VERSION ""

NS_ :

BS_:

BU_: Sound_A Ladegeraet_PAG_PF Motor_EDC17_Pirol PSM_Ant_Derivate GW_Routing_Derivate GW_Applikation_Derivate BMS_Hybrid Getriebe_Derivate LEH_Hybrid Motor_MED17_Hybrid Sound_I Tool Airbag Waehlhebel
VAL_TABLE_ KBI_ASD_Ein_Aus 1 "An" 0 "Aus" ;
VAL_TABLE_ MO_Hybridfahrzeug 3 "PlugIn_Hybrid" 2 "Full_Hybrid" 1 "Mild_Hybrid" 0 "kein_Hybridfahrzeug" ;
VAL_TABLE_ KBI_Automem_inaktiv 1 "Automem nicht aktiv" 0 "Automem aktiv" ;
VAL_TABLE_ QBit 1 "Ersatz-, Init- oder Fehlerwert" 0 "gültiger Wert" ;
VAL_TABLE_ STH_Zusatzheizung 1 "Zuheizer ein" 0 "Zuheizer aus" ;
VAL_TABLE_ xT_Tuer_geoeffnet 1 "Tuer geoeffnet" 0 "Tuer nicht geoeffnet" ;
VAL_TABLE_ KL_Zuheizer_Freigabe 1 "Zuheizerfreigabe" 0 "keine Freigabe Zuheizer" ;
VAL_TABLE_ Fehler_7Bit 127 "Fehler" ;
VAL_TABLE_ AAG_Anhaenger_abgesteckt 1 "Anhaenger wurde bei Kl. 15 aus abgesteckt" ;
VAL_TABLE_ SI_QRS_Mode 0 "QRS_Messmodus_nicht_aktiv" 1 "QRS_Messmodus_aktiv" ;
VAL_TABLE_ KY_WFS_Safe 1 "WFS nicht deaktiviert" ;
VAL_TABLE_ KYL_Warn_kein_Schluessel 0 "kein Schlüssel erkannt" ;
VAL_TABLE_ KY_Keyless_Verbau 1 "Keyless verbaut" 0 "kein Keyless verbaut" ;
VAL_TABLE_ KY_Valet_Parking 1 "Valet Schlüssel erkannt" 0 "kein Valet Schlüssel erkannt" ;
VAL_TABLE_ BCM1_MH_WIV_Schalter 1 "MH offen" 0 "MH geschlossen" ;
VAL_TABLE_ GE_MMom_Status 3 "Änderung mit Sprung" 2 "erhöhender Getriebeeingriff" 1 "reduzierender Getriebeeingriff" 0 "keine Anforderung" ;
VAL_TABLE_ GE_MMom_Soll 1023 "Fehler" 1022 "kein Eingriff" ;
VAL_TABLE_ GE_Status_Kupplung 3 "Fehler" 2 "Kupplung geschlossen" 1 "Kupplung geregelt" 0 "Kupplung geöffnet" ;
VAL_TABLE_ GE_Schaltvorgang 1 "Schaltung aktiv" 0 "keine Schaltung" ;
VAL_TABLE_ WH_Warnung 1 "Waehlhebelfehler_Fahrstufenwechsel_moeglich_(gelbes_Getriebesymbol)" 0 "keine_Anzeige" ;
VAL_TABLE_ WBA_Lampe_Shift_Lock 1 "SL_Lampe_ein" 0 "SL_Lampe_aus" ;
VAL_TABLE_ WBA_Senderkennung 1 "Motor" 0 "Getriebe" ;
VAL_TABLE_ WBA_Getriebevariante 15 "9 Gang Automat Tiptronic" 14 "8 Gang Automat Tiptronic" 13 "7 Gang Automat Tiptronic" 12 "6 Gang Automat Tiptronic" 11 "5 Gang Automat Tiptronic" 10 "tbd." 9 "tbd." 8 "2x3 shift_by_wire" 7 "tbd." 6 "Automat PRNDS" 5 "tbd." 4 "Vorhalt für ASG (Selespeed)" 3 "tbd." 2 "tbd." 1 "Automat PRND" ;
VAL_TABLE_ WBA_eing_Gang 10 "9.Gang" 9 "8.Gang" 8 "7.Gang" 7 "6.Gang" 6 "5.Gang" 5 "4.Gang" 4 "3.Gang" 3 "2.Gang" 2 "1.Gang" 1 "Init" 0 "kein Gang eingelegt / kein Gang empfohlen" ;
VAL_TABLE_ WBA_Blinken 1 "WBA_Blinken" 0 "kein_WBA_Blinken" ;
VAL_TABLE_ WBA_GE_Warnung 7 "Kupplung ueberhitzt, Fahrzeug Stopp (+ rotes Getriebefehlersymbol)" 6 "Kupplung ueberhitzt, Fahrzeug Stopp (+ gelbes Getriebefehlersymbol)" 5 "Wegrollgefahr! P nicht möglich" 4 "Getriebefehler, Weiterfahrt nur in D moeglich, P bei Motor aus" 3 "nur DL-Getriebe: Weiterfahrt nur eingeschränkt möglich. Kein R-Gang" 2 "Weiterfahrt nur eingeschränkt möglich (+ gelbes Getriebefehlersymbol)" 1 "Weiterfahrt möglich (+ gelbes Getriebefehlersymbol)" 0 "keine Anzeige" ;
VAL_TABLE_ WBA_GE_Texte 4 "Achtung_Zeitueberschreitung_P_wird_eingelegt" 3 "Wegrollgefahr_bitte_P_einlegen" 2 "zum_Einlegen_von_R,N,D_Fussbremse_betaetigen_und_Motor_starten" 1 "zum_Einlegen_einer_Fahrstufe_Fussbremse_betaetigen__ShiftLock_Information" 0 "keine Anzeige" ;
VAL_TABLE_ Veraltet_Bit 1 "veraltet" 0 "aktuell" ;
VAL_TABLE_ KBI_Variante_USA 1 "USA-Variante" 0 "keine USA-Variante" ;
VAL_TABLE_ BCM2_Bremsl_durch_ECD 1 "Bremslicht_durch_ECD_aktiv" 0 "Bremslicht_ist_aus" ;
VAL_TABLE_ KL_Thermomanagement 3 "volle Freigabe TMM (kein Heizbedarf)" 2 "mittlere Freigabe TMM" 1 "kleine Freigabe TMM" 0 "keine Freigabe TMM (max. Heizbedarf)" ;
VAL_TABLE_ KL_Atemp_ungef 255 "Fehler" 0 "Initwert" ;
VAL_TABLE_ ACC_Abstandsindex 1023 "Sonderanzeige_Fahrbahn_mit_gruenem_roten_Bereich" 1022 "Sonderanzeige_graue_Fahrbahn" 0 "Sonderanzeige_graue_Fahrbahn" ;
VAL_TABLE_ DGN_Verlernzaehler 255 "ungültiger Zählerstand oder kein gültiger Fahrzyklus" ;
VAL_TABLE_ NMH_GE_N_Haltephase 1 "N_Haltephase_aktiv" 0 "keine_N_Haltephase" ;
VAL_TABLE_ WBA_Schaltschema_Aktiv 1 "Schaltschema_anzeigen" 0 "keine_Anzeige" ;
VAL_TABLE_ MO_HYB_IstStatusK0 3 "Fehler" 2 "zu" 1 "Uebergang" 0 "auf" ;
VAL_TABLE_ NMH_MO_NM_aktiv_HV_Abschaltung 1 "Abschaltung_aktiv" 0 "kein_Nachlauf" ;
VAL_TABLE_ MO_Text_Motorstart 11 "(Belegt bei VW/Audi)" 10 "(Belegt bei VW/Audi)" 9 "(Belegt bei VW/Audi)" 8 "(Vorhalt für Start/Stopp) " 7 "(Vorhalt für Start/Stopp) " 6 "(Vorhalt für Start/Stopp) " 5 "Start/Stopp temporär nicht verfügbar" 4 "Nicht belegt (Vorhalt AUDI)" 15 "Bremse treten" 14 "Waehlhebel in PN Position" 13 "Kupplung betaetigt" 12 "Motor startet" 3 "System fordert Wiederstart" 2 "StartStopp sicherheitsbedingt deaktiviert" 1 "Motor im Stoppbetrieb" 0 "keine Anzeige" ;
VAL_TABLE_ MO_StartStopp_Codiert 1 "StartStopp vorhanden/verbaut" 0 "StartStopp nicht vorhanden/verbaut" ;
VAL_TABLE_ KBI_WV_Entr_Kof 15 "80 Sek." 14 "75 Sek." 13 "70 Sek." 12 "65 Sek." 11 "60 Sek." 10 "55 Sek." 9 "50 Sek." 8 "45 Sek." 7 "40 Sek." 6 "35 Sek." 5 "30 Sek." 4 "25 Sek." 3 "20 Sek." 2 "15 Sek." 1 "10 Sek." 0 "Türen werden nicht entriegelt" ;
VAL_TABLE_ Basiscodierung 1 "Basiscodierung invertiert" 0 "Basiscodierung" ;
VAL_TABLE_ Fehler_Init_13Bit 8191 "Fehlerwert" 8190 "Initwert" ;
VAL_TABLE_ KBI_angez_Geschw 1023 "Fehlerwert" ;
VAL_TABLE_ ESP_SpannungsAnf 1 "Anforderung Spannungswert 1" 0 "keine Anforderung" ;
VAL_TABLE_ LS_Codierung 7 "nicht verwendet" 6 "nicht verwendet" 5 "ACC Hebel, Tiptronic am Lenkrad" 4 "ACC Hebel, keine Tiptronic am Lenkrad" 3 "GRA Hebel, Tiptronic am Lenkrad" 2 "GRA Hebel, keine Tiptronic am Lenkrad" 1 "kein Hebel, Tiptronic am Lenkrad" 0 "kein Hebel, keine Tiptronic am Lenkrad" ;
VAL_TABLE_ LS_Fehler 1 "Fehler Bedienteil" 0 "in Ordnung" ;
VAL_TABLE_ Tippschalter_betaetigt 1 "Tippschalter betaetigt" 0 "Tippschalter nicht betaetigt" ;
VAL_TABLE_ LS_Abbrechen 1 "Tippschalter betätigt" 0 "Tippschalter nicht betätigt" ;
VAL_TABLE_ LS_Hauptschalter 1 "Ein" 0 "Gerastet Aus" ;
VAL_TABLE_ AAG_Bremsl_durch_ECD 1 "Bremslicht durch ECD aktiv" 0 "Bremslicht ist aus" ;
VAL_TABLE_ HU_Fotosensor 511 "Fehler" 510 "Init" 0 "Sensor unbeleuchtet" ;
VAL_TABLE_ PDCC_Last_RKP 255 "Fehlerwert" 0 "Init" ;
VAL_TABLE_ KY_WFS_LZ 3 "LZ 3" 2 "LZ 2" 1 "LZ 1" 0 "nicht def." ;
VAL_TABLE_ Freigabe_angefordert 1 "Freigabe wird angefordert" 0 "Freigabe nicht angefordert" ;
VAL_TABLE_ entriegelt_nicht_entriegelt 1 "entriegelt" 0 "nicht entriegelt" ;
VAL_TABLE_ verriegelt_nicht_verriegelt 1 "verriegelt" 0 "nicht verriegelt" ;
VAL_TABLE_ KY_FFB_Frequenz 3 "868 MHz" 2 "315 MHz" 1 "433 MHz" ;
VAL_TABLE_ KY_ID_Geb_steckt 1 "Schlüssel steckt im Zündschloss" 0 "kein Schlüssel im Zündschloss" ;
VAL_TABLE_ FFB_Taste_betaetigt 1 "Taste am Funkschlüssel betätigt" 0 "Taste nicht betätigt" ;
VAL_TABLE_ authorisiert_nicht_authorisiert 1 "authorisiert" 0 "nicht authorisiert" ;
VAL_TABLE_ OK_Defekt 1 "defekt" 0 "OK" ;
VAL_TABLE_ KL_4_Zonen 1 "4_Zonen_Klimaanlage" 0 "2_Zonen_Klimaanlage" ;
VAL_TABLE_ AB_RGS_Anst 8 "deaktiviert" 7 "aktiv_Niveau_4" 6 "aktiv_Niveau_3" 5 "aktiv_Niveau_2" 4 "aktiv_Niveau_1" ;
VAL_TABLE_ AB_Texte_AKS 2 "AKS_Systemfehler" 1 "AKS_ausgeloest" 0 "keine_AKS_Ausloesung" ;
VAL_TABLE_ SI_NWDF_gueltig 1 "NWDF_wird_unterstuetzt" 0 "NWDF_wird_nicht_unterstuetzt" ;
VAL_TABLE_ SI_NWDF 1 "Ueberwachung_freigeben" 0 "Ueberwachung_nicht_freigeben" ;
VAL_TABLE_ MO_Ext_E_Fahrt_aktiv 1 "Rueckmeldung_E_Taster_ein" 0 "Rueckmeldung_E_Taster_aus" ;
VAL_TABLE_ KL_Geblaese_Status 15 "Fehler" 14 "Init" 10 "Geblaese Stufe 100%" 9 "Geblaese Stufe 90%" 8 "Geblaese Stufe 80%" 7 "Geblaese Stufe 70%" 6 "Geblaese Stufe 60%" 5 "Geblaese Stufe 50%" 4 "Geblaese Stufe 40%" 3 "Geblaese Stufe 30%" 2 "Geblaese Stufe 20%" 1 "Geblaese Stufe 10%" 0 "Geblaese aus" ;
VAL_TABLE_ KBI_Kilometerstand 1048575 "Fehlerwert" 1048574 "Initwert" ;
VAL_TABLE_ Warnmeldung 1 "Warnmeldung" 0 "keine Warnmeldung" ;
VAL_TABLE_ EPB_Anfahrwunsch_erkannt 1 "Anfahrwunsch erkannt" 0 "kein Anfahrwunsch erkannt" ;
VAL_TABLE_ BEM_n_LLA 3 "Stufe 3" 2 "Stufe 2" 1 "Stufe 1" 0 "keine Erhöhung" ;
VAL_TABLE_ ACC_Anhalten 1 "Anhalten gewünscht" 0 "kein Anhalten gewünscht" ;
VAL_TABLE_ ACC_Beeinflussung_ESP 1 "ESP Zwangszuschaltung" 0 "keine ESP Zwangszuschaltung" ;
VAL_TABLE_ ACC_Betaetigung_EPB 1 "EPB Aktuator schliessen" 0 "keine EPB Anforderung" ;
VAL_TABLE_ ACC_Status_ACC 7 "irreversibler_Fehler_im_ACC_System" 6 "reversibler_Fehler_im_ACC_System" 5 "nicht_definiert" 4 "ACC_OVERRIDE" 3 "ACC_AKTIV_regelt" 2 "ACC_STANDBY" 1 "ACC_INIT" 0 "ACC_OFF_Hauptschalter_aus" ;
VAL_TABLE_ ACC_Loeseanforderung 1 "Löseanforderung" 0 "keine Löseanforderung" ;
VAL_TABLE_ ACC_limitierte_Anfahrdyn 1 "Limitierung Anfahrdynamik angefordert" 0 "keine Limitierung" ;
VAL_TABLE_ ACC_Getriebestellung_P 1 "Anforderung P Stellung" 0 "P Stellung nicht angefordert" ;
VAL_TABLE_ ACC_Freigabe_Verzanf 1 "Verzögerungsanforderung freigegeben" 0 "Verzögerungsanforderung nicht freigegeben" ;
VAL_TABLE_ ACC_Freigabe_Momentenanf 1 "Momentenanforderung freigegeben" 0 "Momentenanforderung nicht freigegeben" ;
VAL_TABLE_ SI_T_Mode 1 "Transportmode aktiv" 0 "Transportmode nicht aktiv" ;
VAL_TABLE_ Betaetigt 1 "betätigt" 0 "nicht betätigt" ;
VAL_TABLE_ KBI_MFA_v_Einheit_02 1 "mph" 0 "kmh" ;
VAL_TABLE_ KBI_Einheit_Druck 3 "tbd" 2 "Druckangabe in kPa" 1 "Druckangabe in psi" 0 "Druckangabe in bar" ;
VAL_TABLE_ KL_MSG_valid 1 "Message valid" 0 "Message not valid" ;
VAL_TABLE_ MO_StartStopp_Motorstopp 1 "Motor_Stop_aktiv" 0 "Motor_Stop_inaktiv" ;
VAL_TABLE_ MO_StartStopp_Wiederstart 1 "Wiederstart_aktiv" 0 "Wiederstart_inaktiv" ;
VAL_TABLE_ KBI_Aussen_Temp_gef 255 "Fehler" 254 "Init" 253 "nicht verbaut" ;
VAL_TABLE_ MO_Kraftstoffart 4 "Wasserstoff" 3 "Erdgas" 2 "CNG" 1 "Benzin" 0 "Diesel" ;
VAL_TABLE_ AB_Sitzpos_Sens 3 "Sitz vorne" 2 "Sitz nicht vorne" 1 "Fehler" 0 "nicht verfügbar" ;
VAL_TABLE_ AB_Gurtschloss 3 "gesteckt" 2 "nicht_gesteckt" 1 "nicht_verfügbar (Fehler oder Init)" 0 "nicht_verbaut" ;
VAL_TABLE_ FAS_Wunschgeschw 1023 "nicht definiert" 1022 "keine Anzeige" ;
VAL_TABLE_ FAS_Texte_Primaeranz 66 "ESP PASSIV !" 65 "Bremse haelt !" 64 "Bremse ueberhitzt !" 63 "LIM FEHLER" 62 "LIM PASSIV" 61 "LIM AKTIV " 60 "LIM AUS" 59 "Kupplung betaetigt" 58 "Bremse betaetigen !" 57 "ACC haelt an !" 56 "ACC Fehler" 55 "ACC reinigen" 54 "ACC startet" 53 "ACC aus" 52 "SET / 'GRA Symbol' xxx km/h / mph" 51 "SET / 'GRA Symbol'___xxx km/h / mph" 50 "Stehendes Objekt voraus" 49 "Steigung zu gross" 48 "Uebernehmen !" 47 "braking guard aus" 46 "braking guard aus " 45 "braking guard Bremsruck" 44 "HDC aktiv" 43 "Tempolimit Ende XXX km/h / mph" 42 "Ortsende XXX km/h / mph" 41 "Ortsanfang XXX km/h / mph" 40 "Abbiegeassistent" 39 "Tempolimit aus" 38 "Kurvenassistent aus" 37 "Drehzahl !" 36 "Schalthebelposition !" 35 "Fahrer Gurtschloss offen !" 34 "Tuer offen !" 33 "Ungueltiger Anfahrbefehl" 32 "Im Stand nicht moeglich" 31 "Fahrzeug verloren" 30 "Anfahren bestaetigen" 29 "Lenkradwinkel" 28 "XXX km/h / mph (Schriftart 2)" 27 "--- km/h / mph" 26 "!" 25 "Symbol 'Eieruhr'" 24 "ACC Abschaltung" 23 "Kurve XXX km/h / mph" 22 "Tempolimit XXX km/h / mph" 21 "VDA ACC-Symbol YYY km/h / mph" 20 "Waehlhebelposition !" 19 "Geschwindigkeitsgrenze" 18 "Parkbremse !" 17 "Herunterschalten" 16 "ESP Eingriff" 15 "Hochschalten" 14 "o  o  o" 13 "ACC nicht verfuegbar" 12 "ACC Sensor Sicht !" 11 "keine Abstandsregelung" 10 "ACC bereit" 9 "Auto_ _ _ _Auto Gong (durchgestrichen)" 8 "Auto_ _ _Auto_ Gong (durchgestrichen)" 7 "Auto_ _Auto_ _ Gong (durchgestrichen)" 6 "Auto_Auto_ _ _ Gong (durchgestrichen)" 5 "Auto_ _ _ _Auto" 4 "Auto_ _ _Auto_" 3 "Auto_ _Auto_ _" 2 "Auto_Auto_ _ _" 1 "ACC nicht verfuegbar !" 0 "keine Anzeige " ;
VAL_TABLE_ FAS_Status_Prim_Anz 3 "Farbe 3 (typisch 'gelb')" 2 "Farbe 2 (typisch 'rot')" 1 "Farbe 1 (typisch 'grün')" 0 "Symbol nicht beleuchtet" ;
VAL_TABLE_ FAS_Status_Anzeige 7 "ACC/GRA irreversibel aus" 6 "ACC reversibel aus (nicht bei GRA)" 5 "frei" 4 "ACC/GRA im Hintergrund (übertreten)" 3 "ACCGRA aktiv" 2 "ACC/GRA passiv" 1 "ACC in Init (nicht bei GRA)" 0 "ACC/GRA Hauptschalter aus" ;
VAL_TABLE_ KD_Fehler 1 "mind. ein KD-Fehler vorhanden" 0 "kein KD-Fehler" ;
VAL_TABLE_ AB_Crashdaten 1 "Crashdaten gespeichert" 0 "keine Daten gespeichert" ;
VAL_TABLE_ GE_poshebel_VAG 15 "Fehler" 14 "Tippfunktion" 13 "frei" 12 "frei" 11 "frei" 10 "frei" 9 "Position S" 8 "Position D" 7 "Position N" 6 "Position R" 5 "Position P" 4 "frei" 3 "frei" 2 "frei" 1 "Init" 0 "Zwischenstellung" ;
VAL_TABLE_ KL_St_Heizkreis 1 "Wasserventil geschlossen" 0 "Wasserventil geoeffnet" ;
VAL_TABLE_ FSAktivBit 1 "Fehler speichern" 0 "keine Fehler speichern" ;
VAL_TABLE_ KL_St_Atemp 3 "Unterbrechung" 4 "Sensorsignal unplausibel" 2 "Kurzschluss gegen Spg > 5V" 1 "Kurzschluss nach Masse" 0 "Kein Fehler" ;
VAL_TABLE_ MO_Handshake_STH 1 "EKP-Ansteuerung durch STH-Anforderung" 0 "keine EKP-Ansteuerung durch STH-Anforderung" ;
VAL_TABLE_ MO_StSt_Status 3 "Mindestens ein weiches oder hartes Veto liegt vor" 2 "Alle Vetos besagen,dass langfristig kein Motorlauf notwendig ist" 1 "Reversible Abschaltung aufgrund sicherheitsrelevanter Funktionen oder über einen Taster" 0 "Fehlerstatus erkannt oder Sicherheitsabschaltung aktiv" ;
VAL_TABLE_ StSt_Info 3 "Systemfehler" 2 "Motoranlauf zwingend notwendig (Startanforderung)" 1 "Motoranlauf nicht zwingend notwendig (Stoppverbot, keine Startanforderung, evtl. Komforteinbussen)" 0 "Motorlauf langfristig nicht notwendig (Stoppfreigabe)" ;
VAL_TABLE_ GW_STH_Anf 3 "STH Timer aktiv" 2 "Standheizung AUS" 1 "Standheizung EIN" 0 "keine EIN/AUS-Anf/kein Timer akt" ;
VAL_TABLE_ KBI_Einheit_Verbrauch 1 "mpg USA" 2 "Liter/100km" 0 "mpg UK" 3 "km/Liter" ;
VAL_TABLE_ KBI_Einheit_Volumen 3 "reserviert" 0 "Liter" 1 "Gallonen_UK" 2 "Gallonen_USA" ;
VAL_TABLE_ St_PAO_Leuchte 3 "ungültig" 2 "defekt" 1 "ein" 0 "aus" ;
VAL_TABLE_ verfuegbar 1 "verfuegbar" 0 "nicht verfuegbar" ;
VAL_TABLE_ EPB_Freig_Verzoeg_Anf 0 "Verzögerungsanforderung nicht freigegeben" 1 "Verzögerungsanforderung freigegeben" ;
VAL_TABLE_ EPB_Fehlerstatus 2 "EPB temporär nicht verfügbar - Spannen nicht möglich da Fzg. in Fahrt" 1 "EPB temporär nicht verfügbar - AVH darf nicht aktiv werden, sondern muss bei AVH-Anforderung warnen" 3 "Fehler in EPB - AVH darf von ESP nicht ausgeführt werden" 0 "kein Fehler in EPB - AVH darf von ESP ausgeführt werden" ;
VAL_TABLE_ AB_W_AWS_S 1 "Störung AWS (Sitz verspannt)" 0 "keine Störung" ;
VAL_TABLE_ Gurtwarnung 1 "Gurtwarnung auslösen" 0 "keine Warnung" ;
VAL_TABLE_ AB_PAO_Info 7 "AB BF akt.d.AWS,Schalt. a. AUTO" 6 "AB BF deakt.d.AWS,Schalt.a. AUTO" 5 "AB BF deakt.d.Schalt,AWS o.Einf." 4 "AB BF akt.d. AWS,kein Schalt.v." 3 "AB BF deakt.d.AWS,kein Schalt.v." 2 "AB BF akt.d.Schalt,kein AWS verb" 1 "AB BF deakt.d.Schalt,kein AWS v." 0 "Default / Initialwert" ;
VAL_TABLE_ AB_AWS_Zustand 7 "Fehler" 6 "Störung (Sitz verspannt)" 5 "schwerer Erwachsener" 4 "mittelschwerer Erwachsener" 3 "leichter Erwachener" 2 "Kind" 1 "Sitz leer" 0 "Default / Initialwert" ;
VAL_TABLE_ Klimastyles 3 "nicht definiert" 2 "strong" 1 "medium" 0 "soft" ;
VAL_TABLE_ Ein_Aus 1 "ein" 0 "aus" ;
VAL_TABLE_ KBI_Tankwarnung 1 "Tankwarnung aktiv" 0 "Tankwarnung nicht aktiv" ;
VAL_TABLE_ STH_Ansteuerung 3 "Heizleistung reduziert" 2 "Ein mit Motorvorwaermung" 1 "Ein" 0 "Aus" ;
VAL_TABLE_ Fzg_Antrieb 15 "Reserve" 14 "Reserve" 13 "Reserve" 12 "Reserve" 11 "Reserve" 10 "Reserve" 9 "Reserve" 8 "Reserve" 7 "Reserve" 6 "Reserve" 5 "Reserve" 4 "Reserve" 3 "Reserve" 2 "Reserve" 1 "Vierradantrieb" 0 "Zweiradantrieb" ;
VAL_TABLE_ SI_CAN_ 1 "Busruhe" 0 "keine Busruhe" ;
VAL_TABLE_ Diag_Rx_PCItype 3 "FlowControl (FC)" 2 "ConsecutiveFrame (CF)" 1 "FirstFrame (FF)" 0 "SingleFrame (SF)" ;
VAL_TABLE_ S_Brems 3 "betätigt" 2 "unplausibel" 1 "Reserve" 0 "nicht betätigt" ;
VAL_TABLE_ GE_poshebel 15 "Fehler" 14 "Manuellprog." 13 "kurzz. Manuellprog." 12 "frei" 11 "frei" 10 "frei" 9 "frei" 8 "Pos_P" 7 "Pos_R" 6 "Pos_N" 5 "Pos_D" 4 "Blinken_Pos_P" 3 "Blinken_Pos_R" 2 "Blinken_Pos_N" 1 "Blinken_Pos_D" 0 "Zwischenst." ;
VAL_TABLE_ magnet_pos 3 "nicht definiert" 2 "aktive Magnetstellung" 1 "Zwischenstellung" 0 "passive Magnetstellung" ;
VAL_TABLE_ KBI_Einheit_Sprache 255 "Fehler" 13 "Russisch" 12 "Portugiesisch" 11 "Türkisch" 10 "Schwedisch" 9 "Dänisch" 8 "Holländisch" 7 "Chinesisch (Simplified Chinese)" 6 "Japanisch (Katakana)" 5 "Italienisch" 4 "Spanisch" 3 "Französisch" 2 "US-Englisch" 1 "Englisch" 0 "Deutsch" ;
VAL_TABLE_ Sollverbau 1 "SG verbaut" 0 "SG nicht verbaut" ;
VAL_TABLE_ Schaltbeinfl 1 "Schaltverbot" 0 "keine_Beeinflussung" ;
VAL_TABLE_ Leuchten 1 "Leuchte an" 0 "Leuchte aus" ;
VAL_TABLE_ Lenker 1 "Rechtslenker" 0 "Linkslenker" ;
VAL_TABLE_ Karosserie_Typ 15 "Reserve" 14 "Reserve" 13 "Reserve" 12 "Reserve" 11 "Reserve" 10 "Reserve" 9 "Reserve" 8 "Reserve" 7 "Reserve" 6 "Reserve" 5 "Reserve" 4 "Reserve" 3 "Reserve" 2 "Targa" 1 "Cabrio" 0 "Coupe" ;
VAL_TABLE_ Baureihe 15 "Reserve" 14 "Reserve" 13 "Reserve" 12 "Reserve" 11 "Reserve" 10 "Reserve" 9 "Reserve" 8 "Reserve" 7 "Reserve" 6 "Reserve" 5 "Reserve" 4 "Reserve" 3 "Boxster" 2 "Carrera" 1 "Cayenne" 0 "Panamera" ;
VAL_TABLE_ Fehler_8Bit 255 "Fehler" ;
VAL_TABLE_ Fehler_1Bit 1 "Fehler" 0 "kein Fehler" ;
VAL_TABLE_ An_Aus 1 "an" 0 "aus" ;
VAL_TABLE_ Aktiv 1 "Aktiv" 0 "Inaktiv" ;
VAL_TABLE_ Taster 1 "Taster betätigt" 0 "Taster nicht betätigt" ;
VAL_TABLE_ B_Notbrems 1 "Notbremsung aktiv" 0 "Notbremsung nicht aktiv" ;

BO_ 3221225472 VECTOR__INDEPENDENT_SIG_MSG: 0 Vector__XXX
 SG_ KBI_Trip_E_Std : 0|15@1+ (1,0) [0|9999] "Unit_Hours" Vector__XXX
 SG_ KBI_Trip_E_Min : 0|6@1+ (1,0) [0|59] "Unit_Minut" Vector__XXX
 SG_ KBI_Service_km : 0|10@1+ (100,0) [0|102100] "" Vector__XXX
 SG_ KBI_Service_Zeit : 0|11@1+ (1,0) [0|2045] "" Vector__XXX
 SG_ KBI_Service_Typ : 0|2@1+ (1,0) [0|3] "" Vector__XXX
 SG_ DEV_BMS_Resp_07_Data : 0|64@1+ (1,0) [0|1.84467440737096E+019] "" Vector__XXX
 SG_ DEV_BMS_Resp_06_Data : 0|64@1+ (1,0) [0|1.84467440737096E+019] "" Vector__XXX
 SG_ DEV_BMS_Resp_05_Data : 0|64@1+ (1,0) [0|1.84467440737096E+019] "" Vector__XXX
 SG_ Mo_HVEM_HV_Abschaltanf : 0|1@1+ (1,0) [0|1] "" Vector__XXX
 SG_ MO_HVEM_HV_Maxleistung : 0|8@1+ (0.05,0) [0|12.5] "Unit_KiloWatt" Vector__XXX
 SG_ HVEM_Istleistung_Nebenverbrauch : 0|8@1+ (0.05,0) [0|12.5] "Unit_KiloWatt" Vector__XXX
 SG_ BMS_TauKuehlmittel__Temp_ : 0|8@1+ (1,0) [0|0] "" Vector__XXX
 SG_ SVB_IVB_FS_Fond : 0|1@1+ (1,0) [0|1] "" Vector__XXX
 SG_ SVB_IVB_FS : 0|1@1+ (1,0) [0|1] "" Vector__XXX
 SG_ SVB_IVB_BFS_Fond : 0|1@1+ (1,0) [0|1] "" Vector__XXX
 SG_ SVB_IVB_BFS : 0|1@1+ (1,0) [0|1] "" Vector__XXX
 SG_ SVB_KameraLow_FLA : 0|1@1+ (1,0) [0|1] "" Vector__XXX
 SG_ AWV_Halten : 0|1@1+ (1,0) [0|1] "" Vector__XXX
 SG_ ISO_Getriebe_01_Req_Data : 0|64@1+ (1,0) [0|1] "" Vector__XXX
 SG_ NMH_GW_VNSM_VC5 : 0|1@1+ (1,0) [0|1] "" Vector__XXX
 SG_ NMH_GW_VNSM_Wfpf : 0|1@1+ (1,0) [0|1] "" Vector__XXX

BO_ 1728 NMH_Gateway: 7 GW_Applikation_Derivate
 SG_ NMH_GW_Start_1 : 0|1@1+ (1,0) [0|1] ""  Ladegeraet_PAG_PF,Getriebe_Derivate,Motor_MED17_Hybrid,Motor_EDC17_Pirol,LEH_Hybrid,BMS_Hybrid
 SG_ NMH_GW_Start_2 : 1|1@1+ (1,0) [0|1] "" Vector__XXX
 SG_ NMH_GW_Normal_Mode_1 : 2|1@1+ (1,0) [0|1] "" Vector__XXX
 SG_ NMH_GW_Normal_Mode_2 : 3|1@1+ (1,0) [0|1] "" Vector__XXX
 SG_ NMH_GW_Car_WakeUp : 6|1@1+ (1,0) [0|1] "" Vector__XXX
 SG_ NMH_GW_Per_WakeUp : 8|5@1+ (1,0) [0|31] "" Vector__XXX
 SG_ NMH_GW_Fkt_WakeUp : 13|3@1+ (1,0) [0|7] "" Vector__XXX
 SG_ NMH_GW_NM_aktiv_Klemme_15 : 16|1@1+ (1,0) [0|1] "" Vector__XXX
 SG_ NMH_GW_NM_aktiv_Diagnose : 17|1@1+ (1,0) [0|1] "" Vector__XXX
 SG_ NMH_GW_NM_aktiv_Start : 18|1@1+ (1,0) [0|1] "" Vector__XXX
 SG_ NMH_GW_NM_aktiv_BDM : 19|1@1+ (1,0) [0|1] "" Vector__XXX
 SG_ NMH_GW_NM_aktiv_Warnblinken : 20|1@1+ (1,0) [0|1] "" Vector__XXX
 SG_ NMH_GW_NM_aktiv_ESP : 21|1@1+ (1,0) [0|1] "" Vector__XXX
 SG_ NMH_GW_NM_aktiv_EMP : 22|1@1+ (1,0) [0|1] "" Vector__XXX
 SG_ NMH_GW_Abschaltstufe_3 : 24|1@1+ (1,0) [0|1] "" Vector__XXX
 SG_ NMH_GW_SG_Fehlerdauer : 25|1@1+ (1,0) [0|1] "" Vector__XXX
 SG_ NMH_GW_STH_Wakeup : 26|1@1+ (1,0) [0|1] "" Vector__XXX
 SG_ NMH_GW_NL_Diagnose : 27|1@1+ (1,0) [0|1] "" Vector__XXX
 SG_ NM_GW_Signalfehler : 32|1@1+ (1,0) [0|1] "" Vector__XXX
 SG_ NMH_GW_TimeOut_Fehler : 33|1@1+ (1,0) [0|1] "" Vector__XXX
 SG_ NMH_GW_CAN_Diag_deaktiv : 34|1@1+ (1,0) [0|1] "" Vector__XXX
 SG_ NMH_GW_KompSchutz : 35|1@1+ (1,0) [0|1] "" Vector__XXX
 SG_ NMH_GW_Mute_Mode : 36|1@1+ (1,0) [0|1] "" Vector__XXX
 SG_ NMH_GW_Transport_Mode : 37|1@1+ (1,0) [0|1] "" Vector__XXX
 SG_ NMH_GW_Abschaltstufe_aktiv : 38|1@1+ (1,0) [0|1] "" Vector__XXX
 SG_ NMH_GW_Eindraht_Fehler : 39|1@1+ (1,0) [0|1] "" Vector__XXX
 SG_ NMH_GW_ACAN : 40|1@1+ (1,0) [0|1] "" Vector__XXX
 SG_ NMH_GW_KombiCAN : 41|1@1+ (1,0) [0|1] "" Vector__XXX
 SG_ NMH_GW_KomfortCAN : 42|1@1+ (1,0) [0|1] "" Vector__XXX
 SG_ NMH_GW_Infotainment : 43|1@1+ (1,0) [0|1] "" Vector__XXX
 SG_ NMH_GW_Fahrwerk : 44|1@1+ (1,0) [0|1] "" Vector__XXX
 SG_ NMH_GW_WakeUp_CAN_Bus : 45|3@1+ (1,0) [0|7] "" Vector__XXX

BO_ 1327 ESP_27: 8 PSM_Ant_Derivate
 SG_ OBD_Fehler_Laengsbeschleunigung : 14|4@1+ (1,0) [0|15] ""  Motor_MED17_Hybrid
 SG_ OBD_Fehler_Vordrucksensor : 12|2@1+ (1,0) [0|3] ""  Motor_MED17_Hybrid

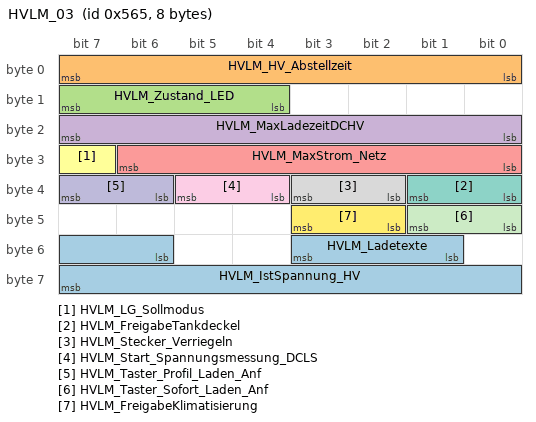
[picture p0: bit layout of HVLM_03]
BO_ 1381 HVLM_03: 8 Ladegeraet_PAG_PF
 SG_ HVLM_IstSpannung_HV : 54|10@1+ (1,0) [0|1021] "Unit_Volt"  GW_Applikation_Derivate,GW_Routing_Derivate
 SG_ HVLM_HV_Abstellzeit : 0|8@1+ (4,0) [0|1012] "Unit_Minut"  GW_Routing_Derivate
 SG_ HVLM_Zustand_LED : 12|4@1+ (1,0) [0|15] ""  GW_Routing_Derivate
 SG_ HVLM_MaxLadezeitDCHV : 16|8@1+ (10,0) [0|2530] "Unit_Minut"  GW_Routing_Derivate
 SG_ HVLM_MaxStrom_Netz : 24|7@1+ (0.5,0) [0|62.5] "Unit_Amper"  GW_Routing_Derivate
 SG_ HVLM_LG_Sollmodus : 31|1@1+ (1,0) [0|1] ""  GW_Routing_Derivate
 SG_ HVLM_FreigabeTankdeckel : 32|2@1+ (1,0) [0|3] ""  GW_Routing_Derivate
 SG_ HVLM_Stecker_Verriegeln : 34|2@1+ (1,0) [0|3] ""  GW_Routing_Derivate
 SG_ HVLM_Start_Spannungsmessung_DCLS : 36|2@1+ (1,0) [0|3] ""  GW_Routing_Derivate
 SG_ HVLM_Taster_Profil_Laden_Anf : 38|2@1+ (1,0) [0|3] ""  GW_Routing_Derivate
 SG_ HVLM_Taster_Sofort_Laden_Anf : 40|2@1+ (1,0) [0|3] ""  GW_Routing_Derivate
 SG_ HVLM_FreigabeKlimatisierung : 42|2@1+ (1,0) [0|3] ""  GW_Routing_Derivate
 SG_ HVLM_Ladetexte : 49|3@1+ (1,0) [0|7] ""  GW_Routing_Derivate

BO_ 1534 Kombi_18_PAG: 8 GW_Routing_Derivate
 SG_ KBI_Set_Timer_MUX M : 0|3@1+ (1,0) [0|7] ""  Ladegeraet_PAG_PF
 SG_ KBI_Set_Timer_1_Jahr m1 : 3|7@1+ (1,2000) [2000|2125] "Unit_Year"  Ladegeraet_PAG_PF
 SG_ KBI_Set_Timer_2_Jahr m2 : 3|7@1+ (1,2000) [2000|2125] "Unit_Year"  Ladegeraet_PAG_PF
 SG_ KBI_Set_Timer_3_Jahr m3 : 3|7@1+ (1,2000) [2000|2125] "Unit_Year"  Ladegeraet_PAG_PF
 SG_ KBI_Set_Timer_4_Jahr m4 : 3|7@1+ (1,2000) [2000|2125] "Unit_Year"  Ladegeraet_PAG_PF
 SG_ KBI_Set_Timer_1_Minute m1 : 10|6@1+ (1,0) [0|59] "Unit_Minut"  Ladegeraet_PAG_PF
 SG_ KBI_Set_Timer_2_Minute m2 : 10|6@1+ (1,0) [0|59] "Unit_Minut"  Ladegeraet_PAG_PF
 SG_ KBI_Set_Timer_3_Minute m3 : 10|6@1+ (1,0) [0|59] "Unit_Minut"  Ladegeraet_PAG_PF
 SG_ KBI_Set_Timer_4_Minute m4 : 10|6@1+ (1,0) [0|59] "Unit_Minut"  Ladegeraet_PAG_PF
 SG_ KBI_Set_Timer_1_Monat m1 : 16|4@1+ (1,0) [1|12] "Unit_Month"  Ladegeraet_PAG_PF
 SG_ KBI_Set_Timer_2_Monat m2 : 16|4@1+ (1,0) [1|12] "Unit_Month"  Ladegeraet_PAG_PF
 SG_ KBI_Set_Timer_3_Monat m3 : 16|4@1+ (1,0) [1|12] "Unit_Month"  Ladegeraet_PAG_PF
 SG_ KBI_Set_Timer_4_Monat m4 : 16|4@1+ (1,0) [1|12] "Unit_Month"  Ladegeraet_PAG_PF
 SG_ KBI_Set_Timer_1_Stunde m1 : 20|5@1+ (1,0) [0|23] "Unit_Hours"  Ladegeraet_PAG_PF
 SG_ KBI_Set_Timer_2_Stunde m2 : 20|5@1+ (1,0) [0|23] "Unit_Hours"  Ladegeraet_PAG_PF
 SG_ KBI_Set_Timer_3_Stunde m3 : 20|5@1+ (1,0) [0|23] "Unit_Hours"  Ladegeraet_PAG_PF
 SG_ KBI_Set_Timer_4_Stunde m4 : 20|5@1+ (1,0) [0|23] "Unit_Hours"  Ladegeraet_PAG_PF
 SG_ KBI_Set_Timer_1_Tag m1 : 25|5@1+ (1,0) [1|31] "Unit_Day"  Ladegeraet_PAG_PF
 SG_ KBI_Set_Timer_2_Tag m2 : 25|5@1+ (1,0) [1|31] "Unit_Day"  Ladegeraet_PAG_PF
 SG_ KBI_Set_Timer_3_Tag m3 : 25|5@1+ (1,0) [1|31] "Unit_Day"  Ladegeraet_PAG_PF
 SG_ KBI_Set_Timer_4_Tag m4 : 25|5@1+ (1,0) [1|31] "Unit_Day"  Ladegeraet_PAG_PF
 SG_ KBI_Set_Timer_1_Laden m1 : 30|1@1+ (1,0) [0|1] ""  Ladegeraet_PAG_PF
 SG_ KBI_Set_Timer_2_Laden m2 : 30|1@1+ (1,0) [0|1] ""  Ladegeraet_PAG_PF
 SG_ KBI_Set_Timer_3_Laden m3 : 30|1@1+ (1,0) [0|1] ""  Ladegeraet_PAG_PF
 SG_ KBI_Set_Timer_4_Laden m4 : 30|1@1+ (1,0) [0|1] ""  Ladegeraet_PAG_PF
 SG_ KBI_Set_Timer_1_Vorklima m1 : 31|1@1+ (1,0) [0|1] ""  Ladegeraet_PAG_PF
 SG_ KBI_Set_Timer_2_Vorklima m2 : 31|1@1+ (1,0) [0|1] ""  Ladegeraet_PAG_PF
 SG_ KBI_Set_Timer_3_Vorklima m3 : 31|1@1+ (1,0) [0|1] ""  Ladegeraet_PAG_PF
 SG_ KBI_Set_Timer_4_Vorklima m4 : 31|1@1+ (1,0) [0|1] ""  Ladegeraet_PAG_PF
 SG_ KBI_Set_Timer_1_Zyklus_Mo m1 : 32|1@1+ (1,0) [0|1] ""  Ladegeraet_PAG_PF
 SG_ KBI_Set_Timer_2_Zyklus_Mo m2 : 32|1@1+ (1,0) [0|1] ""  Ladegeraet_PAG_PF
 SG_ KBI_Set_Timer_3_Zyklus_Mo m3 : 32|1@1+ (1,0) [0|1] ""  Ladegeraet_PAG_PF
 SG_ KBI_Set_Timer_4_Zyklus_Mo m4 : 32|1@1+ (1,0) [0|1] ""  Ladegeraet_PAG_PF
 SG_ KBI_Set_Timer_1_Zyklus_Di m1 : 33|1@1+ (1,0) [0|1] ""  Ladegeraet_PAG_PF
 SG_ KBI_Set_Timer_2_Zyklus_Di m2 : 33|1@1+ (1,0) [0|1] ""  Ladegeraet_PAG_PF
 SG_ KBI_Set_Timer_3_Zyklus_Di m3 : 33|1@1+ (1,0) [0|1] ""  Ladegeraet_PAG_PF
 SG_ KBI_Set_Timer_4_Zyklus_Di m4 : 33|1@1+ (1,0) [0|1] ""  Ladegeraet_PAG_PF
 SG_ KBI_Set_Timer_1_Zyklus_Mi m1 : 34|1@1+ (1,0) [0|1] ""  Ladegeraet_PAG_PF
 SG_ KBI_Set_Timer_2_Zyklus_Mi m2 : 34|1@1+ (1,0) [0|1] ""  Ladegeraet_PAG_PF
 SG_ KBI_Set_Timer_3_Zyklus_Mi m3 : 34|1@1+ (1,0) [0|1] ""  Ladegeraet_PAG_PF
 SG_ KBI_Set_Timer_4_Zyklus_Mi m4 : 34|1@1+ (1,0) [0|1] ""  Ladegeraet_PAG_PF
 SG_ KBI_Set_Timer_1_Zyklus_Do m1 : 35|1@1+ (1,0) [0|1] ""  Ladegeraet_PAG_PF
 SG_ KBI_Set_Timer_2_Zyklus_Do m2 : 35|1@1+ (1,0) [0|1] ""  Ladegeraet_PAG_PF
 SG_ KBI_Set_Timer_3_Zyklus_Do m3 : 35|1@1+ (1,0) [0|1] ""  Ladegeraet_PAG_PF
 SG_ KBI_Set_Timer_4_Zyklus_Do m4 : 35|1@1+ (1,0) [0|1] ""  Ladegeraet_PAG_PF
 SG_ KBI_Set_Timer_1_Zyklus_Fr m1 : 36|1@1+ (1,0) [0|1] ""  Ladegeraet_PAG_PF
 SG_ KBI_Set_Timer_2_Zyklus_Fr m2 : 36|1@1+ (1,0) [0|1] ""  Ladegeraet_PAG_PF
 SG_ KBI_Set_Timer_3_Zyklus_Fr m3 : 36|1@1+ (1,0) [0|1] ""  Ladegeraet_PAG_PF
 SG_ KBI_Set_Timer_4_Zyklus_Fr m4 : 36|1@1+ (1,0) [0|1] ""  Ladegeraet_PAG_PF
 SG_ KBI_Set_Timer_1_Zyklus_Sa m1 : 37|1@1+ (1,0) [0|1] ""  Ladegeraet_PAG_PF
 SG_ KBI_Set_Timer_2_Zyklus_Sa m2 : 37|1@1+ (1,0) [0|1] ""  Ladegeraet_PAG_PF
 SG_ KBI_Set_Timer_3_Zyklus_Sa m3 : 37|1@1+ (1,0) [0|1] ""  Ladegeraet_PAG_PF
 SG_ KBI_Set_Timer_4_Zyklus_Sa m4 : 37|1@1+ (1,0) [0|1] ""  Ladegeraet_PAG_PF
 SG_ KBI_Set_Timer_1_Zyklus_So m1 : 38|1@1+ (1,0) [0|1] ""  Ladegeraet_PAG_PF
 SG_ KBI_Set_Timer_2_Zyklus_So m2 : 38|1@1+ (1,0) [0|1] ""  Ladegeraet_PAG_PF
 SG_ KBI_Set_Timer_3_Zyklus_So m3 : 38|1@1+ (1,0) [0|1] ""  Ladegeraet_PAG_PF
 SG_ KBI_Set_Timer_4_Zyklus_So m4 : 38|1@1+ (1,0) [0|1] ""  Ladegeraet_PAG_PF
 SG_ KBI_Set_Timer_1_Zyklus_WH m1 : 39|1@1+ (1,0) [0|1] ""  Ladegeraet_PAG_PF
 SG_ KBI_Set_Timer_2_Zyklus_WH m2 : 39|1@1+ (1,0) [0|1] ""  Ladegeraet_PAG_PF
 SG_ KBI_Set_Timer_3_Zyklus_WH m3 : 39|1@1+ (1,0) [0|1] ""  Ladegeraet_PAG_PF
 SG_ KBI_Set_Timer_4_Zyklus_WH m4 : 39|1@1+ (1,0) [0|1] ""  Ladegeraet_PAG_PF
 SG_ KBI_MOD_Privatsphaere : 60|2@1+ (1,0) [0|3] "" Vector__XXX
 SG_ KBI_STH_Status : 62|2@1+ (1,0) [0|3] ""  Ladegeraet_PAG_PF

BO_ 1631 Motor_16: 8 Motor_MED17_Hybrid
 SG_ MO_Energieinhalt_BMS : 36|12@1+ (25,0) [0|102325] "Unit_Watt"  BMS_Hybrid

BO_ 1398 MOD_01_PAG: 8 GW_Routing_Derivate
 SG_ MOD_Privatsphaere : 63|1@1+ (1,0) [0|1] "" Vector__XXX
 SG_ MOD_Set_Timer_5_Jahr m5 : 3|7@1+ (1,2000) [2000|2125] "Unit_Year" Vector__XXX
 SG_ MOD_Set_Timer_6_Jahr m6 : 3|7@1+ (1,2000) [2000|2125] "Unit_Year" Vector__XXX
 SG_ MOD_Set_Timer_5_Minute m5 : 10|6@1+ (1,0) [0|59] "Unit_Minut" Vector__XXX
 SG_ MOD_Set_Timer_6_Minute m6 : 10|6@1+ (1,0) [0|59] "Unit_Minut" Vector__XXX
 SG_ MOD_Set_Timer_5_Monat m5 : 16|4@1+ (1,0) [1|12] "Unit_Month" Vector__XXX
 SG_ MOD_Set_Timer_6_Monat m6 : 16|4@1+ (1,0) [1|12] "Unit_Month" Vector__XXX
 SG_ MOD_Set_Timer_5_Stunde m5 : 20|5@1+ (1,0) [0|23] "Unit_Hours" Vector__XXX
 SG_ MOD_Set_Timer_6_Stunde m6 : 20|5@1+ (1,0) [0|23] "Unit_Hours" Vector__XXX
 SG_ MOD_Set_Timer_5_Tag m5 : 25|5@1+ (1,0) [1|31] "Unit_Day" Vector__XXX
 SG_ MOD_Set_Timer_6_Tag m6 : 25|5@1+ (1,0) [1|31] "Unit_Day" Vector__XXX
 SG_ MOD_Set_Timer_5_Vorklima m5 : 31|1@1+ (1,0) [0|1] "" Vector__XXX
 SG_ MOD_Set_Timer_6_Vorklima m6 : 31|1@1+ (1,0) [0|1] "" Vector__XXX
 SG_ MOD_Set_Timerladen : 57|1@1+ (1,0) [0|1] ""  Ladegeraet_PAG_PF
 SG_ MOD_Set_Sofortladen : 59|1@1+ (1,0) [0|1] ""  Ladegeraet_PAG_PF
 SG_ MOD_Set_Timer_4_Jahr m4 : 3|7@1+ (1,2000) [2000|2125] "Unit_Year"  Ladegeraet_PAG_PF
 SG_ MOD_Set_Timer_4_Minute m4 : 10|6@1+ (1,0) [0|59] "Unit_Minut"  Ladegeraet_PAG_PF
 SG_ MOD_Set_Timer_4_Monat m4 : 16|4@1+ (1,0) [1|12] "Unit_Month"  Ladegeraet_PAG_PF
 SG_ MOD_Set_Timer_4_Stunde m4 : 20|5@1+ (1,0) [0|23] "Unit_Hours"  Ladegeraet_PAG_PF
 SG_ MOD_Set_Timer_4_Tag m4 : 25|5@1+ (1,0) [1|31] "Unit_Day"  Ladegeraet_PAG_PF
 SG_ MOD_Set_Timer_4_Laden m4 : 30|1@1+ (1,0) [0|1] ""  Ladegeraet_PAG_PF
 SG_ MOD_Set_Timer_4_Vorklima m4 : 31|1@1+ (1,0) [0|1] ""  Ladegeraet_PAG_PF
 SG_ MOD_Set_Timer_4_Zyklus_Mo m4 : 32|1@1+ (1,0) [0|1] ""  Ladegeraet_PAG_PF
 SG_ MOD_Set_Timer_4_Zyklus_Di m4 : 33|1@1+ (1,0) [0|1] ""  Ladegeraet_PAG_PF
 SG_ MOD_Set_Timer_4_Zyklus_Mi m4 : 34|1@1+ (1,0) [0|1] ""  Ladegeraet_PAG_PF
 SG_ MOD_Set_Timer_4_Zyklus_Do m4 : 35|1@1+ (1,0) [0|1] ""  Ladegeraet_PAG_PF
 SG_ MOD_Set_Timer_4_Zyklus_Fr m4 : 36|1@1+ (1,0) [0|1] ""  Ladegeraet_PAG_PF
 SG_ MOD_Set_Timer_4_Zyklus_Sa m4 : 37|1@1+ (1,0) [0|1] ""  Ladegeraet_PAG_PF
 SG_ MOD_Set_Timer_4_Zyklus_So m4 : 38|1@1+ (1,0) [0|1] ""  Ladegeraet_PAG_PF
 SG_ MOD_Set_Timer_4_Zyklus_WH m4 : 39|1@1+ (1,0) [0|1] ""  Ladegeraet_PAG_PF
 SG_ MOD_Set_Timer_1_Jahr m1 : 3|7@1+ (1,2000) [2000|2125] "Unit_Year"  Ladegeraet_PAG_PF
 SG_ MOD_Set_Timer_2_Jahr m2 : 3|7@1+ (1,2000) [2000|2125] "Unit_Year"  Ladegeraet_PAG_PF
 SG_ MOD_Set_Timer_3_Jahr m3 : 3|7@1+ (1,2000) [2000|2125] "Unit_Year"  Ladegeraet_PAG_PF
 SG_ MOD_Set_Timer_1_Minute m1 : 10|6@1+ (1,0) [0|59] "Unit_Minut"  Ladegeraet_PAG_PF
 SG_ MOD_Set_Timer_2_Minute m2 : 10|6@1+ (1,0) [0|59] "Unit_Minut"  Ladegeraet_PAG_PF
 SG_ MOD_Set_Timer_3_Minute m3 : 10|6@1+ (1,0) [0|59] "Unit_Minut"  Ladegeraet_PAG_PF
 SG_ MOD_Set_Timer_1_Monat m1 : 16|4@1+ (1,0) [1|12] "Unit_Month"  Ladegeraet_PAG_PF
 SG_ MOD_Set_Timer_2_Monat m2 : 16|4@1+ (1,0) [1|12] "Unit_Month"  Ladegeraet_PAG_PF
 SG_ MOD_Set_Timer_3_Monat m3 : 16|4@1+ (1,0) [1|12] "Unit_Month"  Ladegeraet_PAG_PF
 SG_ MOD_Set_Timer_1_Stunde m1 : 20|5@1+ (1,0) [0|23] "Unit_Hours"  Ladegeraet_PAG_PF
 SG_ MOD_Set_Timer_2_Stunde m2 : 20|5@1+ (1,0) [0|23] "Unit_Hours"  Ladegeraet_PAG_PF
 SG_ MOD_Set_Timer_3_Stunde m3 : 20|5@1+ (1,0) [0|23] "Unit_Hours"  Ladegeraet_PAG_PF
 SG_ MOD_Set_Timer_1_Tag m1 : 25|5@1+ (1,0) [1|31] "Unit_Day"  Ladegeraet_PAG_PF
 SG_ MOD_Set_Timer_2_Tag m2 : 25|5@1+ (1,0) [1|31] "Unit_Day"  Ladegeraet_PAG_PF
 SG_ MOD_Set_Timer_3_Tag m3 : 25|5@1+ (1,0) [1|31] "Unit_Day"  Ladegeraet_PAG_PF
 SG_ MOD_Set_Timer_1_Laden m1 : 30|1@1+ (1,0) [0|1] ""  Ladegeraet_PAG_PF
 SG_ MOD_Set_Timer_2_Laden m2 : 30|1@1+ (1,0) [0|1] ""  Ladegeraet_PAG_PF
 SG_ MOD_Set_Timer_3_Laden m3 : 30|1@1+ (1,0) [0|1] ""  Ladegeraet_PAG_PF
 SG_ MOD_Set_Timer_1_Vorklima m1 : 31|1@1+ (1,0) [0|1] ""  Ladegeraet_PAG_PF
 SG_ MOD_Set_Timer_2_Vorklima m2 : 31|1@1+ (1,0) [0|1] ""  Ladegeraet_PAG_PF
 SG_ MOD_Set_Timer_3_Vorklima m3 : 31|1@1+ (1,0) [0|1] ""  Ladegeraet_PAG_PF
 SG_ MOD_Set_Timer_1_Zyklus_Mo m1 : 32|1@1+ (1,0) [0|1] ""  Ladegeraet_PAG_PF
 SG_ MOD_Set_Timer_2_Zyklus_Mo m2 : 32|1@1+ (1,0) [0|1] ""  Ladegeraet_PAG_PF
 SG_ MOD_Set_Timer_3_Zyklus_Mo m3 : 32|1@1+ (1,0) [0|1] ""  Ladegeraet_PAG_PF
 SG_ MOD_Set_Timer_1_Zyklus_Di m1 : 33|1@1+ (1,0) [0|1] ""  Ladegeraet_PAG_PF
 SG_ MOD_Set_Timer_2_Zyklus_Di m2 : 33|1@1+ (1,0) [0|1] ""  Ladegeraet_PAG_PF
 SG_ MOD_Set_Timer_3_Zyklus_Di m3 : 33|1@1+ (1,0) [0|1] ""  Ladegeraet_PAG_PF
 SG_ MOD_Set_Timer_1_Zyklus_Mi m1 : 34|1@1+ (1,0) [0|1] ""  Ladegeraet_PAG_PF
 SG_ MOD_Set_Timer_2_Zyklus_Mi m2 : 34|1@1+ (1,0) [0|1] ""  Ladegeraet_PAG_PF
 SG_ MOD_Set_Timer_3_Zyklus_Mi m3 : 34|1@1+ (1,0) [0|1] ""  Ladegeraet_PAG_PF
 SG_ MOD_Set_Timer_1_Zyklus_Do m1 : 35|1@1+ (1,0) [0|1] ""  Ladegeraet_PAG_PF
 SG_ MOD_Set_Timer_2_Zyklus_Do m2 : 35|1@1+ (1,0) [0|1] ""  Ladegeraet_PAG_PF
 SG_ MOD_Set_Timer_3_Zyklus_Do m3 : 35|1@1+ (1,0) [0|1] ""  Ladegeraet_PAG_PF
 SG_ MOD_Set_Timer_1_Zyklus_Fr m1 : 36|1@1+ (1,0) [0|1] ""  Ladegeraet_PAG_PF
 SG_ MOD_Set_Timer_2_Zyklus_Fr m2 : 36|1@1+ (1,0) [0|1] ""  Ladegeraet_PAG_PF
 SG_ MOD_Set_Timer_3_Zyklus_Fr m3 : 36|1@1+ (1,0) [0|1] ""  Ladegeraet_PAG_PF
 SG_ MOD_Set_Timer_1_Zyklus_Sa m1 : 37|1@1+ (1,0) [0|1] ""  Ladegeraet_PAG_PF
 SG_ MOD_Set_Timer_2_Zyklus_Sa m2 : 37|1@1+ (1,0) [0|1] ""  Ladegeraet_PAG_PF
 SG_ MOD_Set_Timer_3_Zyklus_Sa m3 : 37|1@1+ (1,0) [0|1] ""  Ladegeraet_PAG_PF
 SG_ MOD_Set_Timer_1_Zyklus_So m1 : 38|1@1+ (1,0) [0|1] ""  Ladegeraet_PAG_PF
 SG_ MOD_Set_Timer_2_Zyklus_So m2 : 38|1@1+ (1,0) [0|1] ""  Ladegeraet_PAG_PF
 SG_ MOD_Set_Timer_3_Zyklus_So m3 : 38|1@1+ (1,0) [0|1] ""  Ladegeraet_PAG_PF
 SG_ MOD_Set_Timer_1_Zyklus_WH m1 : 39|1@1+ (1,0) [0|1] ""  Ladegeraet_PAG_PF
 SG_ MOD_Set_Timer_2_Zyklus_WH m2 : 39|1@1+ (1,0) [0|1] ""  Ladegeraet_PAG_PF
 SG_ MOD_Set_Timer_MUX M : 0|3@1+ (1,0) [0|7] ""  Ladegeraet_PAG_PF
 SG_ MOD_Set_Timer_3_Zyklus_WH m3 : 39|1@1+ (1,0) [0|1] ""  Ladegeraet_PAG_PF
 SG_ MOD_Set_Nachtstrom_X_Std_Anf : 40|6@1+ (0.5,0) [0|23.5] "Unit_Hours"  Ladegeraet_PAG_PF
 SG_ MOD_Set_Nachtstrom_Prof : 46|2@1+ (1,0) [0|3] ""  Ladegeraet_PAG_PF
 SG_ MOD_Set_Nachtstrom_X_Std_End : 48|6@1+ (0.5,0) [0|23.5] "Unit_Hours"  Ladegeraet_PAG_PF
 SG_ MOD_Set_Nachtstrom_Akt_Prof : 54|2@1+ (1,0) [0|3] ""  Ladegeraet_PAG_PF
 SG_ MOD_Set_Abbruch_Klima : 56|1@1+ (1,0) [0|1] ""  Ladegeraet_PAG_PF
 SG_ MOD_Set_Sofortstart_Klima : 58|1@1+ (1,0) [0|1] ""  Ladegeraet_PAG_PF
 SG_ MOD_Anf_Spiegel_anklappen : 60|1@1+ (1,0) [0|1] "" Vector__XXX
 SG_ MOD_Anf_ZV : 61|2@1+ (1,0) [0|3] "" Vector__XXX

BO_ 1397 HVLM_07_PAG: 8 Ladegeraet_PAG_PF
 SG_ HVLM_Status_naechster_Ladetimer m7 : 34|2@1+ (1,0) [0|3] ""  GW_Routing_Derivate
 SG_ HVLM_Status_naechster_Klimatimer m7 : 32|2@1+ (1,0) [0|3] ""  GW_Routing_Derivate
 SG_ HVLM_Status_Timer_7_Laden m7 : 30|1@1+ (1,0) [0|1] ""  GW_Routing_Derivate
 SG_ HVLM_Ladetexte : 59|3@1+ (1,0) [0|7] ""  GW_Routing_Derivate
 SG_ HVLM_Status_Timer_4_Jahr m4 : 3|7@1+ (1,2000) [2000|2125] "Unit_Year"  GW_Routing_Derivate
 SG_ HVLM_Status_Timer_4_Minute m4 : 10|6@1+ (1,0) [0|59] "Unit_Minut"  GW_Routing_Derivate
 SG_ HVLM_Status_Timer_4_Monat m4 : 16|4@1+ (1,0) [1|12] "Unit_Month"  GW_Routing_Derivate
 SG_ HVLM_Status_Timer_4_Stunde m4 : 20|5@1+ (1,0) [0|23] "Unit_Hours"  GW_Routing_Derivate
 SG_ HVLM_Status_Timer_4_Tag m4 : 25|5@1+ (1,0) [1|31] "Unit_Day"  GW_Routing_Derivate
 SG_ HVLM_Status_Timer_4_Laden m4 : 30|1@1+ (1,0) [0|1] ""  GW_Routing_Derivate
 SG_ HVLM_Status_Timer_4_Vorklima m4 : 31|1@1+ (1,0) [0|1] ""  GW_Routing_Derivate
 SG_ HVLM_Status_Timer_4_Zyklus_Mo m4 : 32|1@1+ (1,0) [0|1] ""  GW_Routing_Derivate
 SG_ HVLM_Status_Timer_2_Vorklima m2 : 31|1@1+ (1,0) [0|1] ""  GW_Routing_Derivate
 SG_ HVLM_Status_Timer_3_Vorklima m3 : 31|1@1+ (1,0) [0|1] ""  GW_Routing_Derivate
 SG_ HVLM_Status_Timer_1_Zyklus_Mo m1 : 32|1@1+ (1,0) [0|1] ""  GW_Routing_Derivate
 SG_ HVLM_Status_Timer_2_Zyklus_Mo m2 : 32|1@1+ (1,0) [0|1] ""  GW_Routing_Derivate
 SG_ HVLM_Status_Timer_3_Zyklus_Mo m3 : 32|1@1+ (1,0) [0|1] ""  GW_Routing_Derivate
 SG_ HVLM_Status_Timer_1_Zyklus_Di m1 : 33|1@1+ (1,0) [0|1] ""  GW_Routing_Derivate
 SG_ HVLM_Status_Timer_2_Zyklus_Di m2 : 33|1@1+ (1,0) [0|1] ""  GW_Routing_Derivate
 SG_ HVLM_Status_Timer_3_Zyklus_Di m3 : 33|1@1+ (1,0) [0|1] ""  GW_Routing_Derivate
 SG_ HVLM_Status_Timer_1_Zyklus_Mi m1 : 34|1@1+ (1,0) [0|1] ""  GW_Routing_Derivate
 SG_ HVLM_Status_Timer_2_Zyklus_Mi m2 : 34|1@1+ (1,0) [0|1] ""  GW_Routing_Derivate
 SG_ HVLM_Status_Timer_3_Zyklus_Mi m3 : 34|1@1+ (1,0) [0|1] ""  GW_Routing_Derivate
 SG_ HVLM_Status_Timer_1_Zyklus_Do m1 : 35|1@1+ (1,0) [0|1] ""  GW_Routing_Derivate
 SG_ HVLM_Status_Timer_2_Zyklus_Do m2 : 35|1@1+ (1,0) [0|1] ""  GW_Routing_Derivate
 SG_ HVLM_Status_Timer_3_Zyklus_Do m3 : 35|1@1+ (1,0) [0|1] ""  GW_Routing_Derivate
 SG_ HVLM_Status_Timer_1_Zyklus_Fr m1 : 36|1@1+ (1,0) [0|1] ""  GW_Routing_Derivate
 SG_ HVLM_Status_Timer_2_Zyklus_Fr m2 : 36|1@1+ (1,0) [0|1] ""  GW_Routing_Derivate
 SG_ HVLM_Status_Timer_3_Zyklus_Fr m3 : 36|1@1+ (1,0) [0|1] ""  GW_Routing_Derivate
 SG_ HVLM_Status_Timer_1_Zyklus_Sa m1 : 37|1@1+ (1,0) [0|1] ""  GW_Routing_Derivate
 SG_ HVLM_Status_Timer_2_Zyklus_Sa m2 : 37|1@1+ (1,0) [0|1] ""  GW_Routing_Derivate
 SG_ HVLM_Status_Timer_3_Zyklus_Sa m3 : 37|1@1+ (1,0) [0|1] ""  GW_Routing_Derivate
 SG_ HVLM_Status_Timer_1_Zyklus_So m1 : 38|1@1+ (1,0) [0|1] ""  GW_Routing_Derivate
 SG_ HVLM_Status_Timer_2_Zyklus_So m2 : 38|1@1+ (1,0) [0|1] ""  GW_Routing_Derivate
 SG_ HVLM_Status_Timer_3_Zyklus_So m3 : 38|1@1+ (1,0) [0|1] ""  GW_Routing_Derivate
 SG_ HVLM_Status_Timer_1_Zyklus_WH m1 : 39|1@1+ (1,0) [0|1] ""  GW_Routing_Derivate
 SG_ HVLM_Status_Timer_2_Zyklus_WH m2 : 39|1@1+ (1,0) [0|1] ""  GW_Routing_Derivate
 SG_ HVLM_Status_Timer_MUX M : 0|3@1+ (1,0) [0|7] ""  GW_Routing_Derivate
 SG_ HVLM_Status_Timer_3_Zyklus_WH m3 : 39|1@1+ (1,0) [0|1] ""  GW_Routing_Derivate
 SG_ HVLM_Status_Nachtstrom_X_Std_Anf : 40|6@1+ (0.5,0) [0|23.5] "Unit_Hours"  GW_Routing_Derivate
 SG_ HVLM_Status_Nachtstrom_Prof : 46|2@1+ (1,0) [0|3] ""  GW_Routing_Derivate
 SG_ HVLM_Status_Nachtstrom_X_Std_End : 48|6@1+ (0.5,0) [0|23.5] "Unit_Hours"  GW_Routing_Derivate
 SG_ HVLM_Status_Nachtstrom_Akt_Prof : 54|2@1+ (1,0) [0|3] ""  GW_Routing_Derivate
 SG_ HVLM_Status_Laden : 56|3@1+ (1,0) [0|7] ""  GW_Routing_Derivate
 SG_ HVLM_Status_Timer_4_Zyklus_Di m4 : 33|1@1+ (1,0) [0|1] ""  GW_Routing_Derivate
 SG_ HVLM_Status_Timer_4_Zyklus_Mi m4 : 34|1@1+ (1,0) [0|1] ""  GW_Routing_Derivate
 SG_ HVLM_Status_Timer_4_Zyklus_Do m4 : 35|1@1+ (1,0) [0|1] ""  GW_Routing_Derivate
 SG_ HVLM_Status_Timer_4_Zyklus_Fr m4 : 36|1@1+ (1,0) [0|1] ""  GW_Routing_Derivate
 SG_ HVLM_Status_Timer_1_Jahr m1 : 3|7@1+ (1,2000) [2000|2125] "Unit_Year"  GW_Routing_Derivate
 SG_ HVLM_Status_Timer_2_Jahr m2 : 3|7@1+ (1,2000) [2000|2125] "Unit_Year"  GW_Routing_Derivate
 SG_ HVLM_Status_Timer_3_Jahr m3 : 3|7@1+ (1,2000) [2000|2125] "Unit_Year"  GW_Routing_Derivate
 SG_ HVLM_Status_Timer_7_Jahr m7 : 3|7@1+ (1,2000) [2000|2125] "Unit_Year"  GW_Routing_Derivate
 SG_ HVLM_Status_Timer_1_Minute m1 : 10|6@1+ (1,0) [0|59] "Unit_Minut"  GW_Routing_Derivate
 SG_ HVLM_Status_Timer_2_Minute m2 : 10|6@1+ (1,0) [0|59] "Unit_Minut"  GW_Routing_Derivate
 SG_ HVLM_Status_Timer_3_Minute m3 : 10|6@1+ (1,0) [0|59] "Unit_Minut"  GW_Routing_Derivate
 SG_ HVLM_Status_Timer_7_Minute m7 : 10|6@1+ (1,0) [0|59] "Unit_Minut"  GW_Routing_Derivate
 SG_ HVLM_Status_Timer_1_Monat m1 : 16|4@1+ (1,0) [1|12] "Unit_Month"  GW_Routing_Derivate
 SG_ HVLM_Status_Timer_2_Monat m2 : 16|4@1+ (1,0) [1|12] "Unit_Month"  GW_Routing_Derivate
 SG_ HVLM_Status_Timer_3_Monat m3 : 16|4@1+ (1,0) [1|12] "Unit_Month"  GW_Routing_Derivate
 SG_ HVLM_Status_Timer_7_Monat m7 : 16|4@1+ (1,0) [1|12] "Unit_Month"  GW_Routing_Derivate
 SG_ HVLM_Status_Timer_1_Stunde m1 : 20|5@1+ (1,0) [0|23] "Unit_Hours"  GW_Routing_Derivate
 SG_ HVLM_Status_Timer_2_Stunde m2 : 20|5@1+ (1,0) [0|23] "Unit_Hours"  GW_Routing_Derivate
 SG_ HVLM_Status_Timer_3_Stunde m3 : 20|5@1+ (1,0) [0|23] "Unit_Hours"  GW_Routing_Derivate
 SG_ HVLM_Status_Timer_7_Stunde m7 : 20|5@1+ (1,0) [0|23] "Unit_Hours"  GW_Routing_Derivate
 SG_ HVLM_Status_Timer_1_Tag m1 : 25|5@1+ (1,0) [1|31] "Unit_Day"  GW_Routing_Derivate
 SG_ HVLM_Status_Timer_2_Tag m2 : 25|5@1+ (1,0) [1|31] "Unit_Day"  GW_Routing_Derivate
 SG_ HVLM_Status_Timer_3_Tag m3 : 25|5@1+ (1,0) [1|31] "Unit_Day"  GW_Routing_Derivate
 SG_ HVLM_Status_Timer_7_Tag m7 : 25|5@1+ (1,0) [1|31] "Unit_Day"  GW_Routing_Derivate
 SG_ HVLM_Status_Timer_1_Laden m1 : 30|1@1+ (1,0) [0|1] ""  GW_Routing_Derivate
 SG_ HVLM_Status_Timer_2_Laden m2 : 30|1@1+ (1,0) [0|1] ""  GW_Routing_Derivate
 SG_ HVLM_Status_Timer_3_Laden m3 : 30|1@1+ (1,0) [0|1] ""  GW_Routing_Derivate
 SG_ HVLM_Status_Timer_1_Vorklima m1 : 31|1@1+ (1,0) [0|1] ""  GW_Routing_Derivate
 SG_ HVLM_Status_Timer_4_Zyklus_Sa m4 : 37|1@1+ (1,0) [0|1] ""  GW_Routing_Derivate
 SG_ HVLM_Status_Timer_4_Zyklus_So m4 : 38|1@1+ (1,0) [0|1] ""  GW_Routing_Derivate
 SG_ HVLM_Status_Timer_4_Zyklus_WH m4 : 39|1@1+ (1,0) [0|1] ""  GW_Routing_Derivate

CM_ "Version 7.21 Release (G1 II) Patch SOP";
CM_ BU_ Sound_A "Soundaktuator (Außen)";
CM_ BU_ Ladegeraet_PAG_PF "Ladegerät PAG";
CM_ BU_ Motor_EDC17_Pirol "Motor EDC17 Pirol";
CM_ BU_ PSM_Ant_Derivate "Porsche Stability Management Hybrid";
CM_ BU_ GW_Routing_Derivate "Gateway Routing (Derivate)";
CM_ BU_ GW_Applikation_Derivate "Gateway Applikation (Derivate)";
CM_ BU_ BMS_Hybrid "Batteriemanagementsystem Hybrid  (Einsatz nur im Hybrid)";
CM_ BU_ Getriebe_Derivate "Getriebe Aisin 8-Gang";
CM_ BU_ LEH_Hybrid "Leistungselektronik Hybrid  (Einsatz nur im Hybrid)";
CM_ BU_ Motor_MED17_Hybrid "Motor MED17 Hybrid";
CM_ BU_ Sound_I "Soundaktuator (Innen)";
CM_ BU_ Tool "Tool";
CM_ BU_ Airbag "Airbag Steuergerät";
CM_ BU_ Waehlhebel "Wählhebel";
CM_ BO_ 3221225472 "This is a message for not used signals, created by Vector CANdb++ DBC OLE DB Provider.";
CM_ SG_ 3221225472 KBI_Trip_E_Std "Trip-Daten(seit): Stunden
";
CM_ SG_ 3221225472 KBI_Trip_E_Min "Trip-Daten(seit): Minuten
";
CM_ SG_ 3221225472 KBI_Service_km "Anzeige der verbleibenden km bis zum nächsten Service
";
CM_ SG_ 3221225472 KBI_Service_Zeit "Anzeige der verbleibenden Zeit bis zum nächsten Service
";
CM_ SG_ 3221225472 KBI_Service_Typ "Anzeige, ob nächster Service eine Zwischen-, Hauptwartung oder ein Ölservice ist
";
CM_ SG_ 3221225472 Mo_HVEM_HV_Abschaltanf "Maximale vom MSG freigegebene Leistung für alle HV-Komfortverbraucher.
(ausgenommen DC/DC-Wandler).";
CM_ SG_ 3221225472 MO_HVEM_HV_Maxleistung "Maximale vom MSG freigegebene Leistung für alle HV-Komfortverbraucher.
(ausgenommen DC/DC-Wandler).";
CM_ SG_ 3221225472 HVEM_Istleistung_Nebenverbrauch "Istleistung der HV-Nebenverbraucher";
CM_ SG_ 3221225472 BMS_TauKuehlmittel__Temp_ "Zeitkonstante Tau Kühlmittel zur Bestimmung der Soll-Vorlauftemperatur als Integral über diese Zeit.";
CM_ SG_ 3221225472 SVB_IVB_FS_Fond "Sollverbau Verdeck SG
";
CM_ SG_ 3221225472 SVB_IVB_FS "Sollverbau Verdeck SG
";
CM_ SG_ 3221225472 SVB_IVB_BFS_Fond "Sollverbau Verdeck SG
";
CM_ SG_ 3221225472 SVB_IVB_BFS "Sollverbau Verdeck SG
";
CM_ SG_ 3221225472 SVB_KameraLow_FLA "Sollverbau Kamera Low";
CM_ SG_ 3221225472 AWV_Halten "Anforderung an das ESP, das Fahrzeug nach erfolgter automatischer Bremsung bis in den Stillstand im Stillstand zu halten und eine Fahrer-Überwachung zu aktivieren.";
CM_ SG_ 3221225472 NMH_GW_VNSM_VC5 "NMH Gateway Byte 6 
VC5, Komfort bus activation from diagnostic command";
CM_ SG_ 3221225472 NMH_GW_VNSM_Wfpf "NMH Gateway Byte 6 
VNSM, Weckfortpflanzung VNSM (general)
GW wakes bus due to WFP (e.g. from Komfort, MMI, ...)";
CM_ BO_ 1728 "D4 Kombi-Komfort 200ms";
CM_ SG_ 1728 NMH_GW_Start_1 "Zustand Start (<--Sleep)";
CM_ SG_ 1728 NMH_GW_Start_2 "Zustand Start (<--Prepare to Sleep)";
CM_ SG_ 1728 NMH_GW_Normal_Mode_1 "Zustand Normal Mode (<-- Start)";
CM_ SG_ 1728 NMH_GW_Normal_Mode_2 "Zustand Normal Mode (<-- Ready to Sleep)";
CM_ SG_ 1728 NMH_GW_Car_WakeUp "Car WakeUp (optional), wird vom GW nicht gesendet";
CM_ SG_ 1728 NMH_GW_Per_WakeUp "Weckursache Peripherie
";
CM_ SG_ 1728 NMH_GW_Fkt_WakeUp "Weckursache Funktion (Softwarefunktion hat geweckt)
0 = wenn Peripheriewakeup
1 = BDM BEM
2 = Car Wakeup empfangen: Das Bussegment wurde aufgrund einer CarWakeup Anforderung geweckt. Das GW hat zuvor eine NWM-Botschaft auf einem Bus mit aktiviertem Car";
CM_ SG_ 1728 NMH_GW_NM_aktiv_Klemme_15 "Kl.15 EIN (Nachlaufursache, nicht 'Ready To Sleep')";
CM_ SG_ 1728 NMH_GW_NM_aktiv_Diagnose "Diagnose bei Kl 15 aus (Nachlaufursache, nicht 'Ready To Sleep')";
CM_ SG_ 1728 NMH_GW_NM_aktiv_Start "Mindestaktivzeit Zustand 'Start' (Nachlaufursache, nicht 'Ready To Sleep')";
CM_ SG_ 1728 NMH_GW_NM_aktiv_BDM "BDM-Kommunikation (Nachlaufursache, nicht 'Ready To Sleep')
";
CM_ SG_ 1728 NMH_GW_NM_aktiv_Warnblinken "Warnblinken (NM-Nachlaufursache, nicht 'Ready To Sleep')
";
CM_ SG_ 1728 NMH_GW_NM_aktiv_ESP "ESP aktiv (Wakeup/Sleep-Konzept)
(NM-Nachlaufursache, nicht 'Ready To Sleep')
";
CM_ SG_ 1728 NMH_GW_NM_aktiv_EMP "Nachlauf Energiemanagementplannung";
CM_ SG_ 1728 NMH_GW_Abschaltstufe_3 "Abschaltstufe 3 (BEM) 
(SG-interner Nachlauf vor CAN-Wakeup)
";
CM_ SG_ 1728 NMH_GW_SG_Fehlerdauer "Steuergeraetefehlerdauer (BEM)
(SG-interner Nachlauf vor CAN-Wakeup)
";
CM_ SG_ 1728 NMH_GW_STH_Wakeup "Standheizungswakeup (BEM)
(SG-interner Nachlauf vor CAN-Wakeup)";
CM_ SG_ 1728 NMH_GW_NL_Diagnose "Gateway hat lokalen Nachlauf wegen Kommunikation mit Tester auf DiagCAN";
CM_ SG_ 1728 NM_GW_Signalfehler "Bei der Speicherung eines CAN-Signalfehlers muss dieser mindestens einmal in der NM-Botschaft angezeigt werden.";
CM_ SG_ 1728 NMH_GW_TimeOut_Fehler "Aktiver Timeout Fehlerspeichereintrag";
CM_ SG_ 1728 NMH_GW_CAN_Diag_deaktiv "CAN Bus bezogene Eigendiagnose deaktiviert (Überspannung, Unterspannung, Hochlaufphase, ...) ";
CM_ SG_ 1728 NMH_GW_KompSchutz "Funktionseinschränung aufgrund Komponentenschutz aktiv";
CM_ SG_ 1728 NMH_GW_Mute_Mode "Funktionseinschränung aufgrund Mute Mode aktiv, nur VW";
CM_ SG_ 1728 NMH_GW_Transport_Mode "Funktionseinschränung aufgrund Transport Mode aktiv";
CM_ SG_ 1728 NMH_GW_Abschaltstufe_aktiv "Funktionsabschaltung wegen Abschaltschaltstufe";
CM_ SG_ 1728 NMH_GW_Eindraht_Fehler "Erkennung Eindrahtfehler";
CM_ SG_ 1728 NMH_GW_ACAN "Antriebs-CAN aktiv (Wakeup/Sleep Konzept)
(NM-Nachlaufursache, nicht 'Ready To Sleep')
";
CM_ SG_ 1728 NMH_GW_KombiCAN "Kombi/Fahrwerks-CAN aktiv (Wakeup/Sleep Konzept)
(NM-Nachlaufursache, nicht 'Ready To Sleep')
";
CM_ SG_ 1728 NMH_GW_KomfortCAN "Komfort-CAN aktiv (Wakeup/Sleep Konzept)
(NM-Nachlaufursache, nicht 'Ready To Sleep')

";
CM_ SG_ 1728 NMH_GW_Infotainment "Infotainment aktiv (CAN oder MOST), Wakeup/Sleep-Konzept
(NM-Nachlaufursache, nicht 'Ready To Sleep')
";
CM_ SG_ 1728 NMH_GW_Fahrwerk "Fahrwerks-Bus aktiv (Wakeup/Sleep Konzept)
(NM-Nachlaufursache, nicht 'Ready To Sleep')
";
CM_ SG_ 1728 NMH_GW_WakeUp_CAN_Bus "Weckendes Bussegment (Welcher CAN hat geweckt bzw. CarWakeup angefordert?)

";
CM_ SG_ 1327 OBD_Fehler_Laengsbeschleunigung "Pin pointing für OBD Kommunikation zu Motor SG";
CM_ SG_ 1327 OBD_Fehler_Vordrucksensor "Fehlerstatus Vordrucksensor PSM für OBD";
CM_ SG_ 1381 HVLM_IstSpannung_HV "Ausgangsspannung des Ladegerätes und DC-Spannung der Ladesäule. Messung zwischen den DC HV-Leitungen. ";
CM_ SG_ 1381 HVLM_HV_Abstellzeit "Zeitraum zwischen HV-Deaktiviert und HV-Aktiviert";
CM_ SG_ 1381 HVLM_Zustand_LED "Zustand der Lade-LED im Kombi und Dosenbeleuchtung";
CM_ SG_ 1381 HVLM_MaxLadezeitDCHV "maximale Ladezeit in Minuten für die Ladesäule";
CM_ SG_ 1381 HVLM_MaxStrom_Netz "maximal zulässiger Strom auf Primärseite (AC) des Ladegerätes
Minima aus
Vorgabe z.B. über
- intelligente Kommunikation
- Control Pilot Duty Cycle
- Widerstandskodierung Kabel (Proximity)
- Vorgabe MMI, o.ä.";
CM_ SG_ 1381 HVLM_LG_Sollmodus "Sollmodus AC Ladegerät";
CM_ SG_ 1381 HVLM_FreigabeTankdeckel "Tankdeckelfreigabe";
CM_ SG_ 1381 HVLM_Stecker_Verriegeln "Anforderung Steckerverriegelung";
CM_ SG_ 1381 HVLM_Start_Spannungsmessung_DCLS "Meldung an das BMS, dass an der DC-Ladesäule eine Messspannung aufgeschaltet wird.";
CM_ SG_ 1381 HVLM_Taster_Profil_Laden_Anf "Zustand der Profil-Laden-Taste; LED an der Ladedose";
CM_ SG_ 1381 HVLM_Taster_Sofort_Laden_Anf "Zustand der Sofort-Laden-Taste; LED an der Ladedose";
CM_ SG_ 1381 HVLM_FreigabeKlimatisierung "Klimatisierung freigeben";
CM_ SG_ 1381 HVLM_Ladetexte "Anzeige, ob AC- oder DC-Laden nicht möglich ist";
CM_ SG_ 1534 KBI_Set_Timer_MUX "Multiplexor zur Anzeige des aktuell übertragenden und zu setzenden Timers";
CM_ SG_ 1534 KBI_Set_Timer_1_Jahr "Status Timer 1 gesetztes Datum -> Jahr";
CM_ SG_ 1534 KBI_Set_Timer_2_Jahr "Status Timer 2 gesetztes Datum -> Jahr";
CM_ SG_ 1534 KBI_Set_Timer_3_Jahr "Status Timer 3 gesetztes Datum -> Jahr";
CM_ SG_ 1534 KBI_Set_Timer_4_Jahr "Status Timer 4 gesetztes Datum -> Jahr";
CM_ SG_ 1534 KBI_Set_Timer_1_Minute "Status Timer 1 gesetztes Datum -> Minute";
CM_ SG_ 1534 KBI_Set_Timer_2_Minute "Status Timer 2 gesetztes Datum -> Minute";
CM_ SG_ 1534 KBI_Set_Timer_3_Minute "Status Timer 3 gesetztes Datum -> Minute";
CM_ SG_ 1534 KBI_Set_Timer_4_Minute "Status Timer 4 gesetztes Datum -> Minute";
CM_ SG_ 1534 KBI_Set_Timer_1_Monat "Status Timer 1 gesetztes Datum -> Monat";
CM_ SG_ 1534 KBI_Set_Timer_2_Monat "Status Timer 2 gesetztes Datum -> Monat";
CM_ SG_ 1534 KBI_Set_Timer_3_Monat "Status Timer 3 gesetztes Datum -> Monat";
CM_ SG_ 1534 KBI_Set_Timer_4_Monat "Status Timer 4 gesetztes Datum -> Monat";
CM_ SG_ 1534 KBI_Set_Timer_1_Stunde "Status Timer 1 gesetztes Datum -> Stunde";
CM_ SG_ 1534 KBI_Set_Timer_2_Stunde "Status Timer 2 gesetztes Datum -> Stunde";
CM_ SG_ 1534 KBI_Set_Timer_3_Stunde "Status Timer 3 gesetztes Datum -> Stunde";
CM_ SG_ 1534 KBI_Set_Timer_4_Stunde "Status Timer 4 gesetztes Datum -> Stunde";
CM_ SG_ 1534 KBI_Set_Timer_1_Tag "Status Timer 1 gesetztes Datum -> Tag";
CM_ SG_ 1534 KBI_Set_Timer_2_Tag "Status Timer 2 gesetztes Datum -> Tag";
CM_ SG_ 1534 KBI_Set_Timer_3_Tag "Status Timer 3 gesetztes Datum -> Tag";
CM_ SG_ 1534 KBI_Set_Timer_4_Tag "Status Timer 4 gesetztes Datum -> Tag";
CM_ SG_ 1534 KBI_Set_Timer_1_Laden "Setzen des Ladetimers 1";
CM_ SG_ 1534 KBI_Set_Timer_2_Laden "Setzen des Ladetimers 2";
CM_ SG_ 1534 KBI_Set_Timer_3_Laden "Setzen des Ladetimers 3";
CM_ SG_ 1534 KBI_Set_Timer_4_Laden "Setzen des Ladetimers 4";
CM_ SG_ 1534 KBI_Set_Timer_1_Vorklima "Setzen des Vorklimatisierungs-Timers 1";
CM_ SG_ 1534 KBI_Set_Timer_2_Vorklima "Setzen des Vorklimatisierungs-Timers 2";
CM_ SG_ 1534 KBI_Set_Timer_3_Vorklima "Setzen des Vorklimatisierungs-Timers 3";
CM_ SG_ 1534 KBI_Set_Timer_4_Vorklima "Setzen des Vorklimatisierungs-Timers 4";
CM_ SG_ 1534 KBI_Set_Timer_1_Zyklus_Mo "Timer 1 für Wochentag gesetzt";
CM_ SG_ 1534 KBI_Set_Timer_2_Zyklus_Mo "Timer 2 für Wochentag gesetzt";
CM_ SG_ 1534 KBI_Set_Timer_3_Zyklus_Mo "Timer 3 für Wochentag gesetzt";
CM_ SG_ 1534 KBI_Set_Timer_4_Zyklus_Mo "Timer 4 für Wochentag gesetzt";
CM_ SG_ 1534 KBI_Set_Timer_1_Zyklus_Di "Timer 1 für Wochentag gesetzt";
CM_ SG_ 1534 KBI_Set_Timer_2_Zyklus_Di "Timer 2 für Wochentag gesetzt";
CM_ SG_ 1534 KBI_Set_Timer_3_Zyklus_Di "Timer 3 für Wochentag gesetzt";
CM_ SG_ 1534 KBI_Set_Timer_4_Zyklus_Di "Timer 4 für Wochentag gesetzt";
CM_ SG_ 1534 KBI_Set_Timer_1_Zyklus_Mi "Timer 1 für Wochentag gesetzt";
CM_ SG_ 1534 KBI_Set_Timer_2_Zyklus_Mi "Timer 2 für Wochentag gesetzt";
CM_ SG_ 1534 KBI_Set_Timer_3_Zyklus_Mi "Timer 3 für Wochentag gesetzt";
CM_ SG_ 1534 KBI_Set_Timer_4_Zyklus_Mi "Timer 4 für Wochentag gesetzt";
CM_ SG_ 1534 KBI_Set_Timer_1_Zyklus_Do "Timer 1 für Wochentag gesetzt";
CM_ SG_ 1534 KBI_Set_Timer_2_Zyklus_Do "Timer 2 für Wochentag gesetzt";
CM_ SG_ 1534 KBI_Set_Timer_3_Zyklus_Do "Timer 3 für Wochentag gesetzt";
CM_ SG_ 1534 KBI_Set_Timer_4_Zyklus_Do "Timer 4 für Wochentag gesetzt";
CM_ SG_ 1534 KBI_Set_Timer_1_Zyklus_Fr "Timer 1 für Wochentag gesetzt";
CM_ SG_ 1534 KBI_Set_Timer_2_Zyklus_Fr "Timer 2 für Wochentag gesetzt";
CM_ SG_ 1534 KBI_Set_Timer_3_Zyklus_Fr "Timer 3 für Wochentag gesetzt";
CM_ SG_ 1534 KBI_Set_Timer_4_Zyklus_Fr "Timer 4 für Wochentag gesetzt";
CM_ SG_ 1534 KBI_Set_Timer_1_Zyklus_Sa "Timer 1 für Wochentag gesetzt";
CM_ SG_ 1534 KBI_Set_Timer_2_Zyklus_Sa "Timer 2 für Wochentag gesetzt";
CM_ SG_ 1534 KBI_Set_Timer_3_Zyklus_Sa "Timer 3 für Wochentag gesetzt";
CM_ SG_ 1534 KBI_Set_Timer_4_Zyklus_Sa "Timer 4 für Wochentag gesetzt";
CM_ SG_ 1534 KBI_Set_Timer_1_Zyklus_So "Timer 1 für Wochentag gesetzt";
CM_ SG_ 1534 KBI_Set_Timer_2_Zyklus_So "Timer 2 für Wochentag gesetzt";
CM_ SG_ 1534 KBI_Set_Timer_3_Zyklus_So "Timer 3 für Wochentag gesetzt";
CM_ SG_ 1534 KBI_Set_Timer_4_Zyklus_So "Timer 4 für Wochentag gesetzt";
CM_ SG_ 1534 KBI_Set_Timer_1_Zyklus_WH "Timer 1 ist zur einmaligen Auslösung gestezt oder wiederholt sich";
CM_ SG_ 1534 KBI_Set_Timer_2_Zyklus_WH "Timer 2 ist zur einmaligen Auslösung gestezt oder wiederholt sich";
CM_ SG_ 1534 KBI_Set_Timer_3_Zyklus_WH "Timer 3 ist zur einmaligen Auslösung gestezt oder wiederholt sich";
CM_ SG_ 1534 KBI_Set_Timer_4_Zyklus_WH "Timer 4 ist zur einmaligen Auslösung gestezt oder wiederholt sich";
CM_ SG_ 1534 KBI_MOD_Privatsphaere "Ein- und Ausschalten der MOD-Funktion (NICHT VTS) über Kombiinstrument.";
CM_ SG_ 1534 KBI_STH_Status "Standheizungs- Status
";
CM_ SG_ 1631 MO_Energieinhalt_BMS "Restenergieinhalt der Traktionsbatterie, beeinflusst durch Fahrstrategie und weiteren Faktoren der Antriebssteuerung.";
CM_ SG_ 1398 MOD_Privatsphaere "Status der MOD-Privatsphaere-Einstellungen im KBI.";
CM_ SG_ 1398 MOD_Set_Timer_5_Jahr "Standheizungstimer #2 (Timer 5) zur zeitversetzten Steuerung der STH auf Anforderung durch MOD.";
CM_ SG_ 1398 MOD_Set_Timer_6_Jahr "Standheizungstimer #3 - Jahr (Timer 6) zur zeitversetzten Steuerung der STH auf Anforderung durch MOD.";
CM_ SG_ 1398 MOD_Set_Timer_5_Minute "Standheizungstimer #2 - Minute (Timer 5) zur zeitversetzten Steuerung der STH auf Anforderung durch MOD.";
CM_ SG_ 1398 MOD_Set_Timer_6_Minute "Standheizungstimer #3 - Minute (Timer 6) zur zeitversetzten Steuerung der STH auf Anforderung durch MOD.";
CM_ SG_ 1398 MOD_Set_Timer_5_Monat "Standheizungstimer #2 - Monat (Timer 5) zur zeitversetzten Steuerung der STH auf Anforderung durch MOD.";
CM_ SG_ 1398 MOD_Set_Timer_6_Monat "Standheizungstimer #3 - Monat";
CM_ SG_ 1398 MOD_Set_Timer_5_Stunde "Standheizungstimer #2 - Stunde (Timer 5) zur zeitversetzten Steuerung der STH auf Anforderung durch MOD.";
CM_ SG_ 1398 MOD_Set_Timer_6_Stunde "Standheizungstimer #3 - Stunde (Timer 6) zur zeitversetzten Steuerung der STH auf Anforderung durch MOD.";
CM_ SG_ 1398 MOD_Set_Timer_5_Tag "Standheizungstimer #2 - Monat";
CM_ SG_ 1398 MOD_Set_Timer_6_Tag "Standheizungstimer #3 - Tag (Timer 6) zur zeitversetzten Steuerung der STH auf Anforderung durch MOD.";
CM_ SG_ 1398 MOD_Set_Timer_5_Vorklima "Status des Standheizungstimers #2 (Timer 5).";
CM_ SG_ 1398 MOD_Set_Timer_6_Vorklima "Status des Standheizungstimers #3 (Timer 6).";
CM_ SG_ 1398 MOD_Set_Timerladen "Timerladen starten / unterbrechen auf Anforderung durch MOD.";
CM_ SG_ 1398 MOD_Set_Sofortladen "Sofortladen starten / unterbrechen auf Anforderung durch MOD.";
CM_ SG_ 1398 MOD_Set_Timer_4_Jahr "Status Timer 4 gesetztes Datum -> Jahr";
CM_ SG_ 1398 MOD_Set_Timer_4_Minute "Status Timer 4 gesetztes Datum -> Minute";
CM_ SG_ 1398 MOD_Set_Timer_4_Monat "Status Timer 4 gesetztes Datum -> Monat";
CM_ SG_ 1398 MOD_Set_Timer_4_Stunde "Status Timer 4 gesetztes Datum -> Stunde";
CM_ SG_ 1398 MOD_Set_Timer_4_Tag "Status Timer 4 gesetztes Datum -> Tag";
CM_ SG_ 1398 MOD_Set_Timer_4_Laden "Status des Ladetimers 4";
CM_ SG_ 1398 MOD_Set_Timer_4_Vorklima "Status des Vorklimatisierungs-Timers 4";
CM_ SG_ 1398 MOD_Set_Timer_4_Zyklus_Mo "Timer 4 für Wochentag gesetzt";
CM_ SG_ 1398 MOD_Set_Timer_4_Zyklus_Di "Timer 4 für Wochentag gesetzt";
CM_ SG_ 1398 MOD_Set_Timer_4_Zyklus_Mi "Timer 4 für Wochentag gesetzt";
CM_ SG_ 1398 MOD_Set_Timer_4_Zyklus_Do "Timer 4 für Wochentag gesetzt";
CM_ SG_ 1398 MOD_Set_Timer_4_Zyklus_Fr "Timer 4 für Wochentag gesetzt";
CM_ SG_ 1398 MOD_Set_Timer_4_Zyklus_Sa "Timer 4 für Wochentag gesetzt";
CM_ SG_ 1398 MOD_Set_Timer_4_Zyklus_So "Timer 4 für Wochentag gesetzt";
CM_ SG_ 1398 MOD_Set_Timer_4_Zyklus_WH "Timer 4 ist zur einmaligen Auslösung gestezt oder wiederholt sich";
CM_ SG_ 1398 MOD_Set_Timer_1_Jahr "Status Timer 1 gesetztes Datum -> Jahr";
CM_ SG_ 1398 MOD_Set_Timer_2_Jahr "Status Timer 2 gesetztes Datum -> Jahr";
CM_ SG_ 1398 MOD_Set_Timer_3_Jahr "Status Timer 3 gesetztes Datum -> Jahr";
CM_ SG_ 1398 MOD_Set_Timer_1_Minute "Status Timer 1 gesetztes Datum -> Minute";
CM_ SG_ 1398 MOD_Set_Timer_2_Minute "Status Timer 2 gesetztes Datum -> Minute";
CM_ SG_ 1398 MOD_Set_Timer_3_Minute "Status Timer 3 gesetztes Datum -> Minute";
CM_ SG_ 1398 MOD_Set_Timer_1_Monat "Status Timer 1 gesetztes Datum -> Monat";
CM_ SG_ 1398 MOD_Set_Timer_2_Monat "Status Timer 2 gesetztes Datum -> Monat";
CM_ SG_ 1398 MOD_Set_Timer_3_Monat "Status Timer 3 gesetztes Datum -> Monat";
CM_ SG_ 1398 MOD_Set_Timer_1_Stunde "Status Timer 1 gesetztes Datum -> Stunde";
CM_ SG_ 1398 MOD_Set_Timer_2_Stunde "Status Timer 2 gesetztes Datum -> Stunde";
CM_ SG_ 1398 MOD_Set_Timer_3_Stunde "Status Timer 3 gesetztes Datum -> Stunde";
CM_ SG_ 1398 MOD_Set_Timer_1_Tag "Status Timer 1 gesetztes Datum -> Tag";
CM_ SG_ 1398 MOD_Set_Timer_2_Tag "Status Timer 2 gesetztes Datum -> Tag";
CM_ SG_ 1398 MOD_Set_Timer_3_Tag "Status Timer 3 gesetztes Datum -> Tag";
CM_ SG_ 1398 MOD_Set_Timer_1_Laden "Status des Ladetimers 1";
CM_ SG_ 1398 MOD_Set_Timer_2_Laden "Status des Ladetimers 2";
CM_ SG_ 1398 MOD_Set_Timer_3_Laden "Status des Ladetimers 3";
CM_ SG_ 1398 MOD_Set_Timer_1_Vorklima "Status des Vorklimatisierungs-Timers 1";
CM_ SG_ 1398 MOD_Set_Timer_2_Vorklima "Status des Vorklimatisierungs-Timers 2";
CM_ SG_ 1398 MOD_Set_Timer_3_Vorklima "Status des Vorklimatisierungs-Timers 3";
CM_ SG_ 1398 MOD_Set_Timer_1_Zyklus_Mo "Timer 1 für Wochentag gesetzt";
CM_ SG_ 1398 MOD_Set_Timer_2_Zyklus_Mo "Timer 2 für Wochentag gesetzt";
CM_ SG_ 1398 MOD_Set_Timer_3_Zyklus_Mo "Timer 3 für Wochentag gesetzt";
CM_ SG_ 1398 MOD_Set_Timer_1_Zyklus_Di "Timer 1 für Wochentag gesetzt";
CM_ SG_ 1398 MOD_Set_Timer_2_Zyklus_Di "Timer 2 für Wochentag gesetzt";
CM_ SG_ 1398 MOD_Set_Timer_3_Zyklus_Di "Timer 3 für Wochentag gesetzt";
CM_ SG_ 1398 MOD_Set_Timer_1_Zyklus_Mi "Timer 1 für Wochentag gesetzt";
CM_ SG_ 1398 MOD_Set_Timer_2_Zyklus_Mi "Timer 2 für Wochentag gesetzt";
CM_ SG_ 1398 MOD_Set_Timer_3_Zyklus_Mi "Timer 3 für Wochentag gesetzt";
CM_ SG_ 1398 MOD_Set_Timer_1_Zyklus_Do "Timer 1 für Wochentag gesetzt";
CM_ SG_ 1398 MOD_Set_Timer_2_Zyklus_Do "Timer 2 für Wochentag gesetzt";
CM_ SG_ 1398 MOD_Set_Timer_3_Zyklus_Do "Timer 3 für Wochentag gesetzt";
CM_ SG_ 1398 MOD_Set_Timer_1_Zyklus_Fr "Timer 1 für Wochentag gesetzt";
CM_ SG_ 1398 MOD_Set_Timer_2_Zyklus_Fr "Timer 2 für Wochentag gesetzt";
CM_ SG_ 1398 MOD_Set_Timer_3_Zyklus_Fr "Timer 3 für Wochentag gesetzt";
CM_ SG_ 1398 MOD_Set_Timer_1_Zyklus_Sa "Timer 1 für Wochentag gesetzt";
CM_ SG_ 1398 MOD_Set_Timer_2_Zyklus_Sa "Timer 2 für Wochentag gesetzt";
CM_ SG_ 1398 MOD_Set_Timer_3_Zyklus_Sa "Timer 3 für Wochentag gesetzt";
CM_ SG_ 1398 MOD_Set_Timer_1_Zyklus_So "Timer 1 für Wochentag gesetzt";
CM_ SG_ 1398 MOD_Set_Timer_2_Zyklus_So "Timer 2 für Wochentag gesetzt";
CM_ SG_ 1398 MOD_Set_Timer_3_Zyklus_So "Timer 3 für Wochentag gesetzt";
CM_ SG_ 1398 MOD_Set_Timer_1_Zyklus_WH "Timer 1 ist zur einmaligen Auslösung gestezt oder wiederholt sich";
CM_ SG_ 1398 MOD_Set_Timer_2_Zyklus_WH "Timer 2 ist zur einmaligen Auslösung gestezt oder wiederholt sich";
CM_ SG_ 1398 MOD_Set_Timer_MUX "Multiplexor zur Anzeige des aktuell übertragenden und zu setzenden Timers";
CM_ SG_ 1398 MOD_Set_Timer_3_Zyklus_WH "Timer 3 ist zur einmaligen Auslösung gestezt oder wiederholt sich";
CM_ SG_ 1398 MOD_Set_Nachtstrom_X_Std_Anf "Anfangszeit für Setzen der Nachtstromtabelle im Profil X - gibt die volle halbe Stunde an
(Aktuell zu setzendes Profil wird im Signal MOD_Set_Nachtstrom_Profil angezeigt)";
CM_ SG_ 1398 MOD_Set_Nachtstrom_Prof "Zusammenfassung Zeitraum 1¿3 zu einem Profil für Setzen der Nachtstromtabelle";
CM_ SG_ 1398 MOD_Set_Nachtstrom_X_Std_End "Endezeit für Setzen der Nachtstromtabelle im Profil X - gibt die volle halbe Stunde an
(Aktuell zu setzendes Profil wird im Signal MOD_Set_Nachtstrom_Profil angezeigt)";
CM_ SG_ 1398 MOD_Set_Nachtstrom_Akt_Prof "Setzen des eingestellten Nachtstrom-Profils";
CM_ SG_ 1398 MOD_Set_Abbruch_Klima "Sofortiger Abbruch der Vorklimatisierung über Standklimatisierung (PHEV über HVLM) oder Standheizung (konventionell über KBI).";
CM_ SG_ 1398 MOD_Set_Sofortstart_Klima "Sofortige Aktivierung der Vorklimatisierung über Standklimatisierung (PHEV über HVLM) oder Standheizung (konventionell über KBI).";
CM_ SG_ 1398 MOD_Anf_Spiegel_anklappen "Anforderung durch MOD die Außenspiegel anzuklappen";
CM_ SG_ 1398 MOD_Anf_ZV "Anforderung durch MOD ZV verriegeln/ entriegeln";
CM_ BO_ 1397 "nur für PAG - Mobile Online Dienste";
CM_ SG_ 1397 HVLM_Status_naechster_Ladetimer "Übermittlung des nächsten aktiven Ladetimers.";
CM_ SG_ 1397 HVLM_Status_naechster_Klimatimer "Übermittlung des nächsten aktiven Klimatimers.";
CM_ SG_ 1397 HVLM_Status_Timer_7_Laden "Status des Ladetimers 7";
CM_ SG_ 1397 HVLM_Ladetexte "Anzeige, ob AC- oder DC-Laden nicht möglich ist";
CM_ SG_ 1397 HVLM_Status_Timer_4_Jahr "Status Timer 4 gesetztes Datum -> Jahr";
CM_ SG_ 1397 HVLM_Status_Timer_4_Minute "Status Timer 4 gesetztes Datum -> Minute";
CM_ SG_ 1397 HVLM_Status_Timer_4_Monat "Status Timer 4 gesetztes Datum -> Monat";
CM_ SG_ 1397 HVLM_Status_Timer_4_Stunde "Status Timer 4 gesetztes Datum -> Stunde";
CM_ SG_ 1397 HVLM_Status_Timer_4_Tag "Status Timer 4 gesetztes Datum -> Tag";
CM_ SG_ 1397 HVLM_Status_Timer_4_Laden "Status des Ladetimers 4";
CM_ SG_ 1397 HVLM_Status_Timer_4_Vorklima "Status des Vorklimatisierungs-Timers 4";
CM_ SG_ 1397 HVLM_Status_Timer_4_Zyklus_Mo "Timer 4 für Wochentag gesetzt";
CM_ SG_ 1397 HVLM_Status_Timer_2_Vorklima "Status des Vorklimatisierungs-Timers 2";
CM_ SG_ 1397 HVLM_Status_Timer_3_Vorklima "Status des Vorklimatisierungs-Timers 3";
CM_ SG_ 1397 HVLM_Status_Timer_1_Zyklus_Mo "Timer 1 für Wochentag gesetzt";
CM_ SG_ 1397 HVLM_Status_Timer_2_Zyklus_Mo "Timer 2 für Wochentag gesetzt";
CM_ SG_ 1397 HVLM_Status_Timer_3_Zyklus_Mo "Timer 3 für Wochentag gesetzt";
CM_ SG_ 1397 HVLM_Status_Timer_1_Zyklus_Di "Timer 1 für Wochentag gesetzt";
CM_ SG_ 1397 HVLM_Status_Timer_2_Zyklus_Di "Timer 2 für Wochentag gesetzt";
CM_ SG_ 1397 HVLM_Status_Timer_3_Zyklus_Di "Timer 3 für Wochentag gesetzt";
CM_ SG_ 1397 HVLM_Status_Timer_1_Zyklus_Mi "Timer 1 für Wochentag gesetzt";
CM_ SG_ 1397 HVLM_Status_Timer_2_Zyklus_Mi "Timer 2 für Wochentag gesetzt";
CM_ SG_ 1397 HVLM_Status_Timer_3_Zyklus_Mi "Timer 3 für Wochentag gesetzt";
CM_ SG_ 1397 HVLM_Status_Timer_1_Zyklus_Do "Timer 1 für Wochentag gesetzt";
CM_ SG_ 1397 HVLM_Status_Timer_2_Zyklus_Do "Timer 2 für Wochentag gesetzt";
CM_ SG_ 1397 HVLM_Status_Timer_3_Zyklus_Do "Timer 3 für Wochentag gesetzt";
CM_ SG_ 1397 HVLM_Status_Timer_1_Zyklus_Fr "Timer 1 für Wochentag gesetzt";
CM_ SG_ 1397 HVLM_Status_Timer_2_Zyklus_Fr "Timer 2 für Wochentag gesetzt";
CM_ SG_ 1397 HVLM_Status_Timer_3_Zyklus_Fr "Timer 3 für Wochentag gesetzt";
CM_ SG_ 1397 HVLM_Status_Timer_1_Zyklus_Sa "Timer 1 für Wochentag gesetzt";
CM_ SG_ 1397 HVLM_Status_Timer_2_Zyklus_Sa "Timer 2 für Wochentag gesetzt";
CM_ SG_ 1397 HVLM_Status_Timer_3_Zyklus_Sa "Timer 3 für Wochentag gesetzt";
CM_ SG_ 1397 HVLM_Status_Timer_1_Zyklus_So "Timer 1 für Wochentag gesetzt";
CM_ SG_ 1397 HVLM_Status_Timer_2_Zyklus_So "Timer 2 für Wochentag gesetzt";
CM_ SG_ 1397 HVLM_Status_Timer_3_Zyklus_So "Timer 3 für Wochentag gesetzt";
CM_ SG_ 1397 HVLM_Status_Timer_1_Zyklus_WH "Timer 1 ist zur einmaligen Auslösung gestezt oder wiederholt sich";
CM_ SG_ 1397 HVLM_Status_Timer_2_Zyklus_WH "Timer 2 ist zur einmaligen Auslösung gestezt oder wiederholt sich";
CM_ SG_ 1397 HVLM_Status_Timer_MUX "Multiplexor zur Anzeige des aktuell übertragenden Timer-Status (0x1-0x3) und Wecktimer (0x7)";
CM_ SG_ 1397 HVLM_Status_Timer_3_Zyklus_WH "Timer 3 ist zur einmaligen Auslösung gestezt oder wiederholt sich";
CM_ SG_ 1397 HVLM_Status_Nachtstrom_X_Std_Anf "Anfangszeit für Setzen der Nachtstromtabelle im Profil X - gibt die volle halbe Stunde an
(Aktuell zu setzendes Profil wird im Signal HVLM_Status_Nachtstrom_Profil angezeigt)";
CM_ SG_ 1397 HVLM_Status_Nachtstrom_Prof "Zusammenfassung Zeitraum 1..3 zu einem Profil für Setzen der Nachtstromtabelle";
CM_ SG_ 1397 HVLM_Status_Nachtstrom_X_Std_End "Endezeit für Setzen der Nachtstromtabelle im Profil X - gibt die volle halbe Stunde an
(Aktuell zu setzendes Profil wird im Signal HVLM_Status_Nachtstrom_Profil angezeigt)";
CM_ SG_ 1397 HVLM_Status_Nachtstrom_Akt_Prof "Status: aktuell eingestelltes Nachtstrom-Profil";
CM_ SG_ 1397 HVLM_Status_Laden "aktueller Status des Ladevorgangs";
CM_ SG_ 1397 HVLM_Status_Timer_4_Zyklus_Di "Timer 4 für Wochentag gesetzt";
CM_ SG_ 1397 HVLM_Status_Timer_4_Zyklus_Mi "Timer 4 für Wochentag gesetzt";
CM_ SG_ 1397 HVLM_Status_Timer_4_Zyklus_Do "Timer 4 für Wochentag gesetzt";
CM_ SG_ 1397 HVLM_Status_Timer_4_Zyklus_Fr "Timer 4 für Wochentag gesetzt";
CM_ SG_ 1397 HVLM_Status_Timer_1_Jahr "Status Timer 1 gesetztes Datum -> Jahr";
CM_ SG_ 1397 HVLM_Status_Timer_2_Jahr "Status Timer 2 gesetztes Datum -> Jahr";
CM_ SG_ 1397 HVLM_Status_Timer_3_Jahr "Status Timer 3 gesetztes Datum -> Jahr";
CM_ SG_ 1397 HVLM_Status_Timer_7_Jahr "Status Timer 7 gesetztes Datum -> Jahr";
CM_ SG_ 1397 HVLM_Status_Timer_1_Minute "Status Timer 1 gesetztes Datum -> Minute";
CM_ SG_ 1397 HVLM_Status_Timer_2_Minute "Status Timer 2 gesetztes Datum -> Minute";
CM_ SG_ 1397 HVLM_Status_Timer_3_Minute "Status Timer 3 gesetztes Datum -> Minute";
CM_ SG_ 1397 HVLM_Status_Timer_7_Minute "Status Timer 7 gesetztes Datum -> Minute";
CM_ SG_ 1397 HVLM_Status_Timer_1_Monat "Status Timer 1 gesetztes Datum -> Monat";
CM_ SG_ 1397 HVLM_Status_Timer_2_Monat "Status Timer 2 gesetztes Datum -> Monat";
CM_ SG_ 1397 HVLM_Status_Timer_3_Monat "Status Timer 3 gesetztes Datum -> Monat";
CM_ SG_ 1397 HVLM_Status_Timer_7_Monat "Status Timer 7 gesetztes Datum -> Monat";
CM_ SG_ 1397 HVLM_Status_Timer_1_Stunde "Status Timer 1 gesetztes Datum -> Stunde";
CM_ SG_ 1397 HVLM_Status_Timer_2_Stunde "Status Timer 2 gesetztes Datum -> Stunde";
CM_ SG_ 1397 HVLM_Status_Timer_3_Stunde "Status Timer 3 gesetztes Datum -> Stunde";
CM_ SG_ 1397 HVLM_Status_Timer_7_Stunde "Status Timer 7 gesetztes Datum -> Stunde";
CM_ SG_ 1397 HVLM_Status_Timer_1_Tag "Status Timer 1 gesetztes Datum -> Tag";
CM_ SG_ 1397 HVLM_Status_Timer_2_Tag "Status Timer 2 gesetztes Datum -> Tag";
CM_ SG_ 1397 HVLM_Status_Timer_3_Tag "Status Timer 3 gesetztes Datum -> Tag";
CM_ SG_ 1397 HVLM_Status_Timer_7_Tag "Status Timer 1 gesetztes Datum -> Tag";
CM_ SG_ 1397 HVLM_Status_Timer_1_Laden "Status des Ladetimers 1";
CM_ SG_ 1397 HVLM_Status_Timer_2_Laden "Status des Ladetimers 2";
CM_ SG_ 1397 HVLM_Status_Timer_3_Laden "Status des Ladetimers 3";
CM_ SG_ 1397 HVLM_Status_Timer_1_Vorklima "Status des Vorklimatisierungs-Timers 1";
CM_ SG_ 1397 HVLM_Status_Timer_4_Zyklus_Sa "Timer 4 für Wochentag gesetzt";
CM_ SG_ 1397 HVLM_Status_Timer_4_Zyklus_So "Timer 4 für Wochentag gesetzt";
CM_ SG_ 1397 HVLM_Status_Timer_4_Zyklus_WH "Timer 4 ist zur einmaligen Auslösung gestezt oder wiederholt sich";
BA_DEF_  "BusType" STRING ;
BA_DEF_ SG_  "DERIVATE_Pruefung" ENUM  "offen","geprüft";
BA_DEF_ SG_  "HYB_Rx_Baureihe" ENUM  "G1+Derivate","nur G1","nur Derivate";
BA_DEF_ SG_  "HYB_Rx_Verwendung" ENUM  "DERIV_Rout","DERIV_Calc","DERIV_Rout+DERIV_Calc";
BA_DEF_ SG_  "GenSigSwitchedByIgnition" ENUM  "No","Yes";
BA_DEF_ SG_  "GenSigEnvVarType" ENUM  "int","float","undef";
BA_DEF_ SG_  "GenSigAutoGenSnd" ENUM  "No","Yes";
BA_DEF_ SG_  "GenSigAutoGenDsp" ENUM  "No","Yes";
BA_DEF_ SG_  "GenSigActiveRepetitions" INT -2147483648 2147483647;
BA_DEF_ SG_  "GenSigFuncType" ENUM  "NoFunction","MsgCounter","CRC-8","XOR","XOR-2","DatedBit","SW-Kl15","CHK","Constant","Protocol";
BA_DEF_ SG_  "Info_BCM_HutHut_Kommunikation" ENUM  "Nein","Ja";
BA_DEF_ SG_  "NWM-WakeupAllowed" ENUM  "No","Yes";
BA_DEF_ SG_  "GenSigInactiveValue" STRING ;
BA_DEF_ SG_  "GenSigMissingSourceValue" INT 0 2147483647;
BA_DEF_ SG_  "GenSigStartValue" INT 0 0;
BA_DEF_ SG_  "Fehlerwert" HEX 0 2147483647;
BA_DEF_ SG_  "Bemerkung" STRING ;
BA_DEF_ SG_  "GenSigSendType" ENUM  "Cyclic","OnWrite","OnWriteWithRepetition","OnChange","OnChangeWithRepetition","IfActive","IfActiveWithRepetition","NoSigSendType";
BA_DEF_ BO_  "NmMessage" ENUM  "No","Yes";
BA_DEF_ BO_  "GenMsgAutoGenSnd" ENUM  "No","Yes";
BA_DEF_ BO_  "GenMsgAutoGenDsp" ENUM  "No","Yes";
BA_DEF_ BO_  "MsgType" ENUM  "Broadcast","Event","NM ","NMH","TP2.0","ISO-TP ","BAP","EID";
BA_DEF_ BO_  "GenMsgChkConstant" HEX 0 4095;
BA_DEF_ BO_  "sim_GenMsgILSupport" ENUM  "No","Yes";
BA_DEF_ BO_  "NWM-Botschaft" ENUM  "No","Yes";
BA_DEF_ BO_  "VAGTP20_StatConnection" ENUM  "No","Yes";
BA_DEF_ BO_  "VAGTP20_DynSetup" ENUM  "No","Yes";
BA_DEF_ BO_  "VAGTP20_DynConnection" ENUM  "No","Yes";
BA_DEF_ BO_  "VAGTP20_API" HEX 0 255;
BA_DEF_ BO_  "Direkt_1zu1" ENUM  "Nein","Ja";
BA_DEF_ BO_  "GenMsgSendType" ENUM  "Cyclic","NotUsed","NotUsed","NotUsed","NotUsed","NotUsed","NotUsed","IfActive","NoMsgSendType","NotUsed";
BA_DEF_ BO_  "DiagResponse" ENUM  "No","Yes";
BA_DEF_ BO_  "DiagRequest" ENUM  "No","Yes";
BA_DEF_ BO_  "GenMsgDelayTime" INT 0 65535;
BA_DEF_ BO_  "GenMsgStartDelayTime" INT 0 65535;
BA_DEF_ BO_  "GenMsgILSupport" ENUM  "No","Yes";
BA_DEF_ BO_  "NmhMessage" ENUM  "No","Yes";
BA_DEF_ BO_  "GenMsgNrOfRepetition" INT 0 65535;
BA_DEF_ BO_  "GenMsgCycleTimeFast" INT 0 65535;
BA_DEF_ BO_  "DiagState" ENUM  "No","Yes";
BA_DEF_ BO_  "GenMsgCycleTime" INT 0 65535;
BA_DEF_ BU_  "ECUVariantDefault" ENUM  "No","Yes";
BA_DEF_ BU_  "GenNodAutoGenSnd" ENUM  "No","Yes";
BA_DEF_ BU_  "GenNodAutoGenDsp" ENUM  "No","Yes";
BA_DEF_ BU_  "sim_ILUsed" ENUM  "No","Yes";
BA_DEF_ BU_  "NodeLayerModules" STRING ;
BA_DEF_ BU_  "ILUsed" ENUM  "No","Yes";
BA_DEF_ BU_  "NmhNode" ENUM  "No","Yes","vector_leerstring";
BA_DEF_ BU_  "SG_Bauteilverantwortlicher" STRING ;
BA_DEF_  "NmhLongTimer" INT 0 65535;
BA_DEF_  "NmhPrepareBussleepTimer" INT 0 65535;
BA_DEF_  "NmhWaitBusSleepTimer" INT 0 65535;
BA_DEF_  "NmhTimeoutTimer" INT 0 65535;
BA_DEF_  "VersionMonth" INT 0 12;
BA_DEF_  "VersionDay" INT 0 31;
BA_DEF_  "GenNWMSleepTime" INT 0 1000000;
BA_DEF_  "VersionYear" INT 2005 2050;
BA_DEF_  "VersionWeek" INT 0 53;
BA_DEF_  "VersionNumber" INT 0 65535;
BA_DEF_  "Manufacturer" STRING ;
BA_DEF_  "NmhMessageCount" INT 1 256;
BA_DEF_  "NmhBaseAddress" HEX 0 536870911;
BA_DEF_  "NmType" STRING ;
BA_DEF_  "DBName" STRING ;
BA_DEF_  "Baudrate" INT 0 1000000;
BA_DEF_  "SamplePointMin" INT 0 100;
BA_DEF_  "SamplePointMax" INT 0 100;
BA_DEF_  "SyncJumpWidthMin" INT 2 2;
BA_DEF_  "SyncJumpWidthMax" INT 3 3;
BA_DEF_REL_ BU_BO_REL_  "HYB_Tx_Verwendung" ENUM  "Rout","Calc";
BA_DEF_REL_ BU_BO_REL_  "HYB_Tx_Baureihe" ENUM  "G1+Derivate","G1","Derivate","vector_leerstring";
BA_DEF_REL_ BU_SG_REL_  "GenSigTimeoutTime" INT 0 65535;
BA_DEF_DEF_  "BusType" "";
BA_DEF_DEF_REL_ "HYB_Tx_Verwendung" "Rout";
BA_DEF_DEF_REL_ "HYB_Tx_Baureihe" "G1+Derivate";
BA_DEF_DEF_  "DERIVATE_Pruefung" "offen";
BA_DEF_DEF_  "HYB_Rx_Baureihe" "G1+Derivate";
BA_DEF_DEF_  "HYB_Rx_Verwendung" "DERIV_Rout";
BA_DEF_DEF_  "GenSigSwitchedByIgnition" "No";
BA_DEF_DEF_  "GenSigEnvVarType" "undef";
BA_DEF_DEF_  "GenSigAutoGenSnd" "No";
BA_DEF_DEF_  "GenSigAutoGenDsp" "No";
BA_DEF_DEF_  "GenSigActiveRepetitions" 0;
BA_DEF_DEF_  "GenSigFuncType" "NoFunction";
BA_DEF_DEF_  "Info_BCM_HutHut_Kommunikation" "Nein";
BA_DEF_DEF_  "NWM-WakeupAllowed" "Yes";
BA_DEF_DEF_  "GenSigInactiveValue" "0";
BA_DEF_DEF_  "GenSigMissingSourceValue" 0;
BA_DEF_DEF_  "GenSigStartValue" 0;
BA_DEF_DEF_  "Fehlerwert" 0;
BA_DEF_DEF_  "Bemerkung" "";
BA_DEF_DEF_  "GenSigSendType" "Cyclic";
BA_DEF_DEF_  "NmMessage" "No";
BA_DEF_DEF_  "GenMsgAutoGenSnd" "Yes";
BA_DEF_DEF_  "GenMsgAutoGenDsp" "Yes";
BA_DEF_DEF_  "MsgType" "Broadcast";
BA_DEF_DEF_  "GenMsgChkConstant" 0;
BA_DEF_DEF_  "sim_GenMsgILSupport" "No";
BA_DEF_DEF_  "NWM-Botschaft" "No";
BA_DEF_DEF_  "VAGTP20_StatConnection" "No";
BA_DEF_DEF_  "VAGTP20_DynSetup" "No";
BA_DEF_DEF_  "VAGTP20_DynConnection" "No";
BA_DEF_DEF_  "VAGTP20_API" 1;
BA_DEF_DEF_  "Direkt_1zu1" "Nein";
BA_DEF_DEF_  "GenMsgSendType" "Cyclic";
BA_DEF_DEF_  "DiagResponse" "No";
BA_DEF_DEF_  "DiagRequest" "No";
BA_DEF_DEF_  "GenMsgDelayTime" 0;
BA_DEF_DEF_  "GenMsgStartDelayTime" 0;
BA_DEF_DEF_  "GenMsgILSupport" "No";
BA_DEF_DEF_  "NmhMessage" "No";
BA_DEF_DEF_  "GenMsgNrOfRepetition" 0;
BA_DEF_DEF_  "GenMsgCycleTimeFast" 0;
BA_DEF_DEF_  "DiagState" "No";
BA_DEF_DEF_  "GenMsgCycleTime" 0;
BA_DEF_DEF_REL_ "GenSigTimeoutTime" 0;
BA_DEF_DEF_  "ECUVariantDefault" "Yes";
BA_DEF_DEF_  "GenNodAutoGenSnd" "Yes";
BA_DEF_DEF_  "GenNodAutoGenDsp" "Yes";
BA_DEF_DEF_  "sim_ILUsed" "No";
BA_DEF_DEF_  "NodeLayerModules" "CANoeILNLVector.dll";
BA_DEF_DEF_  "ILUsed" "No";
BA_DEF_DEF_  "NmhNode" "No";
BA_DEF_DEF_  "SG_Bauteilverantwortlicher" "";
BA_DEF_DEF_  "NmhLongTimer" 100;
BA_DEF_DEF_  "NmhPrepareBussleepTimer" 500;
BA_DEF_DEF_  "NmhWaitBusSleepTimer" 750;
BA_DEF_DEF_  "NmhTimeoutTimer" 1000;
BA_DEF_DEF_  "VersionMonth" 0;
BA_DEF_DEF_  "VersionDay" 0;
BA_DEF_DEF_  "GenNWMSleepTime" 5000;
BA_DEF_DEF_  "VersionYear" 2005;
BA_DEF_DEF_  "VersionWeek" 0;
BA_DEF_DEF_  "VersionNumber" 0;
BA_DEF_DEF_  "Manufacturer" "PAG";
BA_DEF_DEF_  "NmhMessageCount" 64;
BA_DEF_DEF_  "NmhBaseAddress" 1728;
BA_DEF_DEF_  "NmType" "None";
BA_DEF_DEF_  "DBName" "";
BA_DEF_DEF_  "Baudrate" 500000;
BA_DEF_DEF_  "SamplePointMin" 75;
BA_DEF_DEF_  "SamplePointMax" 85;
BA_DEF_DEF_  "SyncJumpWidthMin" 2;
BA_DEF_DEF_  "SyncJumpWidthMax" 3;
BA_ "NmhLongTimer" 200;
BA_ "VersionMonth" 7;
BA_ "VersionDay" 27;
BA_ "VersionYear" 2012;
BA_ "VersionWeek" 30;
BA_ "VersionNumber" 1201;
BA_ "NmType" "NM-High";
BA_ "BusType" "CAN";
BA_ "DBName" "CAN_Antrieb_Derivate";
BA_ "sim_ILUsed" BU_ Sound_A 1;
BA_ "NodeLayerModules" BU_ Sound_A "";
BA_ "ILUsed" BU_ Sound_A 1;
BA_ "SG_Bauteilverantwortlicher" BU_ Ladegeraet_PAG_PF "Dirk Herke";
BA_ "sim_ILUsed" BU_ Ladegeraet_PAG_PF 1;
BA_ "NodeLayerModules" BU_ Ladegeraet_PAG_PF "CANoeILNLVAG.dll, NMHigh.DLL";
BA_ "ILUsed" BU_ Ladegeraet_PAG_PF 1;
BA_ "NmhNode" BU_ Ladegeraet_PAG_PF 1;
BA_ "SG_Bauteilverantwortlicher" BU_ Motor_EDC17_Pirol "Tobias Berr";
BA_ "sim_ILUsed" BU_ Motor_EDC17_Pirol 1;
BA_ "NodeLayerModules" BU_ Motor_EDC17_Pirol "CANoeILNLVAG.dll, NMHigh.DLL";
BA_ "ILUsed" BU_ Motor_EDC17_Pirol 1;
BA_ "NmhNode" BU_ Motor_EDC17_Pirol 1;
BA_ "SG_Bauteilverantwortlicher" BU_ PSM_Ant_Derivate "Ralf Eichele";
BA_ "sim_ILUsed" BU_ PSM_Ant_Derivate 1;
BA_ "NodeLayerModules" BU_ PSM_Ant_Derivate "CANoeILNLVAG.dll, NMHigh.DLL";
BA_ "ILUsed" BU_ PSM_Ant_Derivate 1;
BA_ "NmhNode" BU_ PSM_Ant_Derivate 1;
BA_ "SG_Bauteilverantwortlicher" BU_ GW_Routing_Derivate "Karl-Peter Spring";
BA_ "sim_ILUsed" BU_ GW_Routing_Derivate 1;
BA_ "NodeLayerModules" BU_ GW_Routing_Derivate "CANoeILNLVAG.dll, NMHigh.DLL";
BA_ "ILUsed" BU_ GW_Routing_Derivate 1;
BA_ "NmhNode" BU_ GW_Routing_Derivate 1;
BA_ "SG_Bauteilverantwortlicher" BU_ GW_Applikation_Derivate "Karl-Peter Spring";
BA_ "sim_ILUsed" BU_ GW_Applikation_Derivate 1;
BA_ "NodeLayerModules" BU_ GW_Applikation_Derivate "CANoeILNLVAG.dll, NMHigh.DLL";
BA_ "ILUsed" BU_ GW_Applikation_Derivate 1;
BA_ "NmhNode" BU_ GW_Applikation_Derivate 1;
BA_ "SG_Bauteilverantwortlicher" BU_ BMS_Hybrid "Thomas Fritz";
BA_ "sim_ILUsed" BU_ BMS_Hybrid 1;
BA_ "NodeLayerModules" BU_ BMS_Hybrid "CANoeILNLVAG.dll, NMHigh.DLL";
BA_ "ILUsed" BU_ BMS_Hybrid 1;
BA_ "NmhNode" BU_ BMS_Hybrid 1;
BA_ "SG_Bauteilverantwortlicher" BU_ Getriebe_Derivate "Hans-Jürgen Renk";
BA_ "sim_ILUsed" BU_ Getriebe_Derivate 1;
BA_ "NodeLayerModules" BU_ Getriebe_Derivate "CANoeILNLVAG.dll, NMHigh.DLL";
BA_ "ILUsed" BU_ Getriebe_Derivate 1;
BA_ "NmhNode" BU_ Getriebe_Derivate 1;
BA_ "SG_Bauteilverantwortlicher" BU_ LEH_Hybrid "Wolfgang Steck";
BA_ "sim_ILUsed" BU_ LEH_Hybrid 1;
BA_ "NodeLayerModules" BU_ LEH_Hybrid "CANoeILNLVAG.dll, NMHigh.DLL";
BA_ "ILUsed" BU_ LEH_Hybrid 1;
BA_ "NmhNode" BU_ LEH_Hybrid 1;
BA_ "SG_Bauteilverantwortlicher" BU_ Motor_MED17_Hybrid "Christian Wiedenbrügge";
BA_ "sim_ILUsed" BU_ Motor_MED17_Hybrid 1;
BA_ "NodeLayerModules" BU_ Motor_MED17_Hybrid "CANoeILNLVAG.dll, NMHigh.DLL";
BA_ "ILUsed" BU_ Motor_MED17_Hybrid 1;
BA_ "NmhNode" BU_ Motor_MED17_Hybrid 1;
BA_ "sim_ILUsed" BU_ Sound_I 1;
BA_ "NodeLayerModules" BU_ Sound_I "";
BA_ "ILUsed" BU_ Sound_I 1;
BA_ "SG_Bauteilverantwortlicher" BU_ Tool "Thomas Krause";
BA_ "NodeLayerModules" BU_ Tool "CANoeILNLVAG.dll";
BA_ "ILUsed" BU_ Tool 1;
BA_ "SG_Bauteilverantwortlicher" BU_ Airbag "John Hasenclever";
BA_ "sim_ILUsed" BU_ Airbag 1;
BA_ "NodeLayerModules" BU_ Airbag "CANoeILNLVAG.dll";
BA_ "ILUsed" BU_ Airbag 1;
BA_ "SG_Bauteilverantwortlicher" BU_ Waehlhebel "Peter Knysch";
BA_ "sim_ILUsed" BU_ Waehlhebel 1;
BA_ "NodeLayerModules" BU_ Waehlhebel "CANoeILNLVAG.dll";
BA_ "ILUsed" BU_ Waehlhebel 1;
BA_ "MsgType" BO_ 1728 3;
BA_ "VAGTP20_API" BO_ 1728 0;
BA_ "GenMsgSendType" BO_ 1728 8;
BA_ "NmhMessage" BO_ 1728 1;
BA_ "GenMsgCycleTime" BO_ 1728 200;
BA_ "VAGTP20_API" BO_ 1327 0;
BA_ "GenMsgILSupport" BO_ 1327 1;
BA_ "GenMsgCycleTime" BO_ 1327 200;
BA_ "VAGTP20_API" BO_ 1381 0;
BA_ "GenMsgDelayTime" BO_ 1381 50;
BA_ "GenMsgILSupport" BO_ 1381 1;
BA_ "GenMsgCycleTime" BO_ 1381 500;
BA_ "VAGTP20_API" BO_ 1534 0;
BA_ "GenMsgILSupport" BO_ 1534 1;
BA_ "GenMsgCycleTime" BO_ 1534 1000;
BA_ "VAGTP20_API" BO_ 1631 0;
BA_ "GenMsgILSupport" BO_ 1631 1;
BA_ "GenMsgCycleTime" BO_ 1631 500;
BA_ "VAGTP20_API" BO_ 1398 0;
BA_ "GenMsgILSupport" BO_ 1398 1;
BA_ "GenMsgCycleTime" BO_ 1398 800;
BA_ "VAGTP20_API" BO_ 1397 0;
BA_ "GenMsgILSupport" BO_ 1397 1;
BA_ "GenMsgCycleTime" BO_ 1397 800;
BA_ "NWM-WakeupAllowed" SG_ 3221225472 KBI_Trip_E_Std 0;
BA_ "Bemerkung" SG_ 3221225472 KBI_Trip_E_Std "Kurzzeitzähler / Fahrdaten seit hh::mm";
BA_ "NWM-WakeupAllowed" SG_ 3221225472 KBI_Trip_E_Min 0;
BA_ "Bemerkung" SG_ 3221225472 KBI_Trip_E_Min "Kurzzeitzähler / Fahrdaten seit hh::mm";
BA_ "NWM-WakeupAllowed" SG_ 3221225472 KBI_Service_km 0;
BA_ "GenSigStartValue" SG_ 3221225472 KBI_Service_km 1022;
BA_ "Fehlerwert" SG_ 3221225472 KBI_Service_km 1023;
BA_ "NWM-WakeupAllowed" SG_ 3221225472 KBI_Service_Zeit 0;
BA_ "GenSigStartValue" SG_ 3221225472 KBI_Service_Zeit 2046;
BA_ "Fehlerwert" SG_ 3221225472 KBI_Service_Zeit 2047;
BA_ "NWM-WakeupAllowed" SG_ 3221225472 KBI_Service_Typ 0;
BA_ "NWM-WakeupAllowed" SG_ 3221225472 DEV_BMS_Resp_07_Data 0;
BA_ "NWM-WakeupAllowed" SG_ 3221225472 DEV_BMS_Resp_06_Data 0;
BA_ "NWM-WakeupAllowed" SG_ 3221225472 DEV_BMS_Resp_05_Data 0;
BA_ "NWM-WakeupAllowed" SG_ 3221225472 Mo_HVEM_HV_Abschaltanf 0;
BA_ "NWM-WakeupAllowed" SG_ 3221225472 MO_HVEM_HV_Maxleistung 0;
BA_ "GenSigStartValue" SG_ 3221225472 MO_HVEM_HV_Maxleistung 254;
BA_ "Fehlerwert" SG_ 3221225472 MO_HVEM_HV_Maxleistung 255;
BA_ "NWM-WakeupAllowed" SG_ 3221225472 HVEM_Istleistung_Nebenverbrauch 0;
BA_ "GenSigStartValue" SG_ 3221225472 HVEM_Istleistung_Nebenverbrauch 254;
BA_ "Fehlerwert" SG_ 3221225472 HVEM_Istleistung_Nebenverbrauch 255;
BA_ "NWM-WakeupAllowed" SG_ 3221225472 BMS_TauKuehlmittel__Temp_ 0;
BA_ "NWM-WakeupAllowed" SG_ 3221225472 SVB_IVB_FS_Fond 0;
BA_ "NWM-WakeupAllowed" SG_ 3221225472 SVB_IVB_FS 0;
BA_ "NWM-WakeupAllowed" SG_ 3221225472 SVB_IVB_BFS_Fond 0;
BA_ "NWM-WakeupAllowed" SG_ 3221225472 SVB_IVB_BFS 0;
BA_ "NWM-WakeupAllowed" SG_ 3221225472 AWV_Halten 0;
BA_ "NWM-WakeupAllowed" SG_ 1728 NMH_GW_Start_1 0;
BA_ "GenSigStartValue" SG_ 1728 NMH_GW_Start_1 1;
BA_ "NWM-WakeupAllowed" SG_ 1728 NMH_GW_Start_2 0;
BA_ "NWM-WakeupAllowed" SG_ 1728 NMH_GW_Normal_Mode_1 0;
BA_ "NWM-WakeupAllowed" SG_ 1728 NMH_GW_Normal_Mode_2 0;
BA_ "NWM-WakeupAllowed" SG_ 1728 NMH_GW_Car_WakeUp 0;
BA_ "NWM-WakeupAllowed" SG_ 1728 NMH_GW_NM_aktiv_Klemme_15 0;
BA_ "NWM-WakeupAllowed" SG_ 1728 NMH_GW_NM_aktiv_Diagnose 0;
BA_ "NWM-WakeupAllowed" SG_ 1728 NMH_GW_NM_aktiv_Start 0;
BA_ "NWM-WakeupAllowed" SG_ 1728 NMH_GW_NM_aktiv_BDM 0;
BA_ "NWM-WakeupAllowed" SG_ 1728 NMH_GW_NM_aktiv_Warnblinken 0;
BA_ "NWM-WakeupAllowed" SG_ 1728 NMH_GW_NM_aktiv_ESP 0;
BA_ "NWM-WakeupAllowed" SG_ 1728 NMH_GW_NM_aktiv_EMP 0;
BA_ "NWM-WakeupAllowed" SG_ 1728 NMH_GW_Abschaltstufe_3 0;
BA_ "NWM-WakeupAllowed" SG_ 1728 NMH_GW_SG_Fehlerdauer 0;
BA_ "NWM-WakeupAllowed" SG_ 1728 NMH_GW_STH_Wakeup 0;
BA_ "NWM-WakeupAllowed" SG_ 1728 NMH_GW_NL_Diagnose 0;
BA_ "NWM-WakeupAllowed" SG_ 1728 NM_GW_Signalfehler 0;
BA_ "NWM-WakeupAllowed" SG_ 1728 NMH_GW_TimeOut_Fehler 0;
BA_ "NWM-WakeupAllowed" SG_ 1728 NMH_GW_CAN_Diag_deaktiv 0;
BA_ "NWM-WakeupAllowed" SG_ 1728 NMH_GW_KompSchutz 0;
BA_ "NWM-WakeupAllowed" SG_ 1728 NMH_GW_Mute_Mode 0;
BA_ "NWM-WakeupAllowed" SG_ 1728 NMH_GW_Transport_Mode 0;
BA_ "NWM-WakeupAllowed" SG_ 1728 NMH_GW_Abschaltstufe_aktiv 0;
BA_ "NWM-WakeupAllowed" SG_ 1728 NMH_GW_Eindraht_Fehler 0;
BA_ "NWM-WakeupAllowed" SG_ 1728 NMH_GW_ACAN 0;
BA_ "NWM-WakeupAllowed" SG_ 1728 NMH_GW_KombiCAN 0;
BA_ "NWM-WakeupAllowed" SG_ 1728 NMH_GW_KomfortCAN 0;
BA_ "NWM-WakeupAllowed" SG_ 1728 NMH_GW_Infotainment 0;
BA_ "NWM-WakeupAllowed" SG_ 1728 NMH_GW_Fahrwerk 0;
BA_ "NWM-WakeupAllowed" SG_ 1728 NMH_GW_WakeUp_CAN_Bus 0;
BA_ "GenSigSwitchedByIgnition" SG_ 1327 OBD_Fehler_Laengsbeschleunigung 1;
BA_ "NWM-WakeupAllowed" SG_ 1327 OBD_Fehler_Laengsbeschleunigung 0;
BA_ "GenSigSwitchedByIgnition" SG_ 1327 OBD_Fehler_Vordrucksensor 1;
BA_ "NWM-WakeupAllowed" SG_ 1327 OBD_Fehler_Vordrucksensor 0;
BA_ "GenSigSendType" SG_ 1381 HVLM_IstSpannung_HV 3;
BA_ "NWM-WakeupAllowed" SG_ 1381 HVLM_IstSpannung_HV 0;
BA_ "GenSigStartValue" SG_ 1381 HVLM_IstSpannung_HV 1022;
BA_ "Fehlerwert" SG_ 1381 HVLM_IstSpannung_HV 1023;
BA_ "NWM-WakeupAllowed" SG_ 1381 HVLM_HV_Abstellzeit 0;
BA_ "GenSigStartValue" SG_ 1381 HVLM_HV_Abstellzeit 254;
BA_ "Fehlerwert" SG_ 1381 HVLM_HV_Abstellzeit 255;
BA_ "GenSigSendType" SG_ 1381 HVLM_Zustand_LED 3;
BA_ "NWM-WakeupAllowed" SG_ 1381 HVLM_Zustand_LED 0;
BA_ "GenSigStartValue" SG_ 1381 HVLM_Zustand_LED 14;
BA_ "Fehlerwert" SG_ 1381 HVLM_Zustand_LED 15;
BA_ "GenSigSendType" SG_ 1381 HVLM_MaxLadezeitDCHV 3;
BA_ "NWM-WakeupAllowed" SG_ 1381 HVLM_MaxLadezeitDCHV 0;
BA_ "GenSigStartValue" SG_ 1381 HVLM_MaxLadezeitDCHV 254;
BA_ "Fehlerwert" SG_ 1381 HVLM_MaxLadezeitDCHV 255;
BA_ "GenSigSendType" SG_ 1381 HVLM_MaxStrom_Netz 3;
BA_ "NWM-WakeupAllowed" SG_ 1381 HVLM_MaxStrom_Netz 0;
BA_ "GenSigStartValue" SG_ 1381 HVLM_MaxStrom_Netz 126;
BA_ "Fehlerwert" SG_ 1381 HVLM_MaxStrom_Netz 127;
BA_ "GenSigSendType" SG_ 1381 HVLM_LG_Sollmodus 3;
BA_ "NWM-WakeupAllowed" SG_ 1381 HVLM_LG_Sollmodus 0;
BA_ "GenSigSendType" SG_ 1381 HVLM_FreigabeTankdeckel 3;
BA_ "NWM-WakeupAllowed" SG_ 1381 HVLM_FreigabeTankdeckel 0;
BA_ "GenSigStartValue" SG_ 1381 HVLM_FreigabeTankdeckel 2;
BA_ "Fehlerwert" SG_ 1381 HVLM_FreigabeTankdeckel 3;
BA_ "GenSigSendType" SG_ 1381 HVLM_Stecker_Verriegeln 3;
BA_ "NWM-WakeupAllowed" SG_ 1381 HVLM_Stecker_Verriegeln 0;
BA_ "GenSigStartValue" SG_ 1381 HVLM_Stecker_Verriegeln 2;
BA_ "GenSigSendType" SG_ 1381 HVLM_Start_Spannungsmessung_DCLS 3;
BA_ "NWM-WakeupAllowed" SG_ 1381 HVLM_Start_Spannungsmessung_DCLS 0;
BA_ "GenSigSendType" SG_ 1381 HVLM_Taster_Profil_Laden_Anf 3;
BA_ "NWM-WakeupAllowed" SG_ 1381 HVLM_Taster_Profil_Laden_Anf 0;
BA_ "GenSigStartValue" SG_ 1381 HVLM_Taster_Profil_Laden_Anf 2;
BA_ "Fehlerwert" SG_ 1381 HVLM_Taster_Profil_Laden_Anf 3;
BA_ "GenSigSendType" SG_ 1381 HVLM_Taster_Sofort_Laden_Anf 3;
BA_ "NWM-WakeupAllowed" SG_ 1381 HVLM_Taster_Sofort_Laden_Anf 0;
BA_ "GenSigStartValue" SG_ 1381 HVLM_Taster_Sofort_Laden_Anf 2;
BA_ "Fehlerwert" SG_ 1381 HVLM_Taster_Sofort_Laden_Anf 3;
BA_ "NWM-WakeupAllowed" SG_ 1381 HVLM_FreigabeKlimatisierung 0;
BA_ "GenSigStartValue" SG_ 1381 HVLM_FreigabeKlimatisierung 2;
BA_ "Fehlerwert" SG_ 1381 HVLM_FreigabeKlimatisierung 3;
BA_ "GenSigSendType" SG_ 1381 HVLM_Ladetexte 3;
BA_ "NWM-WakeupAllowed" SG_ 1381 HVLM_Ladetexte 0;
BA_ "NWM-WakeupAllowed" SG_ 1534 KBI_Set_Timer_MUX 0;
BA_ "GenSigSendType" SG_ 1534 KBI_Set_Timer_1_Jahr 7;
BA_ "NWM-WakeupAllowed" SG_ 1534 KBI_Set_Timer_1_Jahr 0;
BA_ "GenSigStartValue" SG_ 1534 KBI_Set_Timer_1_Jahr 126;
BA_ "GenSigSendType" SG_ 1534 KBI_Set_Timer_2_Jahr 7;
BA_ "NWM-WakeupAllowed" SG_ 1534 KBI_Set_Timer_2_Jahr 0;
BA_ "GenSigStartValue" SG_ 1534 KBI_Set_Timer_2_Jahr 126;
BA_ "GenSigSendType" SG_ 1534 KBI_Set_Timer_3_Jahr 7;
BA_ "NWM-WakeupAllowed" SG_ 1534 KBI_Set_Timer_3_Jahr 0;
BA_ "GenSigStartValue" SG_ 1534 KBI_Set_Timer_3_Jahr 126;
BA_ "GenSigSendType" SG_ 1534 KBI_Set_Timer_4_Jahr 7;
BA_ "NWM-WakeupAllowed" SG_ 1534 KBI_Set_Timer_4_Jahr 0;
BA_ "GenSigStartValue" SG_ 1534 KBI_Set_Timer_4_Jahr 126;
BA_ "GenSigSendType" SG_ 1534 KBI_Set_Timer_1_Minute 7;
BA_ "NWM-WakeupAllowed" SG_ 1534 KBI_Set_Timer_1_Minute 0;
BA_ "GenSigStartValue" SG_ 1534 KBI_Set_Timer_1_Minute 62;
BA_ "Fehlerwert" SG_ 1534 KBI_Set_Timer_1_Minute 63;
BA_ "GenSigSendType" SG_ 1534 KBI_Set_Timer_2_Minute 7;
BA_ "NWM-WakeupAllowed" SG_ 1534 KBI_Set_Timer_2_Minute 0;
BA_ "GenSigStartValue" SG_ 1534 KBI_Set_Timer_2_Minute 62;
BA_ "Fehlerwert" SG_ 1534 KBI_Set_Timer_2_Minute 63;
BA_ "GenSigSendType" SG_ 1534 KBI_Set_Timer_3_Minute 7;
BA_ "NWM-WakeupAllowed" SG_ 1534 KBI_Set_Timer_3_Minute 0;
BA_ "GenSigSendType" SG_ 1534 KBI_Set_Timer_4_Minute 7;
BA_ "NWM-WakeupAllowed" SG_ 1534 KBI_Set_Timer_4_Minute 0;
BA_ "GenSigSendType" SG_ 1534 KBI_Set_Timer_1_Monat 7;
BA_ "NWM-WakeupAllowed" SG_ 1534 KBI_Set_Timer_1_Monat 0;
BA_ "Fehlerwert" SG_ 1534 KBI_Set_Timer_1_Monat 15;
BA_ "GenSigSendType" SG_ 1534 KBI_Set_Timer_2_Monat 7;
BA_ "NWM-WakeupAllowed" SG_ 1534 KBI_Set_Timer_2_Monat 0;
BA_ "Fehlerwert" SG_ 1534 KBI_Set_Timer_2_Monat 15;
BA_ "GenSigSendType" SG_ 1534 KBI_Set_Timer_3_Monat 7;
BA_ "NWM-WakeupAllowed" SG_ 1534 KBI_Set_Timer_3_Monat 0;
BA_ "Fehlerwert" SG_ 1534 KBI_Set_Timer_3_Monat 15;
BA_ "GenSigSendType" SG_ 1534 KBI_Set_Timer_4_Monat 7;
BA_ "NWM-WakeupAllowed" SG_ 1534 KBI_Set_Timer_4_Monat 0;
BA_ "Fehlerwert" SG_ 1534 KBI_Set_Timer_4_Monat 15;
BA_ "GenSigSendType" SG_ 1534 KBI_Set_Timer_1_Stunde 7;
BA_ "NWM-WakeupAllowed" SG_ 1534 KBI_Set_Timer_1_Stunde 0;
BA_ "GenSigStartValue" SG_ 1534 KBI_Set_Timer_1_Stunde 30;
BA_ "Fehlerwert" SG_ 1534 KBI_Set_Timer_1_Stunde 31;
BA_ "GenSigSendType" SG_ 1534 KBI_Set_Timer_2_Stunde 7;
BA_ "NWM-WakeupAllowed" SG_ 1534 KBI_Set_Timer_2_Stunde 0;
BA_ "GenSigStartValue" SG_ 1534 KBI_Set_Timer_2_Stunde 30;
BA_ "Fehlerwert" SG_ 1534 KBI_Set_Timer_2_Stunde 31;
BA_ "GenSigSendType" SG_ 1534 KBI_Set_Timer_3_Stunde 7;
BA_ "NWM-WakeupAllowed" SG_ 1534 KBI_Set_Timer_3_Stunde 0;
BA_ "GenSigStartValue" SG_ 1534 KBI_Set_Timer_3_Stunde 30;
BA_ "Fehlerwert" SG_ 1534 KBI_Set_Timer_3_Stunde 31;
BA_ "GenSigSendType" SG_ 1534 KBI_Set_Timer_4_Stunde 7;
BA_ "NWM-WakeupAllowed" SG_ 1534 KBI_Set_Timer_4_Stunde 0;
BA_ "GenSigStartValue" SG_ 1534 KBI_Set_Timer_4_Stunde 30;
BA_ "Fehlerwert" SG_ 1534 KBI_Set_Timer_4_Stunde 31;
BA_ "GenSigSendType" SG_ 1534 KBI_Set_Timer_1_Tag 7;
BA_ "NWM-WakeupAllowed" SG_ 1534 KBI_Set_Timer_1_Tag 0;
BA_ "GenSigSendType" SG_ 1534 KBI_Set_Timer_2_Tag 7;
BA_ "NWM-WakeupAllowed" SG_ 1534 KBI_Set_Timer_2_Tag 0;
BA_ "GenSigSendType" SG_ 1534 KBI_Set_Timer_3_Tag 7;
BA_ "NWM-WakeupAllowed" SG_ 1534 KBI_Set_Timer_3_Tag 0;
BA_ "GenSigSendType" SG_ 1534 KBI_Set_Timer_4_Tag 7;
BA_ "NWM-WakeupAllowed" SG_ 1534 KBI_Set_Timer_4_Tag 0;
BA_ "GenSigSendType" SG_ 1534 KBI_Set_Timer_1_Laden 7;
BA_ "NWM-WakeupAllowed" SG_ 1534 KBI_Set_Timer_1_Laden 0;
BA_ "GenSigSendType" SG_ 1534 KBI_Set_Timer_2_Laden 7;
BA_ "NWM-WakeupAllowed" SG_ 1534 KBI_Set_Timer_2_Laden 0;
BA_ "GenSigSendType" SG_ 1534 KBI_Set_Timer_3_Laden 7;
BA_ "NWM-WakeupAllowed" SG_ 1534 KBI_Set_Timer_3_Laden 0;
BA_ "GenSigSendType" SG_ 1534 KBI_Set_Timer_4_Laden 7;
BA_ "NWM-WakeupAllowed" SG_ 1534 KBI_Set_Timer_4_Laden 0;
BA_ "GenSigSendType" SG_ 1534 KBI_Set_Timer_1_Vorklima 7;
BA_ "NWM-WakeupAllowed" SG_ 1534 KBI_Set_Timer_1_Vorklima 0;
BA_ "GenSigSendType" SG_ 1534 KBI_Set_Timer_2_Vorklima 7;
BA_ "NWM-WakeupAllowed" SG_ 1534 KBI_Set_Timer_2_Vorklima 0;
BA_ "GenSigSendType" SG_ 1534 KBI_Set_Timer_3_Vorklima 7;
BA_ "NWM-WakeupAllowed" SG_ 1534 KBI_Set_Timer_3_Vorklima 0;
BA_ "GenSigSendType" SG_ 1534 KBI_Set_Timer_4_Vorklima 7;
BA_ "NWM-WakeupAllowed" SG_ 1534 KBI_Set_Timer_4_Vorklima 0;
BA_ "GenSigSendType" SG_ 1534 KBI_Set_Timer_1_Zyklus_Mo 7;
BA_ "NWM-WakeupAllowed" SG_ 1534 KBI_Set_Timer_1_Zyklus_Mo 0;
BA_ "GenSigSendType" SG_ 1534 KBI_Set_Timer_2_Zyklus_Mo 7;
BA_ "NWM-WakeupAllowed" SG_ 1534 KBI_Set_Timer_2_Zyklus_Mo 0;
BA_ "GenSigSendType" SG_ 1534 KBI_Set_Timer_3_Zyklus_Mo 7;
BA_ "NWM-WakeupAllowed" SG_ 1534 KBI_Set_Timer_3_Zyklus_Mo 0;
BA_ "GenSigSendType" SG_ 1534 KBI_Set_Timer_4_Zyklus_Mo 7;
BA_ "NWM-WakeupAllowed" SG_ 1534 KBI_Set_Timer_4_Zyklus_Mo 0;
BA_ "GenSigSendType" SG_ 1534 KBI_Set_Timer_1_Zyklus_Di 7;
BA_ "NWM-WakeupAllowed" SG_ 1534 KBI_Set_Timer_1_Zyklus_Di 0;
BA_ "GenSigSendType" SG_ 1534 KBI_Set_Timer_2_Zyklus_Di 7;
BA_ "NWM-WakeupAllowed" SG_ 1534 KBI_Set_Timer_2_Zyklus_Di 0;
BA_ "GenSigSendType" SG_ 1534 KBI_Set_Timer_3_Zyklus_Di 7;
BA_ "NWM-WakeupAllowed" SG_ 1534 KBI_Set_Timer_3_Zyklus_Di 0;
BA_ "GenSigSendType" SG_ 1534 KBI_Set_Timer_4_Zyklus_Di 7;
BA_ "NWM-WakeupAllowed" SG_ 1534 KBI_Set_Timer_4_Zyklus_Di 0;
BA_ "GenSigSendType" SG_ 1534 KBI_Set_Timer_1_Zyklus_Mi 7;
BA_ "NWM-WakeupAllowed" SG_ 1534 KBI_Set_Timer_1_Zyklus_Mi 0;
BA_ "GenSigSendType" SG_ 1534 KBI_Set_Timer_2_Zyklus_Mi 7;
BA_ "NWM-WakeupAllowed" SG_ 1534 KBI_Set_Timer_2_Zyklus_Mi 0;
BA_ "GenSigSendType" SG_ 1534 KBI_Set_Timer_3_Zyklus_Mi 7;
BA_ "NWM-WakeupAllowed" SG_ 1534 KBI_Set_Timer_3_Zyklus_Mi 0;
BA_ "GenSigSendType" SG_ 1534 KBI_Set_Timer_4_Zyklus_Mi 7;
BA_ "NWM-WakeupAllowed" SG_ 1534 KBI_Set_Timer_4_Zyklus_Mi 0;
BA_ "GenSigSendType" SG_ 1534 KBI_Set_Timer_1_Zyklus_Do 7;
BA_ "NWM-WakeupAllowed" SG_ 1534 KBI_Set_Timer_1_Zyklus_Do 0;
BA_ "GenSigSendType" SG_ 1534 KBI_Set_Timer_2_Zyklus_Do 7;
BA_ "NWM-WakeupAllowed" SG_ 1534 KBI_Set_Timer_2_Zyklus_Do 0;
BA_ "GenSigSendType" SG_ 1534 KBI_Set_Timer_3_Zyklus_Do 7;
BA_ "NWM-WakeupAllowed" SG_ 1534 KBI_Set_Timer_3_Zyklus_Do 0;
BA_ "GenSigSendType" SG_ 1534 KBI_Set_Timer_4_Zyklus_Do 7;
BA_ "NWM-WakeupAllowed" SG_ 1534 KBI_Set_Timer_4_Zyklus_Do 0;
BA_ "GenSigSendType" SG_ 1534 KBI_Set_Timer_1_Zyklus_Fr 7;
BA_ "NWM-WakeupAllowed" SG_ 1534 KBI_Set_Timer_1_Zyklus_Fr 0;
BA_ "GenSigSendType" SG_ 1534 KBI_Set_Timer_2_Zyklus_Fr 7;
BA_ "NWM-WakeupAllowed" SG_ 1534 KBI_Set_Timer_2_Zyklus_Fr 0;
BA_ "GenSigSendType" SG_ 1534 KBI_Set_Timer_3_Zyklus_Fr 7;
BA_ "NWM-WakeupAllowed" SG_ 1534 KBI_Set_Timer_3_Zyklus_Fr 0;
BA_ "GenSigSendType" SG_ 1534 KBI_Set_Timer_4_Zyklus_Fr 7;
BA_ "NWM-WakeupAllowed" SG_ 1534 KBI_Set_Timer_4_Zyklus_Fr 0;
BA_ "GenSigSendType" SG_ 1534 KBI_Set_Timer_1_Zyklus_Sa 7;
BA_ "NWM-WakeupAllowed" SG_ 1534 KBI_Set_Timer_1_Zyklus_Sa 0;
BA_ "GenSigSendType" SG_ 1534 KBI_Set_Timer_2_Zyklus_Sa 7;
BA_ "NWM-WakeupAllowed" SG_ 1534 KBI_Set_Timer_2_Zyklus_Sa 0;
BA_ "GenSigSendType" SG_ 1534 KBI_Set_Timer_3_Zyklus_Sa 7;
BA_ "NWM-WakeupAllowed" SG_ 1534 KBI_Set_Timer_3_Zyklus_Sa 0;
BA_ "GenSigSendType" SG_ 1534 KBI_Set_Timer_4_Zyklus_Sa 7;
BA_ "NWM-WakeupAllowed" SG_ 1534 KBI_Set_Timer_4_Zyklus_Sa 0;
BA_ "GenSigSendType" SG_ 1534 KBI_Set_Timer_1_Zyklus_So 7;
BA_ "NWM-WakeupAllowed" SG_ 1534 KBI_Set_Timer_1_Zyklus_So 0;
BA_ "GenSigSendType" SG_ 1534 KBI_Set_Timer_2_Zyklus_So 7;
BA_ "NWM-WakeupAllowed" SG_ 1534 KBI_Set_Timer_2_Zyklus_So 0;
BA_ "GenSigSendType" SG_ 1534 KBI_Set_Timer_3_Zyklus_So 7;
BA_ "NWM-WakeupAllowed" SG_ 1534 KBI_Set_Timer_3_Zyklus_So 0;
BA_ "GenSigSendType" SG_ 1534 KBI_Set_Timer_4_Zyklus_So 7;
BA_ "NWM-WakeupAllowed" SG_ 1534 KBI_Set_Timer_4_Zyklus_So 0;
BA_ "GenSigSendType" SG_ 1534 KBI_Set_Timer_1_Zyklus_WH 7;
BA_ "NWM-WakeupAllowed" SG_ 1534 KBI_Set_Timer_1_Zyklus_WH 0;
BA_ "GenSigSendType" SG_ 1534 KBI_Set_Timer_2_Zyklus_WH 7;
BA_ "NWM-WakeupAllowed" SG_ 1534 KBI_Set_Timer_2_Zyklus_WH 0;
BA_ "GenSigSendType" SG_ 1534 KBI_Set_Timer_3_Zyklus_WH 7;
BA_ "NWM-WakeupAllowed" SG_ 1534 KBI_Set_Timer_3_Zyklus_WH 0;
BA_ "GenSigSendType" SG_ 1534 KBI_Set_Timer_4_Zyklus_WH 7;
BA_ "NWM-WakeupAllowed" SG_ 1534 KBI_Set_Timer_4_Zyklus_WH 0;
BA_ "NWM-WakeupAllowed" SG_ 1534 KBI_MOD_Privatsphaere 0;
BA_ "NWM-WakeupAllowed" SG_ 1534 KBI_STH_Status 0;
BA_ "NWM-WakeupAllowed" SG_ 1631 MO_Energieinhalt_BMS 0;
BA_ "GenSigStartValue" SG_ 1631 MO_Energieinhalt_BMS 4094;
BA_ "Fehlerwert" SG_ 1631 MO_Energieinhalt_BMS 4095;
BA_ "GenSigSendType" SG_ 1398 MOD_Set_Timer_5_Jahr 7;
BA_ "NWM-WakeupAllowed" SG_ 1398 MOD_Set_Timer_5_Jahr 0;
BA_ "GenSigStartValue" SG_ 1398 MOD_Set_Timer_5_Jahr 126;
BA_ "GenSigSendType" SG_ 1398 MOD_Set_Timer_6_Jahr 7;
BA_ "NWM-WakeupAllowed" SG_ 1398 MOD_Set_Timer_6_Jahr 0;
BA_ "GenSigStartValue" SG_ 1398 MOD_Set_Timer_6_Jahr 126;
BA_ "GenSigSendType" SG_ 1398 MOD_Set_Timer_5_Minute 7;
BA_ "NWM-WakeupAllowed" SG_ 1398 MOD_Set_Timer_5_Minute 0;
BA_ "GenSigStartValue" SG_ 1398 MOD_Set_Timer_5_Minute 62;
BA_ "GenSigSendType" SG_ 1398 MOD_Set_Timer_6_Minute 7;
BA_ "NWM-WakeupAllowed" SG_ 1398 MOD_Set_Timer_6_Minute 0;
BA_ "GenSigStartValue" SG_ 1398 MOD_Set_Timer_6_Minute 62;
BA_ "GenSigSendType" SG_ 1398 MOD_Set_Timer_5_Monat 7;
BA_ "NWM-WakeupAllowed" SG_ 1398 MOD_Set_Timer_5_Monat 0;
BA_ "GenSigSendType" SG_ 1398 MOD_Set_Timer_6_Monat 7;
BA_ "NWM-WakeupAllowed" SG_ 1398 MOD_Set_Timer_6_Monat 0;
BA_ "GenSigSendType" SG_ 1398 MOD_Set_Timer_5_Stunde 7;
BA_ "NWM-WakeupAllowed" SG_ 1398 MOD_Set_Timer_5_Stunde 0;
BA_ "GenSigStartValue" SG_ 1398 MOD_Set_Timer_5_Stunde 30;
BA_ "GenSigSendType" SG_ 1398 MOD_Set_Timer_6_Stunde 7;
BA_ "NWM-WakeupAllowed" SG_ 1398 MOD_Set_Timer_6_Stunde 0;
BA_ "GenSigStartValue" SG_ 1398 MOD_Set_Timer_6_Stunde 30;
BA_ "GenSigSendType" SG_ 1398 MOD_Set_Timer_5_Tag 7;
BA_ "NWM-WakeupAllowed" SG_ 1398 MOD_Set_Timer_5_Tag 0;
BA_ "GenSigSendType" SG_ 1398 MOD_Set_Timer_6_Tag 7;
BA_ "NWM-WakeupAllowed" SG_ 1398 MOD_Set_Timer_6_Tag 0;
BA_ "GenSigSendType" SG_ 1398 MOD_Set_Timer_5_Vorklima 7;
BA_ "NWM-WakeupAllowed" SG_ 1398 MOD_Set_Timer_5_Vorklima 0;
BA_ "GenSigSendType" SG_ 1398 MOD_Set_Timer_6_Vorklima 7;
BA_ "NWM-WakeupAllowed" SG_ 1398 MOD_Set_Timer_6_Vorklima 0;
BA_ "NWM-WakeupAllowed" SG_ 1398 MOD_Set_Timerladen 0;
BA_ "NWM-WakeupAllowed" SG_ 1398 MOD_Set_Sofortladen 0;
BA_ "GenSigSendType" SG_ 1398 MOD_Set_Timer_4_Jahr 7;
BA_ "NWM-WakeupAllowed" SG_ 1398 MOD_Set_Timer_4_Jahr 0;
BA_ "GenSigStartValue" SG_ 1398 MOD_Set_Timer_4_Jahr 126;
BA_ "GenSigSendType" SG_ 1398 MOD_Set_Timer_4_Minute 7;
BA_ "NWM-WakeupAllowed" SG_ 1398 MOD_Set_Timer_4_Minute 0;
BA_ "GenSigStartValue" SG_ 1398 MOD_Set_Timer_4_Minute 62;
BA_ "Fehlerwert" SG_ 1398 MOD_Set_Timer_4_Minute 63;
BA_ "GenSigSendType" SG_ 1398 MOD_Set_Timer_4_Monat 7;
BA_ "NWM-WakeupAllowed" SG_ 1398 MOD_Set_Timer_4_Monat 0;
BA_ "Fehlerwert" SG_ 1398 MOD_Set_Timer_4_Monat 15;
BA_ "GenSigSendType" SG_ 1398 MOD_Set_Timer_4_Stunde 7;
BA_ "NWM-WakeupAllowed" SG_ 1398 MOD_Set_Timer_4_Stunde 0;
BA_ "GenSigStartValue" SG_ 1398 MOD_Set_Timer_4_Stunde 30;
BA_ "Fehlerwert" SG_ 1398 MOD_Set_Timer_4_Stunde 31;
BA_ "GenSigSendType" SG_ 1398 MOD_Set_Timer_4_Tag 7;
BA_ "NWM-WakeupAllowed" SG_ 1398 MOD_Set_Timer_4_Tag 0;
BA_ "GenSigSendType" SG_ 1398 MOD_Set_Timer_4_Laden 7;
BA_ "NWM-WakeupAllowed" SG_ 1398 MOD_Set_Timer_4_Laden 0;
BA_ "GenSigSendType" SG_ 1398 MOD_Set_Timer_4_Vorklima 7;
BA_ "NWM-WakeupAllowed" SG_ 1398 MOD_Set_Timer_4_Vorklima 0;
BA_ "GenSigSendType" SG_ 1398 MOD_Set_Timer_4_Zyklus_Mo 7;
BA_ "NWM-WakeupAllowed" SG_ 1398 MOD_Set_Timer_4_Zyklus_Mo 0;
BA_ "GenSigSendType" SG_ 1398 MOD_Set_Timer_4_Zyklus_Di 7;
BA_ "NWM-WakeupAllowed" SG_ 1398 MOD_Set_Timer_4_Zyklus_Di 0;
BA_ "GenSigSendType" SG_ 1398 MOD_Set_Timer_4_Zyklus_Mi 7;
BA_ "NWM-WakeupAllowed" SG_ 1398 MOD_Set_Timer_4_Zyklus_Mi 0;
BA_ "GenSigSendType" SG_ 1398 MOD_Set_Timer_4_Zyklus_Do 7;
BA_ "NWM-WakeupAllowed" SG_ 1398 MOD_Set_Timer_4_Zyklus_Do 0;
BA_ "GenSigSendType" SG_ 1398 MOD_Set_Timer_4_Zyklus_Fr 7;
BA_ "NWM-WakeupAllowed" SG_ 1398 MOD_Set_Timer_4_Zyklus_Fr 0;
BA_ "GenSigSendType" SG_ 1398 MOD_Set_Timer_4_Zyklus_Sa 7;
BA_ "NWM-WakeupAllowed" SG_ 1398 MOD_Set_Timer_4_Zyklus_Sa 0;
BA_ "GenSigSendType" SG_ 1398 MOD_Set_Timer_4_Zyklus_So 7;
BA_ "NWM-WakeupAllowed" SG_ 1398 MOD_Set_Timer_4_Zyklus_So 0;
BA_ "GenSigSendType" SG_ 1398 MOD_Set_Timer_4_Zyklus_WH 7;
BA_ "NWM-WakeupAllowed" SG_ 1398 MOD_Set_Timer_4_Zyklus_WH 0;
BA_ "GenSigSendType" SG_ 1398 MOD_Set_Timer_1_Jahr 7;
BA_ "NWM-WakeupAllowed" SG_ 1398 MOD_Set_Timer_1_Jahr 0;
BA_ "GenSigStartValue" SG_ 1398 MOD_Set_Timer_1_Jahr 126;
BA_ "GenSigSendType" SG_ 1398 MOD_Set_Timer_2_Jahr 7;
BA_ "NWM-WakeupAllowed" SG_ 1398 MOD_Set_Timer_2_Jahr 0;
BA_ "GenSigStartValue" SG_ 1398 MOD_Set_Timer_2_Jahr 126;
BA_ "GenSigSendType" SG_ 1398 MOD_Set_Timer_3_Jahr 7;
BA_ "NWM-WakeupAllowed" SG_ 1398 MOD_Set_Timer_3_Jahr 0;
BA_ "GenSigStartValue" SG_ 1398 MOD_Set_Timer_3_Jahr 126;
BA_ "GenSigSendType" SG_ 1398 MOD_Set_Timer_1_Minute 7;
BA_ "NWM-WakeupAllowed" SG_ 1398 MOD_Set_Timer_1_Minute 0;
BA_ "GenSigStartValue" SG_ 1398 MOD_Set_Timer_1_Minute 62;
BA_ "Fehlerwert" SG_ 1398 MOD_Set_Timer_1_Minute 63;
BA_ "GenSigSendType" SG_ 1398 MOD_Set_Timer_2_Minute 7;
BA_ "NWM-WakeupAllowed" SG_ 1398 MOD_Set_Timer_2_Minute 0;
BA_ "GenSigStartValue" SG_ 1398 MOD_Set_Timer_2_Minute 62;
BA_ "Fehlerwert" SG_ 1398 MOD_Set_Timer_2_Minute 63;
BA_ "GenSigSendType" SG_ 1398 MOD_Set_Timer_3_Minute 7;
BA_ "NWM-WakeupAllowed" SG_ 1398 MOD_Set_Timer_3_Minute 0;
BA_ "GenSigStartValue" SG_ 1398 MOD_Set_Timer_3_Minute 62;
BA_ "Fehlerwert" SG_ 1398 MOD_Set_Timer_3_Minute 63;
BA_ "GenSigSendType" SG_ 1398 MOD_Set_Timer_1_Monat 7;
BA_ "NWM-WakeupAllowed" SG_ 1398 MOD_Set_Timer_1_Monat 0;
BA_ "Fehlerwert" SG_ 1398 MOD_Set_Timer_1_Monat 15;
BA_ "GenSigSendType" SG_ 1398 MOD_Set_Timer_2_Monat 7;
BA_ "NWM-WakeupAllowed" SG_ 1398 MOD_Set_Timer_2_Monat 0;
BA_ "Fehlerwert" SG_ 1398 MOD_Set_Timer_2_Monat 15;
BA_ "GenSigSendType" SG_ 1398 MOD_Set_Timer_3_Monat 7;
BA_ "NWM-WakeupAllowed" SG_ 1398 MOD_Set_Timer_3_Monat 0;
BA_ "Fehlerwert" SG_ 1398 MOD_Set_Timer_3_Monat 15;
BA_ "GenSigSendType" SG_ 1398 MOD_Set_Timer_1_Stunde 7;
BA_ "NWM-WakeupAllowed" SG_ 1398 MOD_Set_Timer_1_Stunde 0;
BA_ "GenSigStartValue" SG_ 1398 MOD_Set_Timer_1_Stunde 30;
BA_ "Fehlerwert" SG_ 1398 MOD_Set_Timer_1_Stunde 31;
BA_ "GenSigSendType" SG_ 1398 MOD_Set_Timer_2_Stunde 7;
BA_ "NWM-WakeupAllowed" SG_ 1398 MOD_Set_Timer_2_Stunde 0;
BA_ "GenSigStartValue" SG_ 1398 MOD_Set_Timer_2_Stunde 30;
BA_ "Fehlerwert" SG_ 1398 MOD_Set_Timer_2_Stunde 31;
BA_ "GenSigSendType" SG_ 1398 MOD_Set_Timer_3_Stunde 7;
BA_ "NWM-WakeupAllowed" SG_ 1398 MOD_Set_Timer_3_Stunde 0;
BA_ "GenSigStartValue" SG_ 1398 MOD_Set_Timer_3_Stunde 30;
BA_ "Fehlerwert" SG_ 1398 MOD_Set_Timer_3_Stunde 31;
BA_ "GenSigSendType" SG_ 1398 MOD_Set_Timer_1_Tag 7;
BA_ "NWM-WakeupAllowed" SG_ 1398 MOD_Set_Timer_1_Tag 0;
BA_ "GenSigSendType" SG_ 1398 MOD_Set_Timer_2_Tag 7;
BA_ "NWM-WakeupAllowed" SG_ 1398 MOD_Set_Timer_2_Tag 0;
BA_ "GenSigSendType" SG_ 1398 MOD_Set_Timer_3_Tag 7;
BA_ "NWM-WakeupAllowed" SG_ 1398 MOD_Set_Timer_3_Tag 0;
BA_ "GenSigSendType" SG_ 1398 MOD_Set_Timer_1_Laden 7;
BA_ "NWM-WakeupAllowed" SG_ 1398 MOD_Set_Timer_1_Laden 0;
BA_ "GenSigSendType" SG_ 1398 MOD_Set_Timer_2_Laden 7;
BA_ "NWM-WakeupAllowed" SG_ 1398 MOD_Set_Timer_2_Laden 0;
BA_ "GenSigSendType" SG_ 1398 MOD_Set_Timer_3_Laden 7;
BA_ "NWM-WakeupAllowed" SG_ 1398 MOD_Set_Timer_3_Laden 0;
BA_ "GenSigSendType" SG_ 1398 MOD_Set_Timer_1_Vorklima 7;
BA_ "NWM-WakeupAllowed" SG_ 1398 MOD_Set_Timer_1_Vorklima 0;
BA_ "GenSigSendType" SG_ 1398 MOD_Set_Timer_2_Vorklima 7;
BA_ "NWM-WakeupAllowed" SG_ 1398 MOD_Set_Timer_2_Vorklima 0;
BA_ "GenSigSendType" SG_ 1398 MOD_Set_Timer_3_Vorklima 7;
BA_ "NWM-WakeupAllowed" SG_ 1398 MOD_Set_Timer_3_Vorklima 0;
BA_ "GenSigSendType" SG_ 1398 MOD_Set_Timer_1_Zyklus_Mo 7;
BA_ "NWM-WakeupAllowed" SG_ 1398 MOD_Set_Timer_1_Zyklus_Mo 0;
BA_ "GenSigSendType" SG_ 1398 MOD_Set_Timer_2_Zyklus_Mo 7;
BA_ "NWM-WakeupAllowed" SG_ 1398 MOD_Set_Timer_2_Zyklus_Mo 0;
BA_ "GenSigSendType" SG_ 1398 MOD_Set_Timer_3_Zyklus_Mo 7;
BA_ "NWM-WakeupAllowed" SG_ 1398 MOD_Set_Timer_3_Zyklus_Mo 0;
BA_ "GenSigSendType" SG_ 1398 MOD_Set_Timer_1_Zyklus_Di 7;
BA_ "NWM-WakeupAllowed" SG_ 1398 MOD_Set_Timer_1_Zyklus_Di 0;
BA_ "GenSigSendType" SG_ 1398 MOD_Set_Timer_2_Zyklus_Di 7;
BA_ "NWM-WakeupAllowed" SG_ 1398 MOD_Set_Timer_2_Zyklus_Di 0;
BA_ "GenSigSendType" SG_ 1398 MOD_Set_Timer_3_Zyklus_Di 7;
BA_ "NWM-WakeupAllowed" SG_ 1398 MOD_Set_Timer_3_Zyklus_Di 0;
BA_ "GenSigSendType" SG_ 1398 MOD_Set_Timer_1_Zyklus_Mi 7;
BA_ "NWM-WakeupAllowed" SG_ 1398 MOD_Set_Timer_1_Zyklus_Mi 0;
BA_ "GenSigSendType" SG_ 1398 MOD_Set_Timer_2_Zyklus_Mi 7;
BA_ "NWM-WakeupAllowed" SG_ 1398 MOD_Set_Timer_2_Zyklus_Mi 0;
BA_ "GenSigSendType" SG_ 1398 MOD_Set_Timer_3_Zyklus_Mi 7;
BA_ "NWM-WakeupAllowed" SG_ 1398 MOD_Set_Timer_3_Zyklus_Mi 0;
BA_ "GenSigSendType" SG_ 1398 MOD_Set_Timer_1_Zyklus_Do 7;
BA_ "NWM-WakeupAllowed" SG_ 1398 MOD_Set_Timer_1_Zyklus_Do 0;
BA_ "GenSigSendType" SG_ 1398 MOD_Set_Timer_2_Zyklus_Do 7;
BA_ "NWM-WakeupAllowed" SG_ 1398 MOD_Set_Timer_2_Zyklus_Do 0;
BA_ "GenSigSendType" SG_ 1398 MOD_Set_Timer_3_Zyklus_Do 7;
BA_ "NWM-WakeupAllowed" SG_ 1398 MOD_Set_Timer_3_Zyklus_Do 0;
BA_ "GenSigSendType" SG_ 1398 MOD_Set_Timer_1_Zyklus_Fr 7;
BA_ "NWM-WakeupAllowed" SG_ 1398 MOD_Set_Timer_1_Zyklus_Fr 0;
BA_ "GenSigSendType" SG_ 1398 MOD_Set_Timer_2_Zyklus_Fr 7;
BA_ "NWM-WakeupAllowed" SG_ 1398 MOD_Set_Timer_2_Zyklus_Fr 0;
BA_ "GenSigSendType" SG_ 1398 MOD_Set_Timer_3_Zyklus_Fr 7;
BA_ "NWM-WakeupAllowed" SG_ 1398 MOD_Set_Timer_3_Zyklus_Fr 0;
BA_ "GenSigSendType" SG_ 1398 MOD_Set_Timer_1_Zyklus_Sa 7;
BA_ "NWM-WakeupAllowed" SG_ 1398 MOD_Set_Timer_1_Zyklus_Sa 0;
BA_ "GenSigSendType" SG_ 1398 MOD_Set_Timer_2_Zyklus_Sa 7;
BA_ "NWM-WakeupAllowed" SG_ 1398 MOD_Set_Timer_2_Zyklus_Sa 0;
BA_ "GenSigSendType" SG_ 1398 MOD_Set_Timer_3_Zyklus_Sa 7;
BA_ "NWM-WakeupAllowed" SG_ 1398 MOD_Set_Timer_3_Zyklus_Sa 0;
BA_ "GenSigSendType" SG_ 1398 MOD_Set_Timer_1_Zyklus_So 7;
BA_ "NWM-WakeupAllowed" SG_ 1398 MOD_Set_Timer_1_Zyklus_So 0;
BA_ "GenSigSendType" SG_ 1398 MOD_Set_Timer_2_Zyklus_So 7;
BA_ "NWM-WakeupAllowed" SG_ 1398 MOD_Set_Timer_2_Zyklus_So 0;
BA_ "GenSigSendType" SG_ 1398 MOD_Set_Timer_3_Zyklus_So 7;
BA_ "NWM-WakeupAllowed" SG_ 1398 MOD_Set_Timer_3_Zyklus_So 0;
BA_ "GenSigSendType" SG_ 1398 MOD_Set_Timer_1_Zyklus_WH 7;
BA_ "NWM-WakeupAllowed" SG_ 1398 MOD_Set_Timer_1_Zyklus_WH 0;
BA_ "GenSigSendType" SG_ 1398 MOD_Set_Timer_2_Zyklus_WH 7;
BA_ "NWM-WakeupAllowed" SG_ 1398 MOD_Set_Timer_2_Zyklus_WH 0;
BA_ "NWM-WakeupAllowed" SG_ 1398 MOD_Set_Timer_MUX 0;
BA_ "GenSigSendType" SG_ 1398 MOD_Set_Timer_3_Zyklus_WH 7;
BA_ "NWM-WakeupAllowed" SG_ 1398 MOD_Set_Timer_3_Zyklus_WH 0;
BA_ "NWM-WakeupAllowed" SG_ 1398 MOD_Set_Nachtstrom_X_Std_Anf 0;
BA_ "GenSigStartValue" SG_ 1398 MOD_Set_Nachtstrom_X_Std_Anf 62;
BA_ "NWM-WakeupAllowed" SG_ 1398 MOD_Set_Nachtstrom_Prof 0;
BA_ "NWM-WakeupAllowed" SG_ 1398 MOD_Set_Nachtstrom_X_Std_End 0;
BA_ "GenSigStartValue" SG_ 1398 MOD_Set_Nachtstrom_X_Std_End 62;
BA_ "NWM-WakeupAllowed" SG_ 1398 MOD_Set_Nachtstrom_Akt_Prof 0;
BA_ "NWM-WakeupAllowed" SG_ 1398 MOD_Set_Abbruch_Klima 0;
BA_ "NWM-WakeupAllowed" SG_ 1398 MOD_Set_Sofortstart_Klima 0;
BA_ "NWM-WakeupAllowed" SG_ 1398 MOD_Anf_Spiegel_anklappen 0;
BA_ "NWM-WakeupAllowed" SG_ 1398 MOD_Anf_ZV 0;
BA_ "GenSigSendType" SG_ 1397 HVLM_Status_naechster_Ladetimer 7;
BA_ "NWM-WakeupAllowed" SG_ 1397 HVLM_Status_naechster_Ladetimer 0;
BA_ "GenSigSendType" SG_ 1397 HVLM_Status_naechster_Klimatimer 7;
BA_ "NWM-WakeupAllowed" SG_ 1397 HVLM_Status_naechster_Klimatimer 0;
BA_ "GenSigSendType" SG_ 1397 HVLM_Status_Timer_7_Laden 7;
BA_ "NWM-WakeupAllowed" SG_ 1397 HVLM_Status_Timer_7_Laden 0;
BA_ "NWM-WakeupAllowed" SG_ 1397 HVLM_Ladetexte 0;
BA_ "GenSigSendType" SG_ 1397 HVLM_Status_Timer_4_Jahr 7;
BA_ "NWM-WakeupAllowed" SG_ 1397 HVLM_Status_Timer_4_Jahr 0;
BA_ "GenSigStartValue" SG_ 1397 HVLM_Status_Timer_4_Jahr 126;
BA_ "GenSigSendType" SG_ 1397 HVLM_Status_Timer_4_Minute 7;
BA_ "NWM-WakeupAllowed" SG_ 1397 HVLM_Status_Timer_4_Minute 0;
BA_ "GenSigStartValue" SG_ 1397 HVLM_Status_Timer_4_Minute 62;
BA_ "Fehlerwert" SG_ 1397 HVLM_Status_Timer_4_Minute 63;
BA_ "GenSigSendType" SG_ 1397 HVLM_Status_Timer_4_Monat 7;
BA_ "NWM-WakeupAllowed" SG_ 1397 HVLM_Status_Timer_4_Monat 0;
BA_ "Fehlerwert" SG_ 1397 HVLM_Status_Timer_4_Monat 15;
BA_ "GenSigSendType" SG_ 1397 HVLM_Status_Timer_4_Stunde 7;
BA_ "NWM-WakeupAllowed" SG_ 1397 HVLM_Status_Timer_4_Stunde 0;
BA_ "GenSigStartValue" SG_ 1397 HVLM_Status_Timer_4_Stunde 30;
BA_ "Fehlerwert" SG_ 1397 HVLM_Status_Timer_4_Stunde 31;
BA_ "GenSigSendType" SG_ 1397 HVLM_Status_Timer_4_Tag 7;
BA_ "NWM-WakeupAllowed" SG_ 1397 HVLM_Status_Timer_4_Tag 0;
BA_ "GenSigSendType" SG_ 1397 HVLM_Status_Timer_4_Laden 7;
BA_ "NWM-WakeupAllowed" SG_ 1397 HVLM_Status_Timer_4_Laden 0;
BA_ "GenSigSendType" SG_ 1397 HVLM_Status_Timer_4_Vorklima 7;
BA_ "NWM-WakeupAllowed" SG_ 1397 HVLM_Status_Timer_4_Vorklima 0;
BA_ "GenSigSendType" SG_ 1397 HVLM_Status_Timer_4_Zyklus_Mo 7;
BA_ "NWM-WakeupAllowed" SG_ 1397 HVLM_Status_Timer_4_Zyklus_Mo 0;
BA_ "GenSigSendType" SG_ 1397 HVLM_Status_Timer_2_Vorklima 7;
BA_ "NWM-WakeupAllowed" SG_ 1397 HVLM_Status_Timer_2_Vorklima 0;
BA_ "GenSigSendType" SG_ 1397 HVLM_Status_Timer_3_Vorklima 7;
BA_ "NWM-WakeupAllowed" SG_ 1397 HVLM_Status_Timer_3_Vorklima 0;
BA_ "GenSigSendType" SG_ 1397 HVLM_Status_Timer_1_Zyklus_Mo 7;
BA_ "NWM-WakeupAllowed" SG_ 1397 HVLM_Status_Timer_1_Zyklus_Mo 0;
BA_ "GenSigSendType" SG_ 1397 HVLM_Status_Timer_2_Zyklus_Mo 7;
BA_ "NWM-WakeupAllowed" SG_ 1397 HVLM_Status_Timer_2_Zyklus_Mo 0;
BA_ "GenSigSendType" SG_ 1397 HVLM_Status_Timer_3_Zyklus_Mo 7;
BA_ "NWM-WakeupAllowed" SG_ 1397 HVLM_Status_Timer_3_Zyklus_Mo 0;
BA_ "GenSigSendType" SG_ 1397 HVLM_Status_Timer_1_Zyklus_Di 7;
BA_ "NWM-WakeupAllowed" SG_ 1397 HVLM_Status_Timer_1_Zyklus_Di 0;
BA_ "GenSigSendType" SG_ 1397 HVLM_Status_Timer_2_Zyklus_Di 7;
BA_ "NWM-WakeupAllowed" SG_ 1397 HVLM_Status_Timer_2_Zyklus_Di 0;
BA_ "GenSigSendType" SG_ 1397 HVLM_Status_Timer_3_Zyklus_Di 7;
BA_ "NWM-WakeupAllowed" SG_ 1397 HVLM_Status_Timer_3_Zyklus_Di 0;
BA_ "GenSigSendType" SG_ 1397 HVLM_Status_Timer_1_Zyklus_Mi 7;
BA_ "NWM-WakeupAllowed" SG_ 1397 HVLM_Status_Timer_1_Zyklus_Mi 0;
BA_ "GenSigSendType" SG_ 1397 HVLM_Status_Timer_2_Zyklus_Mi 7;
BA_ "NWM-WakeupAllowed" SG_ 1397 HVLM_Status_Timer_2_Zyklus_Mi 0;
BA_ "GenSigSendType" SG_ 1397 HVLM_Status_Timer_3_Zyklus_Mi 7;
BA_ "NWM-WakeupAllowed" SG_ 1397 HVLM_Status_Timer_3_Zyklus_Mi 0;
BA_ "GenSigSendType" SG_ 1397 HVLM_Status_Timer_1_Zyklus_Do 7;
BA_ "NWM-WakeupAllowed" SG_ 1397 HVLM_Status_Timer_1_Zyklus_Do 0;
BA_ "GenSigSendType" SG_ 1397 HVLM_Status_Timer_2_Zyklus_Do 7;
BA_ "NWM-WakeupAllowed" SG_ 1397 HVLM_Status_Timer_2_Zyklus_Do 0;
BA_ "GenSigSendType" SG_ 1397 HVLM_Status_Timer_3_Zyklus_Do 7;
BA_ "NWM-WakeupAllowed" SG_ 1397 HVLM_Status_Timer_3_Zyklus_Do 0;
BA_ "GenSigSendType" SG_ 1397 HVLM_Status_Timer_1_Zyklus_Fr 7;
BA_ "NWM-WakeupAllowed" SG_ 1397 HVLM_Status_Timer_1_Zyklus_Fr 0;
BA_ "GenSigSendType" SG_ 1397 HVLM_Status_Timer_2_Zyklus_Fr 7;
BA_ "NWM-WakeupAllowed" SG_ 1397 HVLM_Status_Timer_2_Zyklus_Fr 0;
BA_ "GenSigSendType" SG_ 1397 HVLM_Status_Timer_3_Zyklus_Fr 7;
BA_ "NWM-WakeupAllowed" SG_ 1397 HVLM_Status_Timer_3_Zyklus_Fr 0;
BA_ "GenSigSendType" SG_ 1397 HVLM_Status_Timer_1_Zyklus_Sa 7;
BA_ "NWM-WakeupAllowed" SG_ 1397 HVLM_Status_Timer_1_Zyklus_Sa 0;
BA_ "GenSigSendType" SG_ 1397 HVLM_Status_Timer_2_Zyklus_Sa 7;
BA_ "NWM-WakeupAllowed" SG_ 1397 HVLM_Status_Timer_2_Zyklus_Sa 0;
BA_ "GenSigSendType" SG_ 1397 HVLM_Status_Timer_3_Zyklus_Sa 7;
BA_ "NWM-WakeupAllowed" SG_ 1397 HVLM_Status_Timer_3_Zyklus_Sa 0;
BA_ "GenSigSendType" SG_ 1397 HVLM_Status_Timer_1_Zyklus_So 7;
BA_ "NWM-WakeupAllowed" SG_ 1397 HVLM_Status_Timer_1_Zyklus_So 0;
BA_ "GenSigSendType" SG_ 1397 HVLM_Status_Timer_2_Zyklus_So 7;
BA_ "NWM-WakeupAllowed" SG_ 1397 HVLM_Status_Timer_2_Zyklus_So 0;
BA_ "GenSigSendType" SG_ 1397 HVLM_Status_Timer_3_Zyklus_So 7;
BA_ "NWM-WakeupAllowed" SG_ 1397 HVLM_Status_Timer_3_Zyklus_So 0;
BA_ "GenSigSendType" SG_ 1397 HVLM_Status_Timer_1_Zyklus_WH 7;
BA_ "NWM-WakeupAllowed" SG_ 1397 HVLM_Status_Timer_1_Zyklus_WH 0;
BA_ "GenSigSendType" SG_ 1397 HVLM_Status_Timer_2_Zyklus_WH 7;
BA_ "NWM-WakeupAllowed" SG_ 1397 HVLM_Status_Timer_2_Zyklus_WH 0;
BA_ "NWM-WakeupAllowed" SG_ 1397 HVLM_Status_Timer_MUX 0;
BA_ "GenSigSendType" SG_ 1397 HVLM_Status_Timer_3_Zyklus_WH 7;
BA_ "NWM-WakeupAllowed" SG_ 1397 HVLM_Status_Timer_3_Zyklus_WH 0;
BA_ "NWM-WakeupAllowed" SG_ 1397 HVLM_Status_Nachtstrom_X_Std_Anf 0;
BA_ "GenSigStartValue" SG_ 1397 HVLM_Status_Nachtstrom_X_Std_Anf 62;
BA_ "NWM-WakeupAllowed" SG_ 1397 HVLM_Status_Nachtstrom_Prof 0;
BA_ "NWM-WakeupAllowed" SG_ 1397 HVLM_Status_Nachtstrom_X_Std_End 0;
BA_ "GenSigStartValue" SG_ 1397 HVLM_Status_Nachtstrom_X_Std_End 62;
BA_ "NWM-WakeupAllowed" SG_ 1397 HVLM_Status_Nachtstrom_Akt_Prof 0;
BA_ "NWM-WakeupAllowed" SG_ 1397 HVLM_Status_Laden 0;
BA_ "GenSigStartValue" SG_ 1397 HVLM_Status_Laden 6;
BA_ "Fehlerwert" SG_ 1397 HVLM_Status_Laden 7;
BA_ "GenSigSendType" SG_ 1397 HVLM_Status_Timer_4_Zyklus_Di 7;
BA_ "NWM-WakeupAllowed" SG_ 1397 HVLM_Status_Timer_4_Zyklus_Di 0;
BA_ "GenSigSendType" SG_ 1397 HVLM_Status_Timer_4_Zyklus_Mi 7;
BA_ "NWM-WakeupAllowed" SG_ 1397 HVLM_Status_Timer_4_Zyklus_Mi 0;
BA_ "GenSigSendType" SG_ 1397 HVLM_Status_Timer_4_Zyklus_Do 7;
BA_ "NWM-WakeupAllowed" SG_ 1397 HVLM_Status_Timer_4_Zyklus_Do 0;
BA_ "GenSigSendType" SG_ 1397 HVLM_Status_Timer_4_Zyklus_Fr 7;
BA_ "NWM-WakeupAllowed" SG_ 1397 HVLM_Status_Timer_4_Zyklus_Fr 0;
BA_ "GenSigSendType" SG_ 1397 HVLM_Status_Timer_1_Jahr 7;
BA_ "NWM-WakeupAllowed" SG_ 1397 HVLM_Status_Timer_1_Jahr 0;
BA_ "GenSigStartValue" SG_ 1397 HVLM_Status_Timer_1_Jahr 126;
BA_ "GenSigSendType" SG_ 1397 HVLM_Status_Timer_2_Jahr 7;
BA_ "NWM-WakeupAllowed" SG_ 1397 HVLM_Status_Timer_2_Jahr 0;
BA_ "GenSigStartValue" SG_ 1397 HVLM_Status_Timer_2_Jahr 126;
BA_ "GenSigSendType" SG_ 1397 HVLM_Status_Timer_3_Jahr 7;
BA_ "NWM-WakeupAllowed" SG_ 1397 HVLM_Status_Timer_3_Jahr 0;
BA_ "GenSigStartValue" SG_ 1397 HVLM_Status_Timer_3_Jahr 126;
BA_ "GenSigSendType" SG_ 1397 HVLM_Status_Timer_7_Jahr 7;
BA_ "NWM-WakeupAllowed" SG_ 1397 HVLM_Status_Timer_7_Jahr 0;
BA_ "GenSigStartValue" SG_ 1397 HVLM_Status_Timer_7_Jahr 126;
BA_ "GenSigSendType" SG_ 1397 HVLM_Status_Timer_1_Minute 7;
BA_ "NWM-WakeupAllowed" SG_ 1397 HVLM_Status_Timer_1_Minute 0;
BA_ "GenSigStartValue" SG_ 1397 HVLM_Status_Timer_1_Minute 62;
BA_ "Fehlerwert" SG_ 1397 HVLM_Status_Timer_1_Minute 63;
BA_ "GenSigSendType" SG_ 1397 HVLM_Status_Timer_2_Minute 7;
BA_ "NWM-WakeupAllowed" SG_ 1397 HVLM_Status_Timer_2_Minute 0;
BA_ "GenSigStartValue" SG_ 1397 HVLM_Status_Timer_2_Minute 62;
BA_ "Fehlerwert" SG_ 1397 HVLM_Status_Timer_2_Minute 63;
BA_ "GenSigSendType" SG_ 1397 HVLM_Status_Timer_3_Minute 7;
BA_ "NWM-WakeupAllowed" SG_ 1397 HVLM_Status_Timer_3_Minute 0;
BA_ "GenSigStartValue" SG_ 1397 HVLM_Status_Timer_3_Minute 62;
BA_ "Fehlerwert" SG_ 1397 HVLM_Status_Timer_3_Minute 63;
BA_ "GenSigSendType" SG_ 1397 HVLM_Status_Timer_7_Minute 7;
BA_ "NWM-WakeupAllowed" SG_ 1397 HVLM_Status_Timer_7_Minute 0;
BA_ "GenSigStartValue" SG_ 1397 HVLM_Status_Timer_7_Minute 62;
BA_ "Fehlerwert" SG_ 1397 HVLM_Status_Timer_7_Minute 63;
BA_ "GenSigSendType" SG_ 1397 HVLM_Status_Timer_1_Monat 7;
BA_ "NWM-WakeupAllowed" SG_ 1397 HVLM_Status_Timer_1_Monat 0;
BA_ "Fehlerwert" SG_ 1397 HVLM_Status_Timer_1_Monat 15;
BA_ "GenSigSendType" SG_ 1397 HVLM_Status_Timer_2_Monat 7;
BA_ "NWM-WakeupAllowed" SG_ 1397 HVLM_Status_Timer_2_Monat 0;
BA_ "Fehlerwert" SG_ 1397 HVLM_Status_Timer_2_Monat 15;
BA_ "GenSigSendType" SG_ 1397 HVLM_Status_Timer_3_Monat 7;
BA_ "NWM-WakeupAllowed" SG_ 1397 HVLM_Status_Timer_3_Monat 0;
BA_ "Fehlerwert" SG_ 1397 HVLM_Status_Timer_3_Monat 15;
BA_ "GenSigSendType" SG_ 1397 HVLM_Status_Timer_7_Monat 7;
BA_ "NWM-WakeupAllowed" SG_ 1397 HVLM_Status_Timer_7_Monat 0;
BA_ "Fehlerwert" SG_ 1397 HVLM_Status_Timer_7_Monat 15;
BA_ "GenSigSendType" SG_ 1397 HVLM_Status_Timer_1_Stunde 7;
BA_ "NWM-WakeupAllowed" SG_ 1397 HVLM_Status_Timer_1_Stunde 0;
BA_ "GenSigStartValue" SG_ 1397 HVLM_Status_Timer_1_Stunde 30;
BA_ "Fehlerwert" SG_ 1397 HVLM_Status_Timer_1_Stunde 31;
BA_ "GenSigSendType" SG_ 1397 HVLM_Status_Timer_2_Stunde 7;
BA_ "NWM-WakeupAllowed" SG_ 1397 HVLM_Status_Timer_2_Stunde 0;
BA_ "GenSigStartValue" SG_ 1397 HVLM_Status_Timer_2_Stunde 30;
BA_ "Fehlerwert" SG_ 1397 HVLM_Status_Timer_2_Stunde 31;
BA_ "GenSigSendType" SG_ 1397 HVLM_Status_Timer_3_Stunde 7;
BA_ "NWM-WakeupAllowed" SG_ 1397 HVLM_Status_Timer_3_Stunde 0;
BA_ "GenSigStartValue" SG_ 1397 HVLM_Status_Timer_3_Stunde 30;
BA_ "Fehlerwert" SG_ 1397 HVLM_Status_Timer_3_Stunde 31;
BA_ "GenSigSendType" SG_ 1397 HVLM_Status_Timer_7_Stunde 7;
BA_ "NWM-WakeupAllowed" SG_ 1397 HVLM_Status_Timer_7_Stunde 0;
BA_ "GenSigStartValue" SG_ 1397 HVLM_Status_Timer_7_Stunde 30;
BA_ "Fehlerwert" SG_ 1397 HVLM_Status_Timer_7_Stunde 31;
BA_ "GenSigSendType" SG_ 1397 HVLM_Status_Timer_1_Tag 7;
BA_ "NWM-WakeupAllowed" SG_ 1397 HVLM_Status_Timer_1_Tag 0;
BA_ "GenSigSendType" SG_ 1397 HVLM_Status_Timer_2_Tag 7;
BA_ "NWM-WakeupAllowed" SG_ 1397 HVLM_Status_Timer_2_Tag 0;
BA_ "GenSigSendType" SG_ 1397 HVLM_Status_Timer_3_Tag 7;
BA_ "NWM-WakeupAllowed" SG_ 1397 HVLM_Status_Timer_3_Tag 0;
BA_ "GenSigSendType" SG_ 1397 HVLM_Status_Timer_7_Tag 7;
BA_ "NWM-WakeupAllowed" SG_ 1397 HVLM_Status_Timer_7_Tag 0;
BA_ "GenSigSendType" SG_ 1397 HVLM_Status_Timer_1_Laden 7;
BA_ "NWM-WakeupAllowed" SG_ 1397 HVLM_Status_Timer_1_Laden 0;
BA_ "GenSigSendType" SG_ 1397 HVLM_Status_Timer_2_Laden 7;
BA_ "NWM-WakeupAllowed" SG_ 1397 HVLM_Status_Timer_2_Laden 0;
BA_ "GenSigSendType" SG_ 1397 HVLM_Status_Timer_3_Laden 7;
BA_ "NWM-WakeupAllowed" SG_ 1397 HVLM_Status_Timer_3_Laden 0;
BA_ "GenSigSendType" SG_ 1397 HVLM_Status_Timer_1_Vorklima 7;
BA_ "NWM-WakeupAllowed" SG_ 1397 HVLM_Status_Timer_1_Vorklima 0;
BA_ "GenSigSendType" SG_ 1397 HVLM_Status_Timer_4_Zyklus_Sa 7;
BA_ "NWM-WakeupAllowed" SG_ 1397 HVLM_Status_Timer_4_Zyklus_Sa 0;
BA_ "GenSigSendType" SG_ 1397 HVLM_Status_Timer_4_Zyklus_So 7;
BA_ "NWM-WakeupAllowed" SG_ 1397 HVLM_Status_Timer_4_Zyklus_So 0;
BA_ "GenSigSendType" SG_ 1397 HVLM_Status_Timer_4_Zyklus_WH 7;
BA_ "NWM-WakeupAllowed" SG_ 1397 HVLM_Status_Timer_4_Zyklus_WH 0;
BA_REL_ "GenSigTimeoutTime" BU_SG_REL_ Ladegeraet_PAG_PF SG_ 1728 NMH_GW_Start_1 2000;
BA_REL_ "GenSigTimeoutTime" BU_SG_REL_ Getriebe_Derivate SG_ 1728 NMH_GW_Start_1 2000;
BA_REL_ "GenSigTimeoutTime" BU_SG_REL_ Motor_MED17_Hybrid SG_ 1728 NMH_GW_Start_1 2000;
BA_REL_ "GenSigTimeoutTime" BU_SG_REL_ Motor_EDC17_Pirol SG_ 1728 NMH_GW_Start_1 2000;
BA_REL_ "GenSigTimeoutTime" BU_SG_REL_ LEH_Hybrid SG_ 1728 NMH_GW_Start_1 2000;
BA_REL_ "GenSigTimeoutTime" BU_SG_REL_ BMS_Hybrid SG_ 1728 NMH_GW_Start_1 2000;
BA_REL_ "GenSigTimeoutTime" BU_SG_REL_ Motor_MED17_Hybrid SG_ 1327 OBD_Fehler_Laengsbeschleunigung 2000;
BA_REL_ "GenSigTimeoutTime" BU_SG_REL_ Motor_MED17_Hybrid SG_ 1327 OBD_Fehler_Vordrucksensor 2000;
BA_REL_ "GenSigTimeoutTime" BU_SG_REL_ GW_Applikation_Derivate SG_ 1381 HVLM_IstSpannung_HV 5000;
BA_REL_ "GenSigTimeoutTime" BU_SG_REL_ GW_Routing_Derivate SG_ 1381 HVLM_IstSpannung_HV 5000;
BA_REL_ "GenSigTimeoutTime" BU_SG_REL_ GW_Routing_Derivate SG_ 1381 HVLM_HV_Abstellzeit 5000;
BA_REL_ "GenSigTimeoutTime" BU_SG_REL_ GW_Routing_Derivate SG_ 1381 HVLM_Zustand_LED 5000;
BA_REL_ "GenSigTimeoutTime" BU_SG_REL_ GW_Routing_Derivate SG_ 1381 HVLM_MaxLadezeitDCHV 5000;
BA_REL_ "GenSigTimeoutTime" BU_SG_REL_ GW_Routing_Derivate SG_ 1381 HVLM_MaxStrom_Netz 5000;
BA_REL_ "GenSigTimeoutTime" BU_SG_REL_ GW_Routing_Derivate SG_ 1381 HVLM_LG_Sollmodus 5000;
BA_REL_ "GenSigTimeoutTime" BU_SG_REL_ GW_Routing_Derivate SG_ 1381 HVLM_FreigabeTankdeckel 5000;
BA_REL_ "GenSigTimeoutTime" BU_SG_REL_ GW_Routing_Derivate SG_ 1381 HVLM_Stecker_Verriegeln 5000;
BA_REL_ "GenSigTimeoutTime" BU_SG_REL_ GW_Routing_Derivate SG_ 1381 HVLM_Start_Spannungsmessung_DCLS 5000;
BA_REL_ "GenSigTimeoutTime" BU_SG_REL_ GW_Routing_Derivate SG_ 1381 HVLM_Taster_Profil_Laden_Anf 5000;
BA_REL_ "GenSigTimeoutTime" BU_SG_REL_ GW_Routing_Derivate SG_ 1381 HVLM_Taster_Sofort_Laden_Anf 5000;
BA_REL_ "GenSigTimeoutTime" BU_SG_REL_ GW_Routing_Derivate SG_ 1381 HVLM_FreigabeKlimatisierung 5000;
BA_REL_ "GenSigTimeoutTime" BU_SG_REL_ GW_Routing_Derivate SG_ 1381 HVLM_Ladetexte 5000;
BA_REL_ "GenSigTimeoutTime" BU_SG_REL_ Ladegeraet_PAG_PF SG_ 1534 KBI_Set_Timer_MUX 5000;
BA_REL_ "GenSigTimeoutTime" BU_SG_REL_ Ladegeraet_PAG_PF SG_ 1534 KBI_Set_Timer_1_Jahr 5000;
BA_REL_ "GenSigTimeoutTime" BU_SG_REL_ Ladegeraet_PAG_PF SG_ 1534 KBI_Set_Timer_2_Jahr 5000;
BA_REL_ "GenSigTimeoutTime" BU_SG_REL_ Ladegeraet_PAG_PF SG_ 1534 KBI_Set_Timer_3_Jahr 5000;
BA_REL_ "GenSigTimeoutTime" BU_SG_REL_ Ladegeraet_PAG_PF SG_ 1534 KBI_Set_Timer_4_Jahr 5000;
BA_REL_ "GenSigTimeoutTime" BU_SG_REL_ Ladegeraet_PAG_PF SG_ 1534 KBI_Set_Timer_1_Minute 5000;
BA_REL_ "GenSigTimeoutTime" BU_SG_REL_ Ladegeraet_PAG_PF SG_ 1534 KBI_Set_Timer_2_Minute 5000;
BA_REL_ "GenSigTimeoutTime" BU_SG_REL_ Ladegeraet_PAG_PF SG_ 1534 KBI_Set_Timer_3_Minute 5000;
BA_REL_ "GenSigTimeoutTime" BU_SG_REL_ Ladegeraet_PAG_PF SG_ 1534 KBI_Set_Timer_4_Minute 5000;
BA_REL_ "GenSigTimeoutTime" BU_SG_REL_ Ladegeraet_PAG_PF SG_ 1534 KBI_Set_Timer_1_Monat 5000;
BA_REL_ "GenSigTimeoutTime" BU_SG_REL_ Ladegeraet_PAG_PF SG_ 1534 KBI_Set_Timer_2_Monat 5000;
BA_REL_ "GenSigTimeoutTime" BU_SG_REL_ Ladegeraet_PAG_PF SG_ 1534 KBI_Set_Timer_3_Monat 5000;
BA_REL_ "GenSigTimeoutTime" BU_SG_REL_ Ladegeraet_PAG_PF SG_ 1534 KBI_Set_Timer_4_Monat 5000;
BA_REL_ "GenSigTimeoutTime" BU_SG_REL_ Ladegeraet_PAG_PF SG_ 1534 KBI_Set_Timer_1_Stunde 5000;
BA_REL_ "GenSigTimeoutTime" BU_SG_REL_ Ladegeraet_PAG_PF SG_ 1534 KBI_Set_Timer_2_Stunde 5000;
BA_REL_ "GenSigTimeoutTime" BU_SG_REL_ Ladegeraet_PAG_PF SG_ 1534 KBI_Set_Timer_3_Stunde 5000;
BA_REL_ "GenSigTimeoutTime" BU_SG_REL_ Ladegeraet_PAG_PF SG_ 1534 KBI_Set_Timer_4_Stunde 5000;
BA_REL_ "GenSigTimeoutTime" BU_SG_REL_ Ladegeraet_PAG_PF SG_ 1534 KBI_Set_Timer_1_Tag 5000;
BA_REL_ "GenSigTimeoutTime" BU_SG_REL_ Ladegeraet_PAG_PF SG_ 1534 KBI_Set_Timer_2_Tag 5000;
BA_REL_ "GenSigTimeoutTime" BU_SG_REL_ Ladegeraet_PAG_PF SG_ 1534 KBI_Set_Timer_3_Tag 5000;
BA_REL_ "GenSigTimeoutTime" BU_SG_REL_ Ladegeraet_PAG_PF SG_ 1534 KBI_Set_Timer_4_Tag 5000;
BA_REL_ "GenSigTimeoutTime" BU_SG_REL_ Ladegeraet_PAG_PF SG_ 1534 KBI_Set_Timer_1_Laden 5000;
BA_REL_ "GenSigTimeoutTime" BU_SG_REL_ Ladegeraet_PAG_PF SG_ 1534 KBI_Set_Timer_2_Laden 5000;
BA_REL_ "GenSigTimeoutTime" BU_SG_REL_ Ladegeraet_PAG_PF SG_ 1534 KBI_Set_Timer_3_Laden 5000;
BA_REL_ "GenSigTimeoutTime" BU_SG_REL_ Ladegeraet_PAG_PF SG_ 1534 KBI_Set_Timer_4_Laden 5000;
BA_REL_ "GenSigTimeoutTime" BU_SG_REL_ Ladegeraet_PAG_PF SG_ 1534 KBI_Set_Timer_1_Vorklima 5000;
BA_REL_ "GenSigTimeoutTime" BU_SG_REL_ Ladegeraet_PAG_PF SG_ 1534 KBI_Set_Timer_2_Vorklima 5000;
BA_REL_ "GenSigTimeoutTime" BU_SG_REL_ Ladegeraet_PAG_PF SG_ 1534 KBI_Set_Timer_3_Vorklima 5000;
BA_REL_ "GenSigTimeoutTime" BU_SG_REL_ Ladegeraet_PAG_PF SG_ 1534 KBI_Set_Timer_4_Vorklima 5000;
BA_REL_ "GenSigTimeoutTime" BU_SG_REL_ Ladegeraet_PAG_PF SG_ 1534 KBI_Set_Timer_1_Zyklus_Mo 5000;
BA_REL_ "GenSigTimeoutTime" BU_SG_REL_ Ladegeraet_PAG_PF SG_ 1534 KBI_Set_Timer_2_Zyklus_Mo 5000;
BA_REL_ "GenSigTimeoutTime" BU_SG_REL_ Ladegeraet_PAG_PF SG_ 1534 KBI_Set_Timer_3_Zyklus_Mo 5000;
BA_REL_ "GenSigTimeoutTime" BU_SG_REL_ Ladegeraet_PAG_PF SG_ 1534 KBI_Set_Timer_4_Zyklus_Mo 5000;
BA_REL_ "GenSigTimeoutTime" BU_SG_REL_ Ladegeraet_PAG_PF SG_ 1534 KBI_Set_Timer_1_Zyklus_Di 5000;
BA_REL_ "GenSigTimeoutTime" BU_SG_REL_ Ladegeraet_PAG_PF SG_ 1534 KBI_Set_Timer_2_Zyklus_Di 5000;
BA_REL_ "GenSigTimeoutTime" BU_SG_REL_ Ladegeraet_PAG_PF SG_ 1534 KBI_Set_Timer_3_Zyklus_Di 5000;
BA_REL_ "GenSigTimeoutTime" BU_SG_REL_ Ladegeraet_PAG_PF SG_ 1534 KBI_Set_Timer_4_Zyklus_Di 5000;
BA_REL_ "GenSigTimeoutTime" BU_SG_REL_ Ladegeraet_PAG_PF SG_ 1534 KBI_Set_Timer_1_Zyklus_Mi 5000;
BA_REL_ "GenSigTimeoutTime" BU_SG_REL_ Ladegeraet_PAG_PF SG_ 1534 KBI_Set_Timer_2_Zyklus_Mi 5000;
BA_REL_ "GenSigTimeoutTime" BU_SG_REL_ Ladegeraet_PAG_PF SG_ 1534 KBI_Set_Timer_3_Zyklus_Mi 5000;
BA_REL_ "GenSigTimeoutTime" BU_SG_REL_ Ladegeraet_PAG_PF SG_ 1534 KBI_Set_Timer_4_Zyklus_Mi 5000;
BA_REL_ "GenSigTimeoutTime" BU_SG_REL_ Ladegeraet_PAG_PF SG_ 1534 KBI_Set_Timer_1_Zyklus_Do 5000;
BA_REL_ "GenSigTimeoutTime" BU_SG_REL_ Ladegeraet_PAG_PF SG_ 1534 KBI_Set_Timer_2_Zyklus_Do 5000;
BA_REL_ "GenSigTimeoutTime" BU_SG_REL_ Ladegeraet_PAG_PF SG_ 1534 KBI_Set_Timer_3_Zyklus_Do 5000;
BA_REL_ "GenSigTimeoutTime" BU_SG_REL_ Ladegeraet_PAG_PF SG_ 1534 KBI_Set_Timer_4_Zyklus_Do 5000;
BA_REL_ "GenSigTimeoutTime" BU_SG_REL_ Ladegeraet_PAG_PF SG_ 1534 KBI_Set_Timer_1_Zyklus_Fr 5000;
BA_REL_ "GenSigTimeoutTime" BU_SG_REL_ Ladegeraet_PAG_PF SG_ 1534 KBI_Set_Timer_2_Zyklus_Fr 5000;
BA_REL_ "GenSigTimeoutTime" BU_SG_REL_ Ladegeraet_PAG_PF SG_ 1534 KBI_Set_Timer_3_Zyklus_Fr 5000;
BA_REL_ "GenSigTimeoutTime" BU_SG_REL_ Ladegeraet_PAG_PF SG_ 1534 KBI_Set_Timer_4_Zyklus_Fr 5000;
BA_REL_ "GenSigTimeoutTime" BU_SG_REL_ Ladegeraet_PAG_PF SG_ 1534 KBI_Set_Timer_1_Zyklus_Sa 5000;
BA_REL_ "GenSigTimeoutTime" BU_SG_REL_ Ladegeraet_PAG_PF SG_ 1534 KBI_Set_Timer_2_Zyklus_Sa 5000;
BA_REL_ "GenSigTimeoutTime" BU_SG_REL_ Ladegeraet_PAG_PF SG_ 1534 KBI_Set_Timer_3_Zyklus_Sa 5000;
BA_REL_ "GenSigTimeoutTime" BU_SG_REL_ Ladegeraet_PAG_PF SG_ 1534 KBI_Set_Timer_4_Zyklus_Sa 5000;
BA_REL_ "GenSigTimeoutTime" BU_SG_REL_ Ladegeraet_PAG_PF SG_ 1534 KBI_Set_Timer_1_Zyklus_So 5000;
BA_REL_ "GenSigTimeoutTime" BU_SG_REL_ Ladegeraet_PAG_PF SG_ 1534 KBI_Set_Timer_2_Zyklus_So 5000;
BA_REL_ "GenSigTimeoutTime" BU_SG_REL_ Ladegeraet_PAG_PF SG_ 1534 KBI_Set_Timer_3_Zyklus_So 5000;
BA_REL_ "GenSigTimeoutTime" BU_SG_REL_ Ladegeraet_PAG_PF SG_ 1534 KBI_Set_Timer_4_Zyklus_So 5000;
BA_REL_ "GenSigTimeoutTime" BU_SG_REL_ Ladegeraet_PAG_PF SG_ 1534 KBI_Set_Timer_1_Zyklus_WH 5000;
BA_REL_ "GenSigTimeoutTime" BU_SG_REL_ Ladegeraet_PAG_PF SG_ 1534 KBI_Set_Timer_2_Zyklus_WH 5000;
BA_REL_ "GenSigTimeoutTime" BU_SG_REL_ Ladegeraet_PAG_PF SG_ 1534 KBI_Set_Timer_3_Zyklus_WH 5000;
BA_REL_ "GenSigTimeoutTime" BU_SG_REL_ Ladegeraet_PAG_PF SG_ 1534 KBI_Set_Timer_4_Zyklus_WH 5000;
BA_REL_ "GenSigTimeoutTime" BU_SG_REL_ Ladegeraet_PAG_PF SG_ 1534 KBI_STH_Status 5000;
BA_REL_ "GenSigTimeoutTime" BU_SG_REL_ BMS_Hybrid SG_ 1631 MO_Energieinhalt_BMS 5000;
BA_REL_ "GenSigTimeoutTime" BU_SG_REL_ Ladegeraet_PAG_PF SG_ 1398 MOD_Set_Timerladen 5000;
BA_REL_ "GenSigTimeoutTime" BU_SG_REL_ Ladegeraet_PAG_PF SG_ 1398 MOD_Set_Sofortladen 5000;
BA_REL_ "GenSigTimeoutTime" BU_SG_REL_ Ladegeraet_PAG_PF SG_ 1398 MOD_Set_Timer_4_Jahr 5000;
BA_REL_ "GenSigTimeoutTime" BU_SG_REL_ Ladegeraet_PAG_PF SG_ 1398 MOD_Set_Timer_4_Minute 5000;
BA_REL_ "GenSigTimeoutTime" BU_SG_REL_ Ladegeraet_PAG_PF SG_ 1398 MOD_Set_Timer_4_Monat 5000;
BA_REL_ "GenSigTimeoutTime" BU_SG_REL_ Ladegeraet_PAG_PF SG_ 1398 MOD_Set_Timer_4_Stunde 5000;
BA_REL_ "GenSigTimeoutTime" BU_SG_REL_ Ladegeraet_PAG_PF SG_ 1398 MOD_Set_Timer_4_Tag 5000;
BA_REL_ "GenSigTimeoutTime" BU_SG_REL_ Ladegeraet_PAG_PF SG_ 1398 MOD_Set_Timer_4_Laden 5000;
BA_REL_ "GenSigTimeoutTime" BU_SG_REL_ Ladegeraet_PAG_PF SG_ 1398 MOD_Set_Timer_4_Vorklima 5000;
BA_REL_ "GenSigTimeoutTime" BU_SG_REL_ Ladegeraet_PAG_PF SG_ 1398 MOD_Set_Timer_4_Zyklus_Mo 5000;
BA_REL_ "GenSigTimeoutTime" BU_SG_REL_ Ladegeraet_PAG_PF SG_ 1398 MOD_Set_Timer_4_Zyklus_Di 5000;
BA_REL_ "GenSigTimeoutTime" BU_SG_REL_ Ladegeraet_PAG_PF SG_ 1398 MOD_Set_Timer_4_Zyklus_Mi 5000;
BA_REL_ "GenSigTimeoutTime" BU_SG_REL_ Ladegeraet_PAG_PF SG_ 1398 MOD_Set_Timer_4_Zyklus_Do 5000;
BA_REL_ "GenSigTimeoutTime" BU_SG_REL_ Ladegeraet_PAG_PF SG_ 1398 MOD_Set_Timer_4_Zyklus_Fr 5000;
BA_REL_ "GenSigTimeoutTime" BU_SG_REL_ Ladegeraet_PAG_PF SG_ 1398 MOD_Set_Timer_4_Zyklus_Sa 5000;
BA_REL_ "GenSigTimeoutTime" BU_SG_REL_ Ladegeraet_PAG_PF SG_ 1398 MOD_Set_Timer_4_Zyklus_So 5000;
BA_REL_ "GenSigTimeoutTime" BU_SG_REL_ Ladegeraet_PAG_PF SG_ 1398 MOD_Set_Timer_4_Zyklus_WH 5000;
BA_REL_ "GenSigTimeoutTime" BU_SG_REL_ Ladegeraet_PAG_PF SG_ 1398 MOD_Set_Timer_1_Jahr 5000;
BA_REL_ "GenSigTimeoutTime" BU_SG_REL_ Ladegeraet_PAG_PF SG_ 1398 MOD_Set_Timer_2_Jahr 5000;
BA_REL_ "GenSigTimeoutTime" BU_SG_REL_ Ladegeraet_PAG_PF SG_ 1398 MOD_Set_Timer_3_Jahr 5000;
BA_REL_ "GenSigTimeoutTime" BU_SG_REL_ Ladegeraet_PAG_PF SG_ 1398 MOD_Set_Timer_1_Minute 5000;
BA_REL_ "GenSigTimeoutTime" BU_SG_REL_ Ladegeraet_PAG_PF SG_ 1398 MOD_Set_Timer_2_Minute 5000;
BA_REL_ "GenSigTimeoutTime" BU_SG_REL_ Ladegeraet_PAG_PF SG_ 1398 MOD_Set_Timer_3_Minute 5000;
BA_REL_ "GenSigTimeoutTime" BU_SG_REL_ Ladegeraet_PAG_PF SG_ 1398 MOD_Set_Timer_1_Monat 5000;
BA_REL_ "GenSigTimeoutTime" BU_SG_REL_ Ladegeraet_PAG_PF SG_ 1398 MOD_Set_Timer_2_Monat 5000;
BA_REL_ "GenSigTimeoutTime" BU_SG_REL_ Ladegeraet_PAG_PF SG_ 1398 MOD_Set_Timer_3_Monat 5000;
BA_REL_ "GenSigTimeoutTime" BU_SG_REL_ Ladegeraet_PAG_PF SG_ 1398 MOD_Set_Timer_1_Stunde 5000;
BA_REL_ "GenSigTimeoutTime" BU_SG_REL_ Ladegeraet_PAG_PF SG_ 1398 MOD_Set_Timer_2_Stunde 5000;
BA_REL_ "GenSigTimeoutTime" BU_SG_REL_ Ladegeraet_PAG_PF SG_ 1398 MOD_Set_Timer_3_Stunde 5000;
BA_REL_ "GenSigTimeoutTime" BU_SG_REL_ Ladegeraet_PAG_PF SG_ 1398 MOD_Set_Timer_1_Tag 5000;
BA_REL_ "GenSigTimeoutTime" BU_SG_REL_ Ladegeraet_PAG_PF SG_ 1398 MOD_Set_Timer_2_Tag 5000;
BA_REL_ "GenSigTimeoutTime" BU_SG_REL_ Ladegeraet_PAG_PF SG_ 1398 MOD_Set_Timer_3_Tag 5000;
BA_REL_ "GenSigTimeoutTime" BU_SG_REL_ Ladegeraet_PAG_PF SG_ 1398 MOD_Set_Timer_1_Laden 5000;
BA_REL_ "GenSigTimeoutTime" BU_SG_REL_ Ladegeraet_PAG_PF SG_ 1398 MOD_Set_Timer_2_Laden 5000;
BA_REL_ "GenSigTimeoutTime" BU_SG_REL_ Ladegeraet_PAG_PF SG_ 1398 MOD_Set_Timer_3_Laden 5000;
BA_REL_ "GenSigTimeoutTime" BU_SG_REL_ Ladegeraet_PAG_PF SG_ 1398 MOD_Set_Timer_1_Vorklima 5000;
BA_REL_ "GenSigTimeoutTime" BU_SG_REL_ Ladegeraet_PAG_PF SG_ 1398 MOD_Set_Timer_2_Vorklima 5000;
BA_REL_ "GenSigTimeoutTime" BU_SG_REL_ Ladegeraet_PAG_PF SG_ 1398 MOD_Set_Timer_3_Vorklima 5000;
BA_REL_ "GenSigTimeoutTime" BU_SG_REL_ Ladegeraet_PAG_PF SG_ 1398 MOD_Set_Timer_1_Zyklus_Mo 5000;
BA_REL_ "GenSigTimeoutTime" BU_SG_REL_ Ladegeraet_PAG_PF SG_ 1398 MOD_Set_Timer_2_Zyklus_Mo 5000;
BA_REL_ "GenSigTimeoutTime" BU_SG_REL_ Ladegeraet_PAG_PF SG_ 1398 MOD_Set_Timer_3_Zyklus_Mo 5000;
BA_REL_ "GenSigTimeoutTime" BU_SG_REL_ Ladegeraet_PAG_PF SG_ 1398 MOD_Set_Timer_1_Zyklus_Di 5000;
BA_REL_ "GenSigTimeoutTime" BU_SG_REL_ Ladegeraet_PAG_PF SG_ 1398 MOD_Set_Timer_2_Zyklus_Di 5000;
BA_REL_ "GenSigTimeoutTime" BU_SG_REL_ Ladegeraet_PAG_PF SG_ 1398 MOD_Set_Timer_3_Zyklus_Di 5000;
BA_REL_ "GenSigTimeoutTime" BU_SG_REL_ Ladegeraet_PAG_PF SG_ 1398 MOD_Set_Timer_1_Zyklus_Mi 5000;
BA_REL_ "GenSigTimeoutTime" BU_SG_REL_ Ladegeraet_PAG_PF SG_ 1398 MOD_Set_Timer_2_Zyklus_Mi 5000;
BA_REL_ "GenSigTimeoutTime" BU_SG_REL_ Ladegeraet_PAG_PF SG_ 1398 MOD_Set_Timer_3_Zyklus_Mi 5000;
BA_REL_ "GenSigTimeoutTime" BU_SG_REL_ Ladegeraet_PAG_PF SG_ 1398 MOD_Set_Timer_1_Zyklus_Do 5000;
BA_REL_ "GenSigTimeoutTime" BU_SG_REL_ Ladegeraet_PAG_PF SG_ 1398 MOD_Set_Timer_2_Zyklus_Do 5000;
BA_REL_ "GenSigTimeoutTime" BU_SG_REL_ Ladegeraet_PAG_PF SG_ 1398 MOD_Set_Timer_3_Zyklus_Do 5000;
BA_REL_ "GenSigTimeoutTime" BU_SG_REL_ Ladegeraet_PAG_PF SG_ 1398 MOD_Set_Timer_1_Zyklus_Fr 5000;
BA_REL_ "GenSigTimeoutTime" BU_SG_REL_ Ladegeraet_PAG_PF SG_ 1398 MOD_Set_Timer_2_Zyklus_Fr 5000;
BA_REL_ "GenSigTimeoutTime" BU_SG_REL_ Ladegeraet_PAG_PF SG_ 1398 MOD_Set_Timer_3_Zyklus_Fr 5000;
BA_REL_ "GenSigTimeoutTime" BU_SG_REL_ Ladegeraet_PAG_PF SG_ 1398 MOD_Set_Timer_1_Zyklus_Sa 5000;
BA_REL_ "GenSigTimeoutTime" BU_SG_REL_ Ladegeraet_PAG_PF SG_ 1398 MOD_Set_Timer_2_Zyklus_Sa 5000;
BA_REL_ "GenSigTimeoutTime" BU_SG_REL_ Ladegeraet_PAG_PF SG_ 1398 MOD_Set_Timer_3_Zyklus_Sa 5000;
BA_REL_ "GenSigTimeoutTime" BU_SG_REL_ Ladegeraet_PAG_PF SG_ 1398 MOD_Set_Timer_1_Zyklus_So 5000;
BA_REL_ "GenSigTimeoutTime" BU_SG_REL_ Ladegeraet_PAG_PF SG_ 1398 MOD_Set_Timer_2_Zyklus_So 5000;
BA_REL_ "GenSigTimeoutTime" BU_SG_REL_ Ladegeraet_PAG_PF SG_ 1398 MOD_Set_Timer_3_Zyklus_So 5000;
BA_REL_ "GenSigTimeoutTime" BU_SG_REL_ Ladegeraet_PAG_PF SG_ 1398 MOD_Set_Timer_1_Zyklus_WH 5000;
BA_REL_ "GenSigTimeoutTime" BU_SG_REL_ Ladegeraet_PAG_PF SG_ 1398 MOD_Set_Timer_2_Zyklus_WH 5000;
BA_REL_ "GenSigTimeoutTime" BU_SG_REL_ Ladegeraet_PAG_PF SG_ 1398 MOD_Set_Timer_MUX 5000;
BA_REL_ "GenSigTimeoutTime" BU_SG_REL_ Ladegeraet_PAG_PF SG_ 1398 MOD_Set_Timer_3_Zyklus_WH 5000;
BA_REL_ "GenSigTimeoutTime" BU_SG_REL_ Ladegeraet_PAG_PF SG_ 1398 MOD_Set_Nachtstrom_X_Std_Anf 5000;
BA_REL_ "GenSigTimeoutTime" BU_SG_REL_ Ladegeraet_PAG_PF SG_ 1398 MOD_Set_Nachtstrom_Prof 5000;
BA_REL_ "GenSigTimeoutTime" BU_SG_REL_ Ladegeraet_PAG_PF SG_ 1398 MOD_Set_Nachtstrom_X_Std_End 5000;
BA_REL_ "GenSigTimeoutTime" BU_SG_REL_ Ladegeraet_PAG_PF SG_ 1398 MOD_Set_Nachtstrom_Akt_Prof 5000;
BA_REL_ "GenSigTimeoutTime" BU_SG_REL_ Ladegeraet_PAG_PF SG_ 1398 MOD_Set_Abbruch_Klima 5000;
BA_REL_ "GenSigTimeoutTime" BU_SG_REL_ Ladegeraet_PAG_PF SG_ 1398 MOD_Set_Sofortstart_Klima 5000;
BA_REL_ "GenSigTimeoutTime" BU_SG_REL_ GW_Routing_Derivate SG_ 1397 HVLM_Status_naechster_Ladetimer 5000;
BA_REL_ "GenSigTimeoutTime" BU_SG_REL_ GW_Routing_Derivate SG_ 1397 HVLM_Status_naechster_Klimatimer 5000;
BA_REL_ "GenSigTimeoutTime" BU_SG_REL_ GW_Routing_Derivate SG_ 1397 HVLM_Status_Timer_7_Laden 5000;
BA_REL_ "GenSigTimeoutTime" BU_SG_REL_ GW_Routing_Derivate SG_ 1397 HVLM_Ladetexte 5000;
BA_REL_ "GenSigTimeoutTime" BU_SG_REL_ GW_Routing_Derivate SG_ 1397 HVLM_Status_Timer_4_Jahr 5000;
BA_REL_ "GenSigTimeoutTime" BU_SG_REL_ GW_Routing_Derivate SG_ 1397 HVLM_Status_Timer_4_Minute 5000;
BA_REL_ "GenSigTimeoutTime" BU_SG_REL_ GW_Routing_Derivate SG_ 1397 HVLM_Status_Timer_4_Monat 5000;
BA_REL_ "GenSigTimeoutTime" BU_SG_REL_ GW_Routing_Derivate SG_ 1397 HVLM_Status_Timer_4_Stunde 5000;
BA_REL_ "GenSigTimeoutTime" BU_SG_REL_ GW_Routing_Derivate SG_ 1397 HVLM_Status_Timer_4_Tag 5000;
BA_REL_ "GenSigTimeoutTime" BU_SG_REL_ GW_Routing_Derivate SG_ 1397 HVLM_Status_Timer_4_Laden 5000;
BA_REL_ "GenSigTimeoutTime" BU_SG_REL_ GW_Routing_Derivate SG_ 1397 HVLM_Status_Timer_4_Vorklima 5000;
BA_REL_ "GenSigTimeoutTime" BU_SG_REL_ GW_Routing_Derivate SG_ 1397 HVLM_Status_Timer_4_Zyklus_Mo 5000;
BA_REL_ "GenSigTimeoutTime" BU_SG_REL_ GW_Routing_Derivate SG_ 1397 HVLM_Status_Timer_2_Vorklima 5000;
BA_REL_ "GenSigTimeoutTime" BU_SG_REL_ GW_Routing_Derivate SG_ 1397 HVLM_Status_Timer_3_Vorklima 5000;
BA_REL_ "GenSigTimeoutTime" BU_SG_REL_ GW_Routing_Derivate SG_ 1397 HVLM_Status_Timer_1_Zyklus_Mo 5000;
BA_REL_ "GenSigTimeoutTime" BU_SG_REL_ GW_Routing_Derivate SG_ 1397 HVLM_Status_Timer_2_Zyklus_Mo 5000;
BA_REL_ "GenSigTimeoutTime" BU_SG_REL_ GW_Routing_Derivate SG_ 1397 HVLM_Status_Timer_3_Zyklus_Mo 5000;
BA_REL_ "GenSigTimeoutTime" BU_SG_REL_ GW_Routing_Derivate SG_ 1397 HVLM_Status_Timer_1_Zyklus_Di 5000;
BA_REL_ "GenSigTimeoutTime" BU_SG_REL_ GW_Routing_Derivate SG_ 1397 HVLM_Status_Timer_2_Zyklus_Di 5000;
BA_REL_ "GenSigTimeoutTime" BU_SG_REL_ GW_Routing_Derivate SG_ 1397 HVLM_Status_Timer_3_Zyklus_Di 5000;
BA_REL_ "GenSigTimeoutTime" BU_SG_REL_ GW_Routing_Derivate SG_ 1397 HVLM_Status_Timer_1_Zyklus_Mi 5000;
BA_REL_ "GenSigTimeoutTime" BU_SG_REL_ GW_Routing_Derivate SG_ 1397 HVLM_Status_Timer_2_Zyklus_Mi 5000;
BA_REL_ "GenSigTimeoutTime" BU_SG_REL_ GW_Routing_Derivate SG_ 1397 HVLM_Status_Timer_3_Zyklus_Mi 5000;
BA_REL_ "GenSigTimeoutTime" BU_SG_REL_ GW_Routing_Derivate SG_ 1397 HVLM_Status_Timer_1_Zyklus_Do 5000;
BA_REL_ "GenSigTimeoutTime" BU_SG_REL_ GW_Routing_Derivate SG_ 1397 HVLM_Status_Timer_2_Zyklus_Do 5000;
BA_REL_ "GenSigTimeoutTime" BU_SG_REL_ GW_Routing_Derivate SG_ 1397 HVLM_Status_Timer_3_Zyklus_Do 5000;
BA_REL_ "GenSigTimeoutTime" BU_SG_REL_ GW_Routing_Derivate SG_ 1397 HVLM_Status_Timer_1_Zyklus_Fr 5000;
BA_REL_ "GenSigTimeoutTime" BU_SG_REL_ GW_Routing_Derivate SG_ 1397 HVLM_Status_Timer_2_Zyklus_Fr 5000;
BA_REL_ "GenSigTimeoutTime" BU_SG_REL_ GW_Routing_Derivate SG_ 1397 HVLM_Status_Timer_3_Zyklus_Fr 5000;
BA_REL_ "GenSigTimeoutTime" BU_SG_REL_ GW_Routing_Derivate SG_ 1397 HVLM_Status_Timer_1_Zyklus_Sa 5000;
BA_REL_ "GenSigTimeoutTime" BU_SG_REL_ GW_Routing_Derivate SG_ 1397 HVLM_Status_Timer_2_Zyklus_Sa 5000;
BA_REL_ "GenSigTimeoutTime" BU_SG_REL_ GW_Routing_Derivate SG_ 1397 HVLM_Status_Timer_3_Zyklus_Sa 5000;
BA_REL_ "GenSigTimeoutTime" BU_SG_REL_ GW_Routing_Derivate SG_ 1397 HVLM_Status_Timer_1_Zyklus_So 5000;
BA_REL_ "GenSigTimeoutTime" BU_SG_REL_ GW_Routing_Derivate SG_ 1397 HVLM_Status_Timer_2_Zyklus_So 5000;
BA_REL_ "GenSigTimeoutTime" BU_SG_REL_ GW_Routing_Derivate SG_ 1397 HVLM_Status_Timer_3_Zyklus_So 5000;
BA_REL_ "GenSigTimeoutTime" BU_SG_REL_ GW_Routing_Derivate SG_ 1397 HVLM_Status_Timer_1_Zyklus_WH 5000;
BA_REL_ "GenSigTimeoutTime" BU_SG_REL_ GW_Routing_Derivate SG_ 1397 HVLM_Status_Timer_2_Zyklus_WH 5000;
BA_REL_ "GenSigTimeoutTime" BU_SG_REL_ GW_Routing_Derivate SG_ 1397 HVLM_Status_Timer_MUX 5000;
BA_REL_ "GenSigTimeoutTime" BU_SG_REL_ GW_Routing_Derivate SG_ 1397 HVLM_Status_Timer_3_Zyklus_WH 5000;
BA_REL_ "GenSigTimeoutTime" BU_SG_REL_ GW_Routing_Derivate SG_ 1397 HVLM_Status_Nachtstrom_X_Std_Anf 5000;
BA_REL_ "GenSigTimeoutTime" BU_SG_REL_ GW_Routing_Derivate SG_ 1397 HVLM_Status_Nachtstrom_Prof 5000;
BA_REL_ "GenSigTimeoutTime" BU_SG_REL_ GW_Routing_Derivate SG_ 1397 HVLM_Status_Nachtstrom_X_Std_End 5000;
BA_REL_ "GenSigTimeoutTime" BU_SG_REL_ GW_Routing_Derivate SG_ 1397 HVLM_Status_Nachtstrom_Akt_Prof 5000;
BA_REL_ "GenSigTimeoutTime" BU_SG_REL_ GW_Routing_Derivate SG_ 1397 HVLM_Status_Laden 5000;
BA_REL_ "GenSigTimeoutTime" BU_SG_REL_ GW_Routing_Derivate SG_ 1397 HVLM_Status_Timer_4_Zyklus_Di 5000;
BA_REL_ "GenSigTimeoutTime" BU_SG_REL_ GW_Routing_Derivate SG_ 1397 HVLM_Status_Timer_4_Zyklus_Mi 5000;
BA_REL_ "GenSigTimeoutTime" BU_SG_REL_ GW_Routing_Derivate SG_ 1397 HVLM_Status_Timer_4_Zyklus_Do 5000;
BA_REL_ "GenSigTimeoutTime" BU_SG_REL_ GW_Routing_Derivate SG_ 1397 HVLM_Status_Timer_4_Zyklus_Fr 5000;
BA_REL_ "GenSigTimeoutTime" BU_SG_REL_ GW_Routing_Derivate SG_ 1397 HVLM_Status_Timer_1_Jahr 5000;
BA_REL_ "GenSigTimeoutTime" BU_SG_REL_ GW_Routing_Derivate SG_ 1397 HVLM_Status_Timer_2_Jahr 5000;
BA_REL_ "GenSigTimeoutTime" BU_SG_REL_ GW_Routing_Derivate SG_ 1397 HVLM_Status_Timer_3_Jahr 5000;
BA_REL_ "GenSigTimeoutTime" BU_SG_REL_ GW_Routing_Derivate SG_ 1397 HVLM_Status_Timer_7_Jahr 5000;
BA_REL_ "GenSigTimeoutTime" BU_SG_REL_ GW_Routing_Derivate SG_ 1397 HVLM_Status_Timer_1_Minute 5000;
BA_REL_ "GenSigTimeoutTime" BU_SG_REL_ GW_Routing_Derivate SG_ 1397 HVLM_Status_Timer_2_Minute 5000;
BA_REL_ "GenSigTimeoutTime" BU_SG_REL_ GW_Routing_Derivate SG_ 1397 HVLM_Status_Timer_3_Minute 5000;
BA_REL_ "GenSigTimeoutTime" BU_SG_REL_ GW_Routing_Derivate SG_ 1397 HVLM_Status_Timer_7_Minute 5000;
BA_REL_ "GenSigTimeoutTime" BU_SG_REL_ GW_Routing_Derivate SG_ 1397 HVLM_Status_Timer_1_Monat 5000;
BA_REL_ "GenSigTimeoutTime" BU_SG_REL_ GW_Routing_Derivate SG_ 1397 HVLM_Status_Timer_2_Monat 5000;
BA_REL_ "GenSigTimeoutTime" BU_SG_REL_ GW_Routing_Derivate SG_ 1397 HVLM_Status_Timer_3_Monat 5000;
BA_REL_ "GenSigTimeoutTime" BU_SG_REL_ GW_Routing_Derivate SG_ 1397 HVLM_Status_Timer_7_Monat 5000;
BA_REL_ "GenSigTimeoutTime" BU_SG_REL_ GW_Routing_Derivate SG_ 1397 HVLM_Status_Timer_1_Stunde 5000;
BA_REL_ "GenSigTimeoutTime" BU_SG_REL_ GW_Routing_Derivate SG_ 1397 HVLM_Status_Timer_2_Stunde 5000;
BA_REL_ "GenSigTimeoutTime" BU_SG_REL_ GW_Routing_Derivate SG_ 1397 HVLM_Status_Timer_3_Stunde 5000;
BA_REL_ "GenSigTimeoutTime" BU_SG_REL_ GW_Routing_Derivate SG_ 1397 HVLM_Status_Timer_7_Stunde 5000;
BA_REL_ "GenSigTimeoutTime" BU_SG_REL_ GW_Routing_Derivate SG_ 1397 HVLM_Status_Timer_1_Tag 5000;
BA_REL_ "GenSigTimeoutTime" BU_SG_REL_ GW_Routing_Derivate SG_ 1397 HVLM_Status_Timer_2_Tag 5000;
BA_REL_ "GenSigTimeoutTime" BU_SG_REL_ GW_Routing_Derivate SG_ 1397 HVLM_Status_Timer_3_Tag 5000;
BA_REL_ "GenSigTimeoutTime" BU_SG_REL_ GW_Routing_Derivate SG_ 1397 HVLM_Status_Timer_7_Tag 5000;
BA_REL_ "GenSigTimeoutTime" BU_SG_REL_ GW_Routing_Derivate SG_ 1397 HVLM_Status_Timer_1_Laden 5000;
BA_REL_ "GenSigTimeoutTime" BU_SG_REL_ GW_Routing_Derivate SG_ 1397 HVLM_Status_Timer_2_Laden 5000;
BA_REL_ "GenSigTimeoutTime" BU_SG_REL_ GW_Routing_Derivate SG_ 1397 HVLM_Status_Timer_3_Laden 5000;
BA_REL_ "GenSigTimeoutTime" BU_SG_REL_ GW_Routing_Derivate SG_ 1397 HVLM_Status_Timer_1_Vorklima 5000;
BA_REL_ "GenSigTimeoutTime" BU_SG_REL_ GW_Routing_Derivate SG_ 1397 HVLM_Status_Timer_4_Zyklus_Sa 5000;
BA_REL_ "GenSigTimeoutTime" BU_SG_REL_ GW_Routing_Derivate SG_ 1397 HVLM_Status_Timer_4_Zyklus_So 5000;
BA_REL_ "GenSigTimeoutTime" BU_SG_REL_ GW_Routing_Derivate SG_ 1397 HVLM_Status_Timer_4_Zyklus_WH 5000;
BA_REL_ "HYB_Tx_Baureihe" BU_BO_REL_ GW_Routing_Derivate 1534 2;
BA_REL_ "HYB_Tx_Baureihe" BU_BO_REL_ GW_Routing_Derivate 1398 2;
VAL_ 3221225472 KBI_Service_km 1022 "Init" 1023 "Fehler" ;
VAL_ 3221225472 KBI_Service_Zeit 2046 "Init" 2047 "Fehler" ;
VAL_ 3221225472 KBI_Service_Typ 0 "Init" 1 "naechste_Wartung_ist_Zwischenwartung" 2 "naechste_Wartung_ist_Hauptwartung" 3 "naechste_Wartung_ist_Oelservice" ;
VAL_ 3221225472 Mo_HVEM_HV_Abschaltanf 0 "keine_Anforderung" 1 "Abschaltung_HV_Verbraucher_gefordert" ;
VAL_ 3221225472 MO_HVEM_HV_Maxleistung 254 "Init" 255 "Fehler" ;
VAL_ 3221225472 HVEM_Istleistung_Nebenverbrauch 251 "reserviert" 252 "reserviert" 253 "reserviert" 254 "Init" 255 "Fehler" ;
VAL_ 3221225472 SVB_IVB_FS_Fond 0 "SG nicht verbaut" 1 "SG verbaut" ;
VAL_ 3221225472 SVB_IVB_FS 0 "SG nicht verbaut" 1 "SG verbaut" ;
VAL_ 3221225472 SVB_IVB_BFS_Fond 0 "SG nicht verbaut" 1 "SG verbaut" ;
VAL_ 3221225472 SVB_IVB_BFS 0 "SG nicht verbaut" 1 "SG verbaut" ;
VAL_ 3221225472 SVB_KameraLow_FLA 1 "SG verbaut" 0 "SG nicht verbaut" ;
VAL_ 3221225472 AWV_Halten 0 "keine_Anforderung" 1 "Anforderung_das_Fzg_im_Stillstand_zu_halten" ;
VAL_ 1728 NMH_GW_Start_1 1 "Zustand Start (<--Sleep)" ;
VAL_ 1728 NMH_GW_Start_2 1 "Zustand Start (<--Prepare to Sleep)" ;
VAL_ 1728 NMH_GW_Normal_Mode_1 1 "Zustand Normal Mode (<-- Start)" ;
VAL_ 1728 NMH_GW_Normal_Mode_2 1 "Zustand Normal Mode (<-- Ready to Sleep)" ;
VAL_ 1728 NMH_GW_Per_WakeUp 0 "Wenn_FunktionsWakeup" 1 "CAN_Wakeup__Weckendes_CAN_Segment_siehe_NMH_GW_WakeUp_CAN_Bus" 2 "P_WakeUp_Ursache_unbekannt" 3 "Klemme_15HW__falls_vorhanden" 4 "MOST_Wakeup" 5 "LIN_Wakeup" 6 "KL30_Reset" ;
VAL_ 1728 NMH_GW_Fkt_WakeUp 0 "Wenn_Peripherie_Wakeup" 1 "Funktionswakeup_EM" 2 "Car_Wakeup_empfangen" 3 "VNSM_VehicleNetworkStateManager" 4 "Alarm_RTC__Wecken_weil_Weckzeit_abgelaufen" 5 "Wecken_durch_Diagnose" ;
VAL_ 1728 NMH_GW_NM_aktiv_Klemme_15 1 "Klemme 15 EIN" ;
VAL_ 1728 NMH_GW_NM_aktiv_Diagnose 1 "Diagnose bei Kl 15 aus" ;
VAL_ 1728 NMH_GW_NM_aktiv_Start 1 "Zustand 'START' (NM-high)" ;
VAL_ 1728 NMH_GW_NM_aktiv_BDM 1 "BDM-Kommunikation" ;
VAL_ 1728 NMH_GW_NM_aktiv_Warnblinken 1 "Warnblinken aktiv" ;
VAL_ 1728 NMH_GW_NM_aktiv_ESP 1 "ESP aktiv (Wakeup/Sleep-Konzept)" ;
VAL_ 1728 NMH_GW_NM_aktiv_EMP 1 "EMP_aktiv" ;
VAL_ 1728 NMH_GW_Abschaltstufe_3 1 "BEM aufgrund Abschaltstufe 3 aktiv" ;
VAL_ 1728 NMH_GW_SG_Fehlerdauer 1 "BEM aufgrund Steuergeraetefehlerdauer aktiv" ;
VAL_ 1728 NMH_GW_STH_Wakeup 1 "BEM aktiv aufgrund Standheizungswakeup" ;
VAL_ 1728 NMH_GW_NL_Diagnose 0 "keine_Diagnose_aktiv" 1 "Diagnose_war_lokal_aktiv" ;
VAL_ 1728 NM_GW_Signalfehler 1 "Aktiver_Signalfehler_eingetragen" ;
VAL_ 1728 NMH_GW_TimeOut_Fehler 1 "Aktiver Timeout Fehlerspeichereintrag  " ;
VAL_ 1728 NMH_GW_CAN_Diag_deaktiv 1 "CAN Bus bezogene Eigendiagnose deaktiv" ;
VAL_ 1728 NMH_GW_KompSchutz 0 "inaktiv" 1 "aktiv" ;
VAL_ 1728 NMH_GW_Mute_Mode 1 "MuteMode aktiv" ;
VAL_ 1728 NMH_GW_Transport_Mode 1 "Transportmodus aktiv" ;
VAL_ 1728 NMH_GW_Abschaltstufe_aktiv 1 "Abschaltstufe aktiv" ;
VAL_ 1728 NMH_GW_Eindraht_Fehler 1 "Eindrahtbetrieb erkannt" ;
VAL_ 1728 NMH_GW_ACAN 1 "ACAN aktiv (Wakeup/Sleep-Konzept)" ;
VAL_ 1728 NMH_GW_KombiCAN 1 "KombiCAN aktiv (Wakeup/Sleep-Konzept)" ;
VAL_ 1728 NMH_GW_KomfortCAN 1 "KomfortCAN aktiv (Wakeup/Sleep-Konzept)" ;
VAL_ 1728 NMH_GW_Infotainment 1 "Infotainment aktiv (CAN oder MOST), Wakeup/Sleep-Konzept" ;
VAL_ 1728 NMH_GW_Fahrwerk 1 "BUS_Fahrwerk_aktiv (Wakeup/Sleep-Konzept)" ;
VAL_ 1728 NMH_GW_WakeUp_CAN_Bus 0 "Nicht zutreffend (kein CAN-Wakeup bzw. CarWakeup)" 1 "Antriebs-CAN" 2 "Kombi-CAN" 3 "Komfort-CAN" 4 "Infotainment-CAN (wenn verfuegbar)" 5 "Fahrwerks-CAN" 6 "Diagnose-CAN" ;
VAL_ 1327 OBD_Fehler_Laengsbeschleunigung 0 "kein Fehler" 1 "Fehler Spannungsversorgung" 2 "Interner Fehler" 3 "Fehler Sensor out of range" 4 "Fehler CAN Bus monitoring" 5 "Initialisierung Sensorcluster fehlgeschlagen" 6 "Offset Sensorcluster zu groß" 7 "Fehler Überwachung Plausibilität gegen Modell" 8 "Fehler Sensortausch ohne Anlernen" 9 "frei" 10 "frei" 11 "frei" 12 "frei" 13 "frei" 14 "frei" 15 "frei" ;
VAL_ 1327 OBD_Fehler_Vordrucksensor 0 "kein_Fehler" 1 "Fehler_Plausibilitaet_gegen_BLS" 2 "Fehler_Plausibilitaet_Vordrucksensor" 3 "elektrischer_Fehler" ;
VAL_ 1381 HVLM_IstSpannung_HV 1022 "Init" 1023 "Fehler" ;
VAL_ 1381 HVLM_HV_Abstellzeit 254 "Init" 255 "Fehler" ;
VAL_ 1381 HVLM_Zustand_LED 0 "Farbe_1__aus" 1 "Farbe_2__weiss" 2 "Farbe_3__gelb" 3 "Farbe_4__gruen" 4 "Farbe_5__rot" 5 "Farbe_3_pulsierend" 6 "Farbe_4_pulsierend" 7 "Farbe_5_pulsierend" 8 "Farbe_4_5_pulsierend" 14 "Init" 15 "Fehler" ;
VAL_ 1381 HVLM_MaxLadezeitDCHV 254 "Init" 255 "Fehler" ;
VAL_ 1381 HVLM_MaxStrom_Netz 126 "Init" 127 "Fehler" ;
VAL_ 1381 HVLM_LG_Sollmodus 0 "Standby" 1 "Netzladung" ;
VAL_ 1381 HVLM_FreigabeTankdeckel 0 "keine_Freigabe" 1 "Freigabe" 2 "Init" 3 "Fehler" ;
VAL_ 1381 HVLM_Stecker_Verriegeln 0 "Stecker_entriegeln" 1 "Stecker_verriegeln" 2 "Init" 3 "keine_Anforderung" ;
VAL_ 1381 HVLM_Start_Spannungsmessung_DCLS 0 "inaktiv" 1 "DCLS_mit_Diode_Start_Messung" 2 "DCLS_ohne_Diode_Start_Messung" 3 "reserve" ;
VAL_ 1381 HVLM_Taster_Profil_Laden_Anf 0 "nicht_aktiv" 1 "aktiv" 2 "Init" 3 "Fehler" ;
VAL_ 1381 HVLM_Taster_Sofort_Laden_Anf 0 "nicht_aktiv" 1 "aktiv" 2 "Init" 3 "Fehler" ;
VAL_ 1381 HVLM_FreigabeKlimatisierung 0 "keine_Freigabe" 1 "Freigabe" 2 "Init" 3 "Fehler" ;
VAL_ 1381 HVLM_Ladetexte 0 "Keine_Anzeige" 1 "AC_Laden_nicht_moeglich" 2 "DC_Laden_nicht_moeglich" 3 "AC_und_DC_Laden_nicht_moeglich" ;
VAL_ 1534 KBI_Set_Timer_MUX 0 "leer" 1 "Timer_1" 2 "Timer_2" 3 "Timer_3" 4 "Timer_4" 5 "reserviert" 6 "reserviert" 7 "reserviert" ;
VAL_ 1534 KBI_Set_Timer_1_Jahr 126 "Init" 127 "reserviert" ;
VAL_ 1534 KBI_Set_Timer_2_Jahr 126 "Init" 127 "reserviert" ;
VAL_ 1534 KBI_Set_Timer_3_Jahr 126 "Init" 127 "reserviert" ;
VAL_ 1534 KBI_Set_Timer_4_Jahr 126 "Init" 127 "reserviert" ;
VAL_ 1534 KBI_Set_Timer_1_Minute 60 "reserviert" 61 "reserviert" 62 "Init" 63 "Fehler" ;
VAL_ 1534 KBI_Set_Timer_2_Minute 60 "reserviert" 61 "reserviert" 62 "Init" 63 "Fehler" ;
VAL_ 1534 KBI_Set_Timer_3_Minute 60 "reserviert" 61 "reserviert" 62 "Init" 63 "Fehler" ;
VAL_ 1534 KBI_Set_Timer_4_Minute 60 "reserviert" 61 "reserviert" 62 "Init" 63 "Fehler" ;
VAL_ 1534 KBI_Set_Timer_1_Monat 0 "Init" 14 "reserviert" 15 "Fehler" ;
VAL_ 1534 KBI_Set_Timer_2_Monat 0 "Init" 14 "reserviert" 15 "Fehler" ;
VAL_ 1534 KBI_Set_Timer_3_Monat 0 "Init" 14 "reserviert" 15 "Fehler" ;
VAL_ 1534 KBI_Set_Timer_4_Monat 0 "Init" 14 "reserviert" 15 "Fehler" ;
VAL_ 1534 KBI_Set_Timer_1_Stunde 24 "reserviert" 25 "reserviert" 26 "reserviert" 27 "reserviert" 28 "reserviert" 29 "reserviert" 30 "Init" 31 "Fehler" ;
VAL_ 1534 KBI_Set_Timer_2_Stunde 24 "reserviert" 25 "reserviert" 26 "reserviert" 27 "reserviert" 28 "reserviert" 29 "reserviert" 30 "Init" 31 "Fehler" ;
VAL_ 1534 KBI_Set_Timer_3_Stunde 24 "reserviert" 25 "reserviert" 26 "reserviert" 27 "reserviert" 28 "reserviert" 29 "reserviert" 30 "Init" 31 "Fehler" ;
VAL_ 1534 KBI_Set_Timer_4_Stunde 24 "reserviert" 25 "reserviert" 26 "reserviert" 27 "reserviert" 28 "reserviert" 29 "reserviert" 30 "Init" 31 "Fehler" ;
VAL_ 1534 KBI_Set_Timer_1_Tag 0 "Init" ;
VAL_ 1534 KBI_Set_Timer_2_Tag 0 "Init" ;
VAL_ 1534 KBI_Set_Timer_3_Tag 0 "Init" ;
VAL_ 1534 KBI_Set_Timer_4_Tag 0 "Init" ;
VAL_ 1534 KBI_Set_Timer_1_Laden 0 "Timer_nicht_aktiv" 1 "Timer_aktiv" ;
VAL_ 1534 KBI_Set_Timer_2_Laden 0 "Timer_nicht_aktiv" 1 "Timer_aktiv" ;
VAL_ 1534 KBI_Set_Timer_3_Laden 0 "Timer_nicht_aktiv" 1 "Timer_aktiv" ;
VAL_ 1534 KBI_Set_Timer_4_Laden 0 "Timer_nicht_aktiv" 1 "Timer_aktiv" ;
VAL_ 1534 KBI_Set_Timer_1_Vorklima 0 "Timer_nicht_aktiv" 1 "Timer_aktiv" ;
VAL_ 1534 KBI_Set_Timer_2_Vorklima 0 "Timer_nicht_aktiv" 1 "Timer_aktiv" ;
VAL_ 1534 KBI_Set_Timer_3_Vorklima 0 "Timer_nicht_aktiv" 1 "Timer_aktiv" ;
VAL_ 1534 KBI_Set_Timer_4_Vorklima 0 "Timer_nicht_aktiv" 1 "Timer_aktiv" ;
VAL_ 1534 KBI_Set_Timer_1_Zyklus_Mo 0 "Timer_am_Wochentag_nicht_aktiv" 1 "Timer_am_Wochentag_aktiv" ;
VAL_ 1534 KBI_Set_Timer_2_Zyklus_Mo 0 "Timer_am_Wochentag_nicht_aktiv" 1 "Timer_am_Wochentag_aktiv" ;
VAL_ 1534 KBI_Set_Timer_3_Zyklus_Mo 0 "Timer_am_Wochentag_nicht_aktiv" 1 "Timer_am_Wochentag_aktiv" ;
VAL_ 1534 KBI_Set_Timer_4_Zyklus_Mo 0 "Timer_am_Wochentag_nicht_aktiv" 1 "Timer_am_Wochentag_aktiv" ;
VAL_ 1534 KBI_Set_Timer_1_Zyklus_Di 0 "Timer_am_Wochentag_nicht_aktiv" 1 "Timer_am_Wochentag_aktiv" ;
VAL_ 1534 KBI_Set_Timer_2_Zyklus_Di 0 "Timer_am_Wochentag_nicht_aktiv" 1 "Timer_am_Wochentag_aktiv" ;
VAL_ 1534 KBI_Set_Timer_3_Zyklus_Di 0 "Timer_am_Wochentag_nicht_aktiv" 1 "Timer_am_Wochentag_aktiv" ;
VAL_ 1534 KBI_Set_Timer_4_Zyklus_Di 0 "Timer_am_Wochentag_nicht_aktiv" 1 "Timer_am_Wochentag_aktiv" ;
VAL_ 1534 KBI_Set_Timer_1_Zyklus_Mi 0 "Timer_am_Wochentag_nicht_aktiv" 1 "Timer_am_Wochentag_aktiv" ;
VAL_ 1534 KBI_Set_Timer_2_Zyklus_Mi 0 "Timer_am_Wochentag_nicht_aktiv" 1 "Timer_am_Wochentag_aktiv" ;
VAL_ 1534 KBI_Set_Timer_3_Zyklus_Mi 0 "Timer_am_Wochentag_nicht_aktiv" 1 "Timer_am_Wochentag_aktiv" ;
VAL_ 1534 KBI_Set_Timer_4_Zyklus_Mi 0 "Timer_am_Wochentag_nicht_aktiv" 1 "Timer_am_Wochentag_aktiv" ;
VAL_ 1534 KBI_Set_Timer_1_Zyklus_Do 0 "Timer_am_Wochentag_nicht_aktiv" 1 "Timer_am_Wochentag_aktiv" ;
VAL_ 1534 KBI_Set_Timer_2_Zyklus_Do 0 "Timer_am_Wochentag_nicht_aktiv" 1 "Timer_am_Wochentag_aktiv" ;
VAL_ 1534 KBI_Set_Timer_3_Zyklus_Do 0 "Timer_am_Wochentag_nicht_aktiv" 1 "Timer_am_Wochentag_aktiv" ;
VAL_ 1534 KBI_Set_Timer_4_Zyklus_Do 0 "Timer_am_Wochentag_nicht_aktiv" 1 "Timer_am_Wochentag_aktiv" ;
VAL_ 1534 KBI_Set_Timer_1_Zyklus_Fr 0 "Timer_am_Wochentag_nicht_aktiv" 1 "Timer_am_Wochentag_aktiv" ;
VAL_ 1534 KBI_Set_Timer_2_Zyklus_Fr 0 "Timer_am_Wochentag_nicht_aktiv" 1 "Timer_am_Wochentag_aktiv" ;
VAL_ 1534 KBI_Set_Timer_3_Zyklus_Fr 0 "Timer_am_Wochentag_nicht_aktiv" 1 "Timer_am_Wochentag_aktiv" ;
VAL_ 1534 KBI_Set_Timer_4_Zyklus_Fr 0 "Timer_am_Wochentag_nicht_aktiv" 1 "Timer_am_Wochentag_aktiv" ;
VAL_ 1534 KBI_Set_Timer_1_Zyklus_Sa 0 "Timer_am_Wochentag_nicht_aktiv" 1 "Timer_am_Wochentag_aktiv" ;
VAL_ 1534 KBI_Set_Timer_2_Zyklus_Sa 0 "Timer_am_Wochentag_nicht_aktiv" 1 "Timer_am_Wochentag_aktiv" ;
VAL_ 1534 KBI_Set_Timer_3_Zyklus_Sa 0 "Timer_am_Wochentag_nicht_aktiv" 1 "Timer_am_Wochentag_aktiv" ;
VAL_ 1534 KBI_Set_Timer_4_Zyklus_Sa 0 "Timer_am_Wochentag_nicht_aktiv" 1 "Timer_am_Wochentag_aktiv" ;
VAL_ 1534 KBI_Set_Timer_1_Zyklus_So 0 "Timer_am_Wochentag_nicht_aktiv" 1 "Timer_am_Wochentag_aktiv" ;
VAL_ 1534 KBI_Set_Timer_2_Zyklus_So 0 "Timer_am_Wochentag_nicht_aktiv" 1 "Timer_am_Wochentag_aktiv" ;
VAL_ 1534 KBI_Set_Timer_3_Zyklus_So 0 "Timer_am_Wochentag_nicht_aktiv" 1 "Timer_am_Wochentag_aktiv" ;
VAL_ 1534 KBI_Set_Timer_4_Zyklus_So 0 "Timer_am_Wochentag_nicht_aktiv" 1 "Timer_am_Wochentag_aktiv" ;
VAL_ 1534 KBI_Set_Timer_1_Zyklus_WH 0 "zyklisch" 1 "einmalig" ;
VAL_ 1534 KBI_Set_Timer_2_Zyklus_WH 0 "zyklisch" 1 "einmalig" ;
VAL_ 1534 KBI_Set_Timer_3_Zyklus_WH 0 "zyklisch" 1 "einmalig" ;
VAL_ 1534 KBI_Set_Timer_4_Zyklus_WH 0 "zyklisch" 1 "einmalig" ;
VAL_ 1534 KBI_MOD_Privatsphaere 0 "Init" 1 "MOD verfügbar" 2 "MOD nicht verfügbar" 3 "reserviert" ;
VAL_ 1534 KBI_STH_Status 0 "keine EIN/AUS-Anforderung" 1 "Standheizung EIN" 2 "Standheizung AUS" 3 "reserviert" ;
VAL_ 1631 MO_Energieinhalt_BMS 4094 "Init" 4095 "Fehler" ;
VAL_ 1398 MOD_Privatsphaere 0 "MOD_nicht_konfiguriert" 1 "MOD_konfiguriert" ;
VAL_ 1398 MOD_Set_Timer_5_Jahr 126 "Init" 127 "reserviert" ;
VAL_ 1398 MOD_Set_Timer_6_Jahr 126 "Init" 127 "reserviert" ;
VAL_ 1398 MOD_Set_Timer_5_Minute 60 "reserviert" 61 "reserviert" 62 "Init" 63 "Fehler" ;
VAL_ 1398 MOD_Set_Timer_6_Minute 60 "reserviert" 61 "reserviert" 62 "Init" 63 "Fehler" ;
VAL_ 1398 MOD_Set_Timer_5_Monat 0 "Init" 14 "reserviert" 15 "Fehler" ;
VAL_ 1398 MOD_Set_Timer_6_Monat 0 "Init" 14 "reserviert" 15 "Fehler" ;
VAL_ 1398 MOD_Set_Timer_5_Stunde 24 "reserviert" 25 "reserviert" 26 "reserviert" 27 "reserviert" 28 "reserviert" 29 "reserviert" 30 "Init" 31 "Fehler" ;
VAL_ 1398 MOD_Set_Timer_6_Stunde 24 "reserviert" 25 "reserviert" 26 "reserviert" 27 "reserviert" 28 "reserviert" 29 "reserviert" 30 "Init" 31 "Fehler" ;
VAL_ 1398 MOD_Set_Timer_5_Tag 0 "Init" ;
VAL_ 1398 MOD_Set_Timer_6_Tag 0 "Init" ;
VAL_ 1398 MOD_Set_Timer_5_Vorklima 0 "Timer_nicht_aktiv" 1 "Timer_aktiv" ;
VAL_ 1398 MOD_Set_Timer_6_Vorklima 0 "Timer_nicht_aktiv" 1 "Timer_aktiv" ;
VAL_ 1398 MOD_Set_Timerladen 0 "Init, keine Aktion" 1 "Timerladen" ;
VAL_ 1398 MOD_Set_Sofortladen 0 "Init, keine Aktion" 1 "Sofortladen" ;
VAL_ 1398 MOD_Set_Timer_4_Jahr 126 "Init" 127 "reserviert" ;
VAL_ 1398 MOD_Set_Timer_4_Minute 60 "reserviert" 61 "reserviert" 62 "Init" 63 "Fehler" ;
VAL_ 1398 MOD_Set_Timer_4_Monat 0 "Init" 14 "reserviert" 15 "Fehler" ;
VAL_ 1398 MOD_Set_Timer_4_Stunde 24 "reserviert" 25 "reserviert" 26 "reserviert" 27 "reserviert" 28 "reserviert" 29 "reserviert" 30 "Init" 31 "Fehler" ;
VAL_ 1398 MOD_Set_Timer_4_Tag 0 "Init" ;
VAL_ 1398 MOD_Set_Timer_4_Laden 0 "Timer_nicht_aktiv" 1 "Timer_aktiv" ;
VAL_ 1398 MOD_Set_Timer_4_Vorklima 0 "Timer_nicht_aktiv" 1 "Timer_aktiv" ;
VAL_ 1398 MOD_Set_Timer_4_Zyklus_Mo 0 "Timer_am_Wochentag_nicht_aktiv" 1 "Timer_am_Wochentag_aktiv" ;
VAL_ 1398 MOD_Set_Timer_4_Zyklus_Di 0 "Timer_am_Wochentag_nicht_aktiv" 1 "Timer_am_Wochentag_aktiv" ;
VAL_ 1398 MOD_Set_Timer_4_Zyklus_Mi 0 "Timer_am_Wochentag_nicht_aktiv" 1 "Timer_am_Wochentag_aktiv" ;
VAL_ 1398 MOD_Set_Timer_4_Zyklus_Do 0 "Timer_am_Wochentag_nicht_aktiv" 1 "Timer_am_Wochentag_aktiv" ;
VAL_ 1398 MOD_Set_Timer_4_Zyklus_Fr 0 "Timer_am_Wochentag_nicht_aktiv" 1 "Timer_am_Wochentag_aktiv" ;
VAL_ 1398 MOD_Set_Timer_4_Zyklus_Sa 0 "Timer_am_Wochentag_nicht_aktiv" 1 "Timer_am_Wochentag_aktiv" ;
VAL_ 1398 MOD_Set_Timer_4_Zyklus_So 0 "Timer_am_Wochentag_nicht_aktiv" 1 "Timer_am_Wochentag_aktiv" ;
VAL_ 1398 MOD_Set_Timer_4_Zyklus_WH 0 "zyklisch" 1 "einmalig" ;
VAL_ 1398 MOD_Set_Timer_1_Jahr 126 "Init" 127 "reserviert" ;
VAL_ 1398 MOD_Set_Timer_2_Jahr 126 "Init" 127 "reserviert" ;
VAL_ 1398 MOD_Set_Timer_3_Jahr 126 "Init" 127 "reserviert" ;
VAL_ 1398 MOD_Set_Timer_1_Minute 60 "reserviert" 61 "reserviert" 62 "Init" 63 "Fehler" ;
VAL_ 1398 MOD_Set_Timer_2_Minute 60 "reserviert" 61 "reserviert" 62 "Init" 63 "Fehler" ;
VAL_ 1398 MOD_Set_Timer_3_Minute 60 "reserviert" 61 "reserviert" 62 "Init" 63 "Fehler" ;
VAL_ 1398 MOD_Set_Timer_1_Monat 0 "Init" 14 "reserviert" 15 "Fehler" ;
VAL_ 1398 MOD_Set_Timer_2_Monat 0 "Init" 14 "reserviert" 15 "Fehler" ;
VAL_ 1398 MOD_Set_Timer_3_Monat 0 "Init" 14 "reserviert" 15 "Fehler" ;
VAL_ 1398 MOD_Set_Timer_1_Stunde 24 "reserviert" 25 "reserviert" 26 "reserviert" 27 "reserviert" 28 "reserviert" 29 "reserviert" 30 "Init" 31 "Fehler" ;
VAL_ 1398 MOD_Set_Timer_2_Stunde 24 "reserviert" 25 "reserviert" 26 "reserviert" 27 "reserviert" 28 "reserviert" 29 "reserviert" 30 "Init" 31 "Fehler" ;
VAL_ 1398 MOD_Set_Timer_3_Stunde 24 "reserviert" 25 "reserviert" 26 "reserviert" 27 "reserviert" 28 "reserviert" 29 "reserviert" 30 "Init" 31 "Fehler" ;
VAL_ 1398 MOD_Set_Timer_1_Tag 0 "Init" ;
VAL_ 1398 MOD_Set_Timer_2_Tag 0 "Init" ;
VAL_ 1398 MOD_Set_Timer_3_Tag 0 "Init" ;
VAL_ 1398 MOD_Set_Timer_1_Laden 0 "Timer_nicht_aktiv" 1 "Timer_aktiv" ;
VAL_ 1398 MOD_Set_Timer_2_Laden 0 "Timer_nicht_aktiv" 1 "Timer_aktiv" ;
VAL_ 1398 MOD_Set_Timer_3_Laden 0 "Timer_nicht_aktiv" 1 "Timer_aktiv" ;
VAL_ 1398 MOD_Set_Timer_1_Vorklima 0 "Timer_nicht_aktiv" 1 "Timer_aktiv" ;
VAL_ 1398 MOD_Set_Timer_2_Vorklima 0 "Timer_nicht_aktiv" 1 "Timer_aktiv" ;
VAL_ 1398 MOD_Set_Timer_3_Vorklima 0 "Timer_nicht_aktiv" 1 "Timer_aktiv" ;
VAL_ 1398 MOD_Set_Timer_1_Zyklus_Mo 0 "Timer_am_Wochentag_nicht_aktiv" 1 "Timer_am_Wochentag_aktiv" ;
VAL_ 1398 MOD_Set_Timer_2_Zyklus_Mo 0 "Timer_am_Wochentag_nicht_aktiv" 1 "Timer_am_Wochentag_aktiv" ;
VAL_ 1398 MOD_Set_Timer_3_Zyklus_Mo 0 "Timer_am_Wochentag_nicht_aktiv" 1 "Timer_am_Wochentag_aktiv" ;
VAL_ 1398 MOD_Set_Timer_1_Zyklus_Di 0 "Timer_am_Wochentag_nicht_aktiv" 1 "Timer_am_Wochentag_aktiv" ;
VAL_ 1398 MOD_Set_Timer_2_Zyklus_Di 0 "Timer_am_Wochentag_nicht_aktiv" 1 "Timer_am_Wochentag_aktiv" ;
VAL_ 1398 MOD_Set_Timer_3_Zyklus_Di 0 "Timer_am_Wochentag_nicht_aktiv" 1 "Timer_am_Wochentag_aktiv" ;
VAL_ 1398 MOD_Set_Timer_1_Zyklus_Mi 0 "Timer_am_Wochentag_nicht_aktiv" 1 "Timer_am_Wochentag_aktiv" ;
VAL_ 1398 MOD_Set_Timer_2_Zyklus_Mi 0 "Timer_am_Wochentag_nicht_aktiv" 1 "Timer_am_Wochentag_aktiv" ;
VAL_ 1398 MOD_Set_Timer_3_Zyklus_Mi 0 "Timer_am_Wochentag_nicht_aktiv" 1 "Timer_am_Wochentag_aktiv" ;
VAL_ 1398 MOD_Set_Timer_1_Zyklus_Do 0 "Timer_am_Wochentag_nicht_aktiv" 1 "Timer_am_Wochentag_aktiv" ;
VAL_ 1398 MOD_Set_Timer_2_Zyklus_Do 0 "Timer_am_Wochentag_nicht_aktiv" 1 "Timer_am_Wochentag_aktiv" ;
VAL_ 1398 MOD_Set_Timer_3_Zyklus_Do 0 "Timer_am_Wochentag_nicht_aktiv" 1 "Timer_am_Wochentag_aktiv" ;
VAL_ 1398 MOD_Set_Timer_1_Zyklus_Fr 0 "Timer_am_Wochentag_nicht_aktiv" 1 "Timer_am_Wochentag_aktiv" ;
VAL_ 1398 MOD_Set_Timer_2_Zyklus_Fr 0 "Timer_am_Wochentag_nicht_aktiv" 1 "Timer_am_Wochentag_aktiv" ;
VAL_ 1398 MOD_Set_Timer_3_Zyklus_Fr 0 "Timer_am_Wochentag_nicht_aktiv" 1 "Timer_am_Wochentag_aktiv" ;
VAL_ 1398 MOD_Set_Timer_1_Zyklus_Sa 0 "Timer_am_Wochentag_nicht_aktiv" 1 "Timer_am_Wochentag_aktiv" ;
VAL_ 1398 MOD_Set_Timer_2_Zyklus_Sa 0 "Timer_am_Wochentag_nicht_aktiv" 1 "Timer_am_Wochentag_aktiv" ;
VAL_ 1398 MOD_Set_Timer_3_Zyklus_Sa 0 "Timer_am_Wochentag_nicht_aktiv" 1 "Timer_am_Wochentag_aktiv" ;
VAL_ 1398 MOD_Set_Timer_1_Zyklus_So 0 "Timer_am_Wochentag_nicht_aktiv" 1 "Timer_am_Wochentag_aktiv" ;
VAL_ 1398 MOD_Set_Timer_2_Zyklus_So 0 "Timer_am_Wochentag_nicht_aktiv" 1 "Timer_am_Wochentag_aktiv" ;
VAL_ 1398 MOD_Set_Timer_3_Zyklus_So 0 "Timer_am_Wochentag_nicht_aktiv" 1 "Timer_am_Wochentag_aktiv" ;
VAL_ 1398 MOD_Set_Timer_1_Zyklus_WH 0 "zyklisch" 1 "einmalig" ;
VAL_ 1398 MOD_Set_Timer_2_Zyklus_WH 0 "zyklisch" 1 "einmalig" ;
VAL_ 1398 MOD_Set_Timer_MUX 0 "leer" 1 "Abfahrtstimer_1" 2 "Abfahrtstimer_2" 3 "Abfahrtstimer_3" 4 "Klimatimer_1" 5 "Klimatimer_2" 6 "reserviert" 7 "reserviert" ;
VAL_ 1398 MOD_Set_Timer_3_Zyklus_WH 0 "zyklisch" 1 "einmalig" ;
VAL_ 1398 MOD_Set_Nachtstrom_X_Std_Anf 62 "Init" 63 "ungueltig" ;
VAL_ 1398 MOD_Set_Nachtstrom_Prof 0 "keine_Aktion" 1 "Profil_1_setzen" 2 "Profil_2_setzen" 3 "Profil_3_setzen" ;
VAL_ 1398 MOD_Set_Nachtstrom_X_Std_End 62 "Init" 63 "ungueltig" ;
VAL_ 1398 MOD_Set_Nachtstrom_Akt_Prof 0 "kein_Profil_gesetzt" 1 "Profil_1_aktiv" 2 "Profil_2_aktiv" 3 "Profil_3_aktiv" ;
VAL_ 1398 MOD_Set_Abbruch_Klima 0 "keine_Aktion" 1 "Abbruch_Standkl_Standh" ;
VAL_ 1398 MOD_Set_Sofortstart_Klima 0 "keine_Aktion" 1 "Start_Standkl_Standh" ;
VAL_ 1398 MOD_Anf_Spiegel_anklappen 0 "keine_Aktion" 1 "Anforderung_Spiegel_anklappen" ;
VAL_ 1398 MOD_Anf_ZV 0 "keine_Aktion" 1 "Anforderung_alle_Tueren_verriegeln" 2 "Anforderung_alle_Tueren_entriegeln" 3 "reserviert" ;
VAL_ 1397 HVLM_Status_naechster_Ladetimer 3 "Abfahrtstimer 3  ist nächster Ladetimer" 0 "Init, kein nächster Ladetimer" 1 "Abfahrtstimer 1 ist nächster Ladetimer" 2 "Abfahrtstimer 2  ist nächster Ladetimer" ;
VAL_ 1397 HVLM_Status_naechster_Klimatimer 0 "Init, kein nächster Klimatimer" 1 "Klimatimer 1 ist nächster Timer" 2 "reserviert" 3 "reserviert" ;
VAL_ 1397 HVLM_Status_Timer_7_Laden 0 "Timer_nicht_aktiv" 1 "Timer_aktiv" ;
VAL_ 1397 HVLM_Ladetexte 0 "Keine_Anzeige" 1 "AC_Laden_nicht_moeglich" 2 "DC_Laden_nicht_moeglich" 3 "AC_und_DC_Laden_nicht_moeglich" ;
VAL_ 1397 HVLM_Status_Timer_4_Jahr 126 "Init" 127 "reserviert" ;
VAL_ 1397 HVLM_Status_Timer_4_Minute 60 "reserviert" 61 "reserviert" 62 "Init" 63 "Fehler" ;
VAL_ 1397 HVLM_Status_Timer_4_Monat 0 "Init" 14 "reserviert" 15 "Fehler" ;
VAL_ 1397 HVLM_Status_Timer_4_Stunde 24 "reserviert" 25 "reserviert" 26 "reserviert" 27 "reserviert" 28 "reserviert" 29 "reserviert" 30 "Init" 31 "Fehler" ;
VAL_ 1397 HVLM_Status_Timer_4_Tag 0 "Init" ;
VAL_ 1397 HVLM_Status_Timer_4_Laden 0 "Timer_nicht_aktiv" 1 "Timer_aktiv" ;
VAL_ 1397 HVLM_Status_Timer_4_Vorklima 0 "Timer_nicht_aktiv" 1 "Timer_aktiv" ;
VAL_ 1397 HVLM_Status_Timer_4_Zyklus_Mo 0 "Timer_am_Wochentag_nicht_aktiv" 1 "Timer_am_Wochentag_aktiv" ;
VAL_ 1397 HVLM_Status_Timer_2_Vorklima 0 "Timer_nicht_aktiv" 1 "Timer_aktiv" ;
VAL_ 1397 HVLM_Status_Timer_3_Vorklima 0 "Timer_nicht_aktiv" 1 "Timer_aktiv" ;
VAL_ 1397 HVLM_Status_Timer_1_Zyklus_Mo 0 "Timer_am_Wochentag_nicht_aktiv" 1 "Timer_am_Wochentag_aktiv" ;
VAL_ 1397 HVLM_Status_Timer_2_Zyklus_Mo 0 "Timer_am_Wochentag_nicht_aktiv" 1 "Timer_am_Wochentag_aktiv" ;
VAL_ 1397 HVLM_Status_Timer_3_Zyklus_Mo 0 "Timer_am_Wochentag_nicht_aktiv" 1 "Timer_am_Wochentag_aktiv" ;
VAL_ 1397 HVLM_Status_Timer_1_Zyklus_Di 0 "Timer_am_Wochentag_nicht_aktiv" 1 "Timer_am_Wochentag_aktiv" ;
VAL_ 1397 HVLM_Status_Timer_2_Zyklus_Di 0 "Timer_am_Wochentag_nicht_aktiv" 1 "Timer_am_Wochentag_aktiv" ;
VAL_ 1397 HVLM_Status_Timer_3_Zyklus_Di 0 "Timer_am_Wochentag_nicht_aktiv" 1 "Timer_am_Wochentag_aktiv" ;
VAL_ 1397 HVLM_Status_Timer_1_Zyklus_Mi 0 "Timer_am_Wochentag_nicht_aktiv" 1 "Timer_am_Wochentag_aktiv" ;
VAL_ 1397 HVLM_Status_Timer_2_Zyklus_Mi 0 "Timer_am_Wochentag_nicht_aktiv" 1 "Timer_am_Wochentag_aktiv" ;
VAL_ 1397 HVLM_Status_Timer_3_Zyklus_Mi 0 "Timer_am_Wochentag_nicht_aktiv" 1 "Timer_am_Wochentag_aktiv" ;
VAL_ 1397 HVLM_Status_Timer_1_Zyklus_Do 0 "Timer_am_Wochentag_nicht_aktiv" 1 "Timer_am_Wochentag_aktiv" ;
VAL_ 1397 HVLM_Status_Timer_2_Zyklus_Do 0 "Timer_am_Wochentag_nicht_aktiv" 1 "Timer_am_Wochentag_aktiv" ;
VAL_ 1397 HVLM_Status_Timer_3_Zyklus_Do 0 "Timer_am_Wochentag_nicht_aktiv" 1 "Timer_am_Wochentag_aktiv" ;
VAL_ 1397 HVLM_Status_Timer_1_Zyklus_Fr 0 "Timer_am_Wochentag_nicht_aktiv" 1 "Timer_am_Wochentag_aktiv" ;
VAL_ 1397 HVLM_Status_Timer_2_Zyklus_Fr 0 "Timer_am_Wochentag_nicht_aktiv" 1 "Timer_am_Wochentag_aktiv" ;
VAL_ 1397 HVLM_Status_Timer_3_Zyklus_Fr 0 "Timer_am_Wochentag_nicht_aktiv" 1 "Timer_am_Wochentag_aktiv" ;
VAL_ 1397 HVLM_Status_Timer_1_Zyklus_Sa 0 "Timer_am_Wochentag_nicht_aktiv" 1 "Timer_am_Wochentag_aktiv" ;
VAL_ 1397 HVLM_Status_Timer_2_Zyklus_Sa 0 "Timer_am_Wochentag_nicht_aktiv" 1 "Timer_am_Wochentag_aktiv" ;
VAL_ 1397 HVLM_Status_Timer_3_Zyklus_Sa 0 "Timer_am_Wochentag_nicht_aktiv" 1 "Timer_am_Wochentag_aktiv" ;
VAL_ 1397 HVLM_Status_Timer_1_Zyklus_So 0 "Timer_am_Wochentag_nicht_aktiv" 1 "Timer_am_Wochentag_aktiv" ;
VAL_ 1397 HVLM_Status_Timer_2_Zyklus_So 0 "Timer_am_Wochentag_nicht_aktiv" 1 "Timer_am_Wochentag_aktiv" ;
VAL_ 1397 HVLM_Status_Timer_3_Zyklus_So 0 "Timer_am_Wochentag_nicht_aktiv" 1 "Timer_am_Wochentag_aktiv" ;
VAL_ 1397 HVLM_Status_Timer_1_Zyklus_WH 0 "zyklisch" 1 "einmalig" ;
VAL_ 1397 HVLM_Status_Timer_2_Zyklus_WH 0 "zyklisch" 1 "einmalig" ;
VAL_ 1397 HVLM_Status_Timer_MUX 0 "leer" 1 "Abfahrtstimer_1" 2 "Abfahrtstimer_2" 3 "Abfahrtstimer_3" 4 "Klimatimer_1" 5 "Klimatimer_2" 6 "Klimatimer_3" 7 "Timer_7" ;
VAL_ 1397 HVLM_Status_Timer_3_Zyklus_WH 0 "zyklisch" 1 "einmalig" ;
VAL_ 1397 HVLM_Status_Nachtstrom_X_Std_Anf 62 "Init" 63 "ungueltig" ;
VAL_ 1397 HVLM_Status_Nachtstrom_Prof 0 "keine_Aktion" 1 "Profil_1_setzen" 2 "Profil_2_setzen" 3 "Profil_3_setzen" ;
VAL_ 1397 HVLM_Status_Nachtstrom_X_Std_End 62 "Init" 63 "ungueltig" ;
VAL_ 1397 HVLM_Status_Nachtstrom_Akt_Prof 0 "kein_Profil_gesetzt" 1 "Profil_1_aktiv" 2 "Profil_2_aktiv" 3 "Profil_3_aktiv" ;
VAL_ 1397 HVLM_Status_Laden 0 "Ladefehler" 1 "Laden_aktv" 2 "Laden_unterbrochen" 3 "Laden_beendet" 4 "Ladung_extern_unterbrochen" 5 "Ladung_standby" 6 "Init" 7 "Fehler" ;
VAL_ 1397 HVLM_Status_Timer_4_Zyklus_Di 0 "Timer_am_Wochentag_nicht_aktiv" 1 "Timer_am_Wochentag_aktiv" ;
VAL_ 1397 HVLM_Status_Timer_4_Zyklus_Mi 0 "Timer_am_Wochentag_nicht_aktiv" 1 "Timer_am_Wochentag_aktiv" ;
VAL_ 1397 HVLM_Status_Timer_4_Zyklus_Do 0 "Timer_am_Wochentag_nicht_aktiv" 1 "Timer_am_Wochentag_aktiv" ;
VAL_ 1397 HVLM_Status_Timer_4_Zyklus_Fr 0 "Timer_am_Wochentag_nicht_aktiv" 1 "Timer_am_Wochentag_aktiv" ;
VAL_ 1397 HVLM_Status_Timer_1_Jahr 126 "Init" 127 "reserviert" ;
VAL_ 1397 HVLM_Status_Timer_2_Jahr 126 "Init" 127 "reserviert" ;
VAL_ 1397 HVLM_Status_Timer_3_Jahr 126 "Init" 127 "reserviert" ;
VAL_ 1397 HVLM_Status_Timer_7_Jahr 126 "Init" 127 "reserviert" ;
VAL_ 1397 HVLM_Status_Timer_1_Minute 60 "reserviert" 61 "reserviert" 62 "Init" 63 "Fehler" ;
VAL_ 1397 HVLM_Status_Timer_2_Minute 60 "reserviert" 61 "reserviert" 62 "Init" 63 "Fehler" ;
VAL_ 1397 HVLM_Status_Timer_3_Minute 60 "reserviert" 61 "reserviert" 62 "Init" 63 "Fehler" ;
VAL_ 1397 HVLM_Status_Timer_7_Minute 60 "reserviert" 61 "reserviert" 62 "Init" 63 "Fehler" ;
VAL_ 1397 HVLM_Status_Timer_1_Monat 0 "Init" 14 "reserviert" 15 "Fehler" ;
VAL_ 1397 HVLM_Status_Timer_2_Monat 0 "Init" 14 "reserviert" 15 "Fehler" ;
VAL_ 1397 HVLM_Status_Timer_3_Monat 0 "Init" 14 "reserviert" 15 "Fehler" ;
VAL_ 1397 HVLM_Status_Timer_7_Monat 0 "Init" 14 "reserviert" 15 "Fehler" ;
VAL_ 1397 HVLM_Status_Timer_1_Stunde 24 "reserviert" 25 "reserviert" 26 "reserviert" 27 "reserviert" 28 "reserviert" 29 "reserviert" 30 "Init" 31 "Fehler" ;
VAL_ 1397 HVLM_Status_Timer_2_Stunde 24 "reserviert" 25 "reserviert" 26 "reserviert" 27 "reserviert" 28 "reserviert" 29 "reserviert" 30 "Init" 31 "Fehler" ;
VAL_ 1397 HVLM_Status_Timer_3_Stunde 24 "reserviert" 25 "reserviert" 26 "reserviert" 27 "reserviert" 28 "reserviert" 29 "reserviert" 30 "Init" 31 "Fehler" ;
VAL_ 1397 HVLM_Status_Timer_7_Stunde 24 "reserviert" 25 "reserviert" 26 "reserviert" 27 "reserviert" 28 "reserviert" 29 "reserviert" 30 "Init" 31 "Fehler" ;
VAL_ 1397 HVLM_Status_Timer_1_Tag 0 "Init" ;
VAL_ 1397 HVLM_Status_Timer_2_Tag 0 "Init" ;
VAL_ 1397 HVLM_Status_Timer_3_Tag 0 "Init" ;
VAL_ 1397 HVLM_Status_Timer_7_Tag 0 "Init" ;
VAL_ 1397 HVLM_Status_Timer_1_Laden 0 "Timer_nicht_aktiv" 1 "Timer_aktiv" ;
VAL_ 1397 HVLM_Status_Timer_2_Laden 0 "Timer_nicht_aktiv" 1 "Timer_aktiv" ;
VAL_ 1397 HVLM_Status_Timer_3_Laden 0 "Timer_nicht_aktiv" 1 "Timer_aktiv" ;
VAL_ 1397 HVLM_Status_Timer_1_Vorklima 0 "Timer_nicht_aktiv" 1 "Timer_aktiv" ;
VAL_ 1397 HVLM_Status_Timer_4_Zyklus_Sa 0 "Timer_am_Wochentag_nicht_aktiv" 1 "Timer_am_Wochentag_aktiv" ;
VAL_ 1397 HVLM_Status_Timer_4_Zyklus_So 0 "Timer_am_Wochentag_nicht_aktiv" 1 "Timer_am_Wochentag_aktiv" ;
VAL_ 1397 HVLM_Status_Timer_4_Zyklus_WH 0 "zyklisch" 1 "einmalig" ;
